VERSION "HNNBNNNYNNNNNNNNNNNNNNNNNNNNNNNNNNNNNNNNNN/4/%%%/4/'%**4NNN///"

NS_ :

BS_:

BU_: AAG BCM1 BCM2 ELV Gateway HDSG IEZS MFG MSBBR SAD SAD2 Schwerpanzer_Zusatz SitzMem_BFS SitzMem_FS SitzMem_HBFS SitzMem_HFS SitzMem_SR3 SpoilerSG TSG_BFS TSG_FS VSG VTS DK_Dummy

BO_ 1639 Mem_BFS_01: 8 SitzMem_BFS
 SG_ BFS_Fond_Bed_Ack : 12|1@1+ (1,0) [0|1] ""  Gateway
 SG_ BFS_Lehne_nicht_verriegelt : 13|1@1+ (1,0) [0|1] ""  Gateway
 SG_ BFS_Klapptisch_offen : 14|1@1+ (1,0) [0|1] ""  Gateway,SitzMem_FS
 SG_ BFS_Sitzsym_Fahrt_aktiv : 16|1@1+ (1,0) [0|1] ""  Gateway,SitzMem_FS
 SG_ BFS_Sitzfahrt_aktiv : 17|1@1+ (1,0) [0|1] ""  Gateway,SitzMem_FS,SitzMem_HBFS
 SG_ BFS_SLV_aktiv : 18|1@1+ (1,0) [0|1] ""  Gateway
 SG_ BFS_SHV_aktiv : 19|1@1+ (1,0) [0|1] ""  Gateway
 SG_ BFS_LNV_aktiv : 20|1@1+ (1,0) [0|1] ""  Gateway
 SG_ BFS_SNV_aktiv : 21|1@1+ (1,0) [0|1] ""  Gateway
 SG_ BFS_KSV_aktiv : 22|1@1+ (1,0) [0|1] ""  Gateway
 SG_ BFS_LKV_aktiv : 23|1@1+ (1,0) [0|1] ""  Gateway
 SG_ BFS_STV_aktiv : 24|1@1+ (1,0) [0|1] ""  Gateway
 SG_ BFS_LHV_aktiv : 25|1@1+ (1,0) [0|1] ""  Gateway
 SG_ BFS_LWV_aktiv : 26|1@1+ (1,0) [0|1] ""  Gateway
 SG_ BFS_GHV_aktiv : 27|1@1+ (1,0) [0|1] ""  Gateway
 SG_ BFS_KSS_Fahrt_aktiv : 28|1@1+ (1,0) [0|1] ""  Gateway,SitzMem_FS
 SG_ BFS_MMB_lokal_Stop : 29|1@1+ (1,0) [0|1] ""  Gateway
 SG_ BFS_Ruhestellung_Status : 30|1@1+ (1,0) [0|1] ""  Gateway,SitzMem_FS,SitzMem_HBFS
 SG_ BFS_Seat_Locked : 31|1@1+ (1,0) [0|1] ""  Gateway
 SG_ BFS_MMB_storage : 32|4@1+ (1,0) [0|15] ""  Gateway
 SG_ BFS_MMB_tipp : 36|1@1+ (1,0) [0|1] ""  Gateway
 SG_ BFS_MMB_tast : 37|1@1+ (1,0) [0|1] ""  Gateway
 SG_ BFS_MMB_store_LED_on : 38|1@1+ (1,0) [0|1] ""  Gateway,TSG_BFS
 SG_ BFS_MMB_storage_beep : 39|1@1+ (1,0) [0|1] ""  Gateway
 SG_ BFS_MMB_store : 40|1@1+ (1,0) [0|1] ""  Gateway
 SG_ BFS_MMB_glob_stop : 41|1@1+ (1,0) [0|1] ""  Gateway

BO_ 957 Mem_BFS_Fond_01: 8 SitzMem_HBFS
 SG_ Mem_BFSFo_Lordose_hoch : 12|1@1+ (1,0) [0|1] ""  Gateway
 SG_ Mem_BFSFo_Lordose_runter : 13|1@1+ (1,0) [0|1] ""  Gateway
 SG_ Mem_BFSFo_Lordose_vor : 14|1@1+ (1,0) [0|1] ""  Gateway
 SG_ Mem_BFSFo_Lordose_zurueck : 15|1@1+ (1,0) [0|1] ""  Gateway
 SG_ Mem_BFSFo_Massage_Geschw : 16|3@1+ (1,0) [0|7] ""  Gateway,SitzMem_FS
 SG_ Mem_BFSFo_Massage_Intens : 19|3@1+ (1,0) [0|7] ""  Gateway,SitzMem_FS
 SG_ Mem_BFSFo_MMB_storage : 22|2@1+ (1,0) [0|3] ""  Gateway
 SG_ Mem_BFSFo_Massage_Prg : 24|3@1+ (1,0) [0|7] ""  Gateway,SitzMem_FS
 SG_ Mem_BFSFo_MMB_tast : 27|1@1+ (1,0) [0|1] ""  Gateway
 SG_ Mem_BFSFo_MMB_tipp : 28|1@1+ (1,0) [0|1] ""  Gateway
 SG_ Mem_BFSFo_MMB_glob_Stop : 29|1@1+ (1,0) [0|1] ""  Gateway
 SG_ Mem_BFSFo_Sitztiefe_vor : 30|1@1+ (1,0) [0|1] ""  Gateway
 SG_ Mem_BFSFo_Sitztiefe_zur : 31|1@1+ (1,0) [0|1] ""  Gateway
 SG_ Mem_BFSFo_MMB_store : 32|1@1+ (1,0) [0|1] ""  Gateway
 SG_ Mem_BFSFo_MMB_storage_beep : 33|1@1+ (1,0) [0|1] ""  Gateway
 SG_ Mem_BFSFo_MMB_store_LED_on : 34|1@1+ (1,0) [0|1] ""  Gateway,TSG_BFS,TSG_FS
 SG_ Mem_BFSFo_BeifaSitzverstellung : 35|1@1+ (1,0) [0|1] ""  Gateway
 SG_ Mem_BFSFo_MMB_lokal_Stop : 36|1@1+ (1,0) [0|1] ""  Gateway
 SG_ Mem_BFSFo_Sitzfahrt_aktiv : 37|1@1+ (1,0) [0|1] ""  Gateway,SitzMem_BFS,SitzMem_FS
 SG_ Mem_BFSFo_BFS_Freigabe : 38|1@1+ (1,0) [0|1] ""  Gateway,SitzMem_BFS
 SG_ Mem_BFSFo_RSE_zurueck : 40|1@1+ (1,0) [0|1] ""  Gateway,SitzMem_BFS
 SG_ Mem_BFSFo_RSE_vor : 41|1@1+ (1,0) [0|1] ""  Gateway,SitzMem_BFS
 SG_ Mem_BFSFo_Business_anfahren : 42|1@1+ (1,0) [0|1] ""  Gateway,SitzMem_BFS
 SG_ Mem_BFSFo_Relax_anfahren : 43|1@1+ (1,0) [0|1] ""  Gateway,SitzMem_BFS
 SG_ BFS_Kopfstuetze_vor : 44|1@1+ (1,0) [0|1] ""  Gateway,SitzMem_BFS
 SG_ BFS_Kopfstuetze_zurueck : 45|1@1+ (1,0) [0|1] ""  Gateway,SitzMem_BFS
 SG_ Mem_BFSFo_BFS_RSE_Freigabe : 48|1@1+ (1,0) [0|1] ""  Gateway,SitzMem_BFS
 SG_ Mem_BFSFo_Fusstuetze_runter : 49|1@1+ (1,0) [0|1] ""  Gateway,SitzMem_BFS
 SG_ Mem_BFSFo_Fusstuetze_hoch : 50|1@1+ (1,0) [0|1] ""  Gateway,SitzMem_BFS

BO_ 1178 Mem_FS_01: 8 SitzMem_FS
 SG_ FS_Fond_Bed_enable : 12|1@1+ (1,0) [0|1] ""  Gateway,SitzMem_BFS,SitzMem_HBFS
 SG_ FS_Lehne_nicht_verriegelt : 13|1@1+ (1,0) [0|1] ""  Gateway
 SG_ FS_Spezialposition_anfahren : 14|1@1+ (1,0) [0|1] ""  Gateway,SitzMem_BFS,SitzMem_HBFS,SitzMem_HFS
 SG_ FS_BFS_Sitzsym_Anfahrt : 16|1@1+ (1,0) [0|1] ""  Gateway,SitzMem_BFS
 SG_ FS_Sitzfahrt_aktiv : 17|1@1+ (1,0) [0|1] ""  BCM1,Gateway,TSG_BFS,TSG_FS
 SG_ FS_SLV_aktiv : 18|1@1+ (1,0) [0|1] ""  Gateway
 SG_ FS_SHV_aktiv : 19|1@1+ (1,0) [0|1] ""  Gateway
 SG_ FS_LNV_aktiv : 20|1@1+ (1,0) [0|1] ""  Gateway
 SG_ FS_SNV_aktiv : 21|1@1+ (1,0) [0|1] ""  Gateway
 SG_ FS_KSV_aktiv : 22|1@1+ (1,0) [0|1] ""  Gateway
 SG_ FS_LKV_aktiv : 23|1@1+ (1,0) [0|1] ""  Gateway
 SG_ FS_STV_aktiv : 24|1@1+ (1,0) [0|1] ""  Gateway
 SG_ FS_LHV_aktiv : 25|1@1+ (1,0) [0|1] ""  Gateway
 SG_ FS_LWV_aktiv : 26|1@1+ (1,0) [0|1] ""  Gateway
 SG_ FS_GHV_aktiv : 27|1@1+ (1,0) [0|1] ""  Gateway
 SG_ FS_BFS_KSS_Anfahrt : 28|1@1+ (1,0) [0|1] ""  Gateway,SitzMem_BFS
 SG_ FS_MMB_lokal_Stop : 29|1@1+ (1,0) [0|1] ""  Gateway
 SG_ FS_MMB_storage : 32|4@1+ (1,0) [0|15] ""  BCM1,Gateway,TSG_BFS,TSG_FS
 SG_ FS_MMB_tipp : 36|1@1+ (1,0) [0|1] ""  BCM1,Gateway,TSG_BFS,TSG_FS
 SG_ FS_MMB_tast : 37|1@1+ (1,0) [0|1] ""  BCM1,Gateway,TSG_BFS,TSG_FS
 SG_ FS_MMB_store_LED_on : 38|1@1+ (1,0) [0|1] ""  Gateway,TSG_FS
 SG_ FS_MMB_storage_beep : 39|1@1+ (1,0) [0|1] ""  Gateway
 SG_ FS_MMB_store : 40|1@1+ (1,0) [0|1] ""  BCM1,Gateway,TSG_BFS,TSG_FS
 SG_ FS_MMB_glob_stop : 41|1@1+ (1,0) [0|1] ""  BCM1,Gateway,SitzMem_BFS,SitzMem_HBFS,SitzMem_HFS,TSG_BFS,TSG_FS
 SG_ FS_EE_Fond_FS_enable : 42|1@1+ (1,0) [0|1] ""  Gateway,SitzMem_HBFS,SitzMem_HFS
 SG_ FS_EE_Fond_BFS_enable : 43|1@1+ (1,0) [0|1] ""  Gateway,SitzMem_HBFS,SitzMem_HFS
 SG_ FS_BFS_Fond_Verst_enable : 44|1@1+ (1,0) [0|1] ""  Gateway,SitzMem_BFS,SitzMem_HBFS
 SG_ FS_EE_BFS_enable : 45|1@1+ (1,0) [0|1] ""  Gateway

BO_ 954 Mem_FS_02: 8 SitzMem_FS
 SG_ Mem_FS_Lordose_hoch : 12|1@1+ (1,0) [0|1] "" Vector__XXX
 SG_ Mem_FS_Lordose_runter : 13|1@1+ (1,0) [0|1] "" Vector__XXX
 SG_ Mem_FS_Lordose_vor : 14|1@1+ (1,0) [0|1] "" Vector__XXX
 SG_ Mem_FS_Lordose_zurueck : 15|1@1+ (1,0) [0|1] "" Vector__XXX
 SG_ Mem_FS_Massage_Geschw : 16|3@1+ (1,0) [0|7] "" Vector__XXX
 SG_ Mem_FS_Massage_Intensitaet : 19|3@1+ (1,0) [0|7] "" Vector__XXX
 SG_ Mem_FS_SWangenLehne_beluef : 22|1@1+ (1,0) [0|1] "" Vector__XXX
 SG_ Mem_FS_SWangenLehne_entlue : 23|1@1+ (1,0) [0|1] "" Vector__XXX
 SG_ Mem_FS_Massage_Programm : 24|3@1+ (1,0) [0|7] "" Vector__XXX
 SG_ Mem_FS_SWangenSitz_beluef : 27|1@1+ (1,0) [0|1] "" Vector__XXX
 SG_ Mem_FS_SWangenSitz_entlue : 28|1@1+ (1,0) [0|1] "" Vector__XXX
 SG_ FS_BFS_aufraeumen : 29|1@1+ (1,0) [0|1] ""  SitzMem_BFS
 SG_ FS_BFSFo_aufraeumen : 30|1@1+ (1,0) [0|1] ""  SitzMem_HBFS
 SG_ FS_FSFo_aufraeumen : 31|1@1+ (1,0) [0|1] ""  SitzMem_HFS
 SG_ FS_BFS_Multifunktionstaster_hoch : 32|1@1+ (1,0) [0|1] ""  SitzMem_BFS
 SG_ FS_BFS_Multifunktionstaster_tief : 33|1@1+ (1,0) [0|1] ""  SitzMem_BFS
 SG_ FS_BFS_Multifunktionstaster_vor : 34|1@1+ (1,0) [0|1] ""  SitzMem_BFS
 SG_ FS_BFS_Multifunktionstaster_zur : 35|1@1+ (1,0) [0|1] ""  SitzMem_BFS
 SG_ FS_BFS_Programmwippe_hoch : 36|1@1+ (1,0) [0|1] ""  SitzMem_BFS
 SG_ FS_BFS_Programmwippe_tief : 37|1@1+ (1,0) [0|1] ""  SitzMem_BFS
 SG_ FS_BFS_SHV_Taste_hoch : 38|1@1+ (1,0) [0|1] ""  SitzMem_BFS
 SG_ FS_BFS_SHV_Taste_tief : 39|1@1+ (1,0) [0|1] ""  SitzMem_BFS
 SG_ FS_BFS_SLV_Taste_vor : 40|1@1+ (1,0) [0|1] ""  SitzMem_BFS
 SG_ FS_BFS_SLV_Taste_zurueck : 41|1@1+ (1,0) [0|1] ""  SitzMem_BFS
 SG_ FS_BFS_SNV_Taste_hoch : 42|1@1+ (1,0) [0|1] ""  SitzMem_BFS
 SG_ FS_BFS_SNV_Taste_tief : 43|1@1+ (1,0) [0|1] ""  SitzMem_BFS
 SG_ FS_BFS_KSV_Taste_hoch : 44|1@1+ (1,0) [0|1] ""  SitzMem_BFS
 SG_ FS_BFS_KSV_Taste_tief : 45|1@1+ (1,0) [0|1] ""  SitzMem_BFS
 SG_ FS_BFS_LNV_Taste_vor : 46|1@1+ (1,0) [0|1] ""  SitzMem_BFS
 SG_ FS_BFS_LNV_Taste_zurueck : 47|1@1+ (1,0) [0|1] ""  SitzMem_BFS
 SG_ FS_BFS_Massage_Taste : 48|1@1+ (1,0) [0|1] ""  SitzMem_BFS

BO_ 956 Mem_FS_Fond_01: 8 SitzMem_HFS
 SG_ Mem_FSFo_Lordose_hoch : 12|1@1+ (1,0) [0|1] ""  Gateway
 SG_ Mem_FSFo_Lordose_runter : 13|1@1+ (1,0) [0|1] ""  Gateway
 SG_ Mem_FSFo_Lordose_vor : 14|1@1+ (1,0) [0|1] ""  Gateway
 SG_ Mem_FSFo_Lordose_zurueck : 15|1@1+ (1,0) [0|1] ""  Gateway
 SG_ Mem_FSFo_Massage_Geschw : 16|3@1+ (1,0) [0|7] ""  Gateway,SitzMem_FS
 SG_ Mem_FSFo_Massage_Intens : 19|3@1+ (1,0) [0|7] ""  Gateway,SitzMem_FS
 SG_ Mem_FSFo_MMB_storage : 22|2@1+ (1,0) [0|3] ""  Gateway
 SG_ Mem_FSFo_Massage_Prg : 24|3@1+ (1,0) [0|7] ""  Gateway,SitzMem_FS
 SG_ Mem_FSFo_MMB_tast : 27|1@1+ (1,0) [0|1] ""  Gateway
 SG_ Mem_FSFo_MMB_tipp : 28|1@1+ (1,0) [0|1] ""  Gateway
 SG_ Mem_FSFo_MMB_glob_Stop : 29|1@1+ (1,0) [0|1] ""  Gateway
 SG_ Mem_FSFo_Sitztiefe_vor : 30|1@1+ (1,0) [0|1] ""  Gateway
 SG_ Mem_FSFo_Sitztiefe_zur : 31|1@1+ (1,0) [0|1] ""  Gateway
 SG_ Mem_FSFo_MMB_store : 32|1@1+ (1,0) [0|1] ""  Gateway
 SG_ Mem_FSFo_MMB_storage_beep : 33|1@1+ (1,0) [0|1] ""  Gateway
 SG_ Mem_FSFo_MMB_store_LED_on : 34|1@1+ (1,0) [0|1] ""  Gateway,TSG_BFS,TSG_FS
 SG_ Mem_FSFo_MMB_lokal_Stop : 36|1@1+ (1,0) [0|1] ""  Gateway
 SG_ Mem_FSFo_Sitzfahrt_aktiv : 37|1@1+ (1,0) [0|1] ""  Gateway,SitzMem_FS
 SG_ Mem_FSFo_Business_anfahren : 42|1@1+ (1,0) [0|1] ""  Gateway
 SG_ Mem_FSFo_Relax_anfahren : 43|1@1+ (1,0) [0|1] ""  Gateway

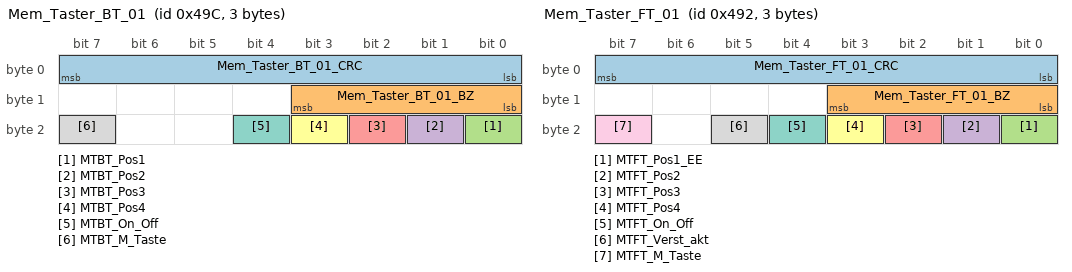
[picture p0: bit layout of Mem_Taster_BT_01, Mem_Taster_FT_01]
BO_ 1180 Mem_Taster_BT_01: 3 TSG_BFS
 SG_ Mem_Taster_BT_01_CRC : 0|8@1+ (1,0) [0|255] ""  SitzMem_BFS,SitzMem_FS
 SG_ Mem_Taster_BT_01_BZ : 8|4@1+ (1,0) [0|15] ""  SitzMem_BFS,SitzMem_FS
 SG_ MTBT_Pos1 : 16|1@1+ (1,0) [0|1] ""  SitzMem_BFS,SitzMem_FS,SitzMem_HBFS
 SG_ MTBT_Pos2 : 17|1@1+ (1,0) [0|1] ""  SitzMem_BFS,SitzMem_FS,SitzMem_HBFS
 SG_ MTBT_Pos3 : 18|1@1+ (1,0) [0|1] ""  SitzMem_BFS,SitzMem_FS,SitzMem_HBFS
 SG_ MTBT_Pos4 : 19|1@1+ (1,0) [0|1] ""  SitzMem_BFS,SitzMem_FS
 SG_ MTBT_On_Off : 20|1@1+ (1,0) [0|1] ""  SitzMem_BFS,SitzMem_FS
 SG_ MTBT_M_Taste : 23|1@1+ (1,0) [0|1] ""  SitzMem_BFS,SitzMem_FS,SitzMem_HBFS

BO_ 1170 Mem_Taster_FT_01: 3 TSG_FS
 SG_ Mem_Taster_FT_01_CRC : 0|8@1+ (1,0) [0|255] ""  SitzMem_FS
 SG_ Mem_Taster_FT_01_BZ : 8|4@1+ (1,0) [0|15] ""  SitzMem_FS
 SG_ MTFT_Pos1_EE : 16|1@1+ (1,0) [0|1] ""  SitzMem_FS
 SG_ MTFT_Pos2 : 17|1@1+ (1,0) [0|1] ""  SitzMem_FS
 SG_ MTFT_Pos3 : 18|1@1+ (1,0) [0|1] ""  SitzMem_FS
 SG_ MTFT_Pos4 : 19|1@1+ (1,0) [0|1] ""  SitzMem_FS
 SG_ MTFT_On_Off : 20|1@1+ (1,0) [0|1] ""  SitzMem_FS
 SG_ MTFT_Verst_akt : 21|1@1+ (1,0) [0|1] ""  SitzMem_FS
 SG_ MTFT_M_Taste : 23|1@1+ (1,0) [0|1] ""  SitzMem_FS

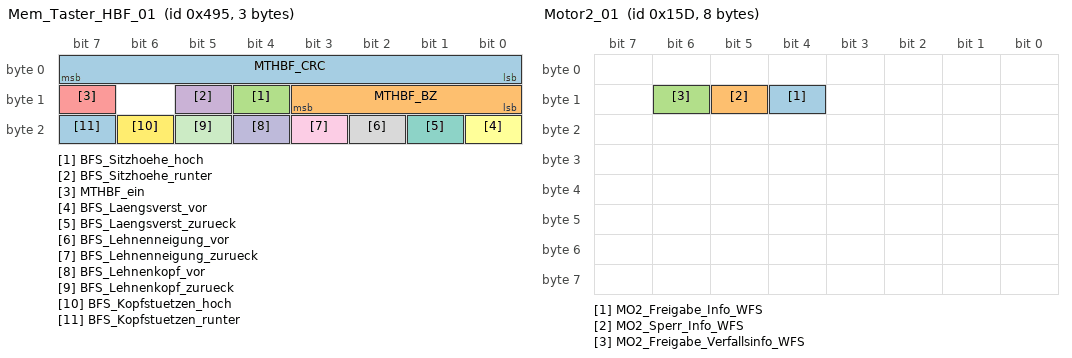
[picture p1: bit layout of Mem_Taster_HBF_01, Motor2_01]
BO_ 1173 Mem_Taster_HBF_01: 3 SitzMem_HBFS
 SG_ MTHBF_CRC : 0|8@1+ (1,0) [0|255] ""  SitzMem_BFS
 SG_ MTHBF_BZ : 8|4@1+ (1,0) [0|15] ""  SitzMem_BFS
 SG_ BFS_Sitzhoehe_hoch : 12|1@1+ (1,0) [0|1] ""  SitzMem_BFS
 SG_ BFS_Sitzhoehe_runter : 13|1@1+ (1,0) [0|1] ""  SitzMem_BFS
 SG_ MTHBF_ein : 15|1@1+ (1,0) [0|1] ""  SitzMem_BFS
 SG_ BFS_Laengsverst_vor : 16|1@1+ (1,0) [0|1] ""  SitzMem_BFS
 SG_ BFS_Laengsverst_zurueck : 17|1@1+ (1,0) [0|1] ""  SitzMem_BFS
 SG_ BFS_Lehnenneigung_vor : 18|1@1+ (1,0) [0|1] ""  SitzMem_BFS
 SG_ BFS_Lehnenneigung_zurueck : 19|1@1+ (1,0) [0|1] ""  SitzMem_BFS
 SG_ BFS_Lehnenkopf_vor : 20|1@1+ (1,0) [0|1] ""  SitzMem_BFS
 SG_ BFS_Lehnenkopf_zurueck : 21|1@1+ (1,0) [0|1] ""  SitzMem_BFS
 SG_ BFS_Kopfstuetzen_hoch : 22|1@1+ (1,0) [0|1] ""  SitzMem_BFS
 SG_ BFS_Kopfstuetzen_runter : 23|1@1+ (1,0) [0|1] ""  SitzMem_BFS

BO_ 1171 MFG_01: 8 MFG
 SG_ MFG_01_CRC : 0|8@1+ (1,0) [0|255] ""  BCM1,BCM2,Gateway,TSG_FS
 SG_ MFG_01_BZ : 8|4@1+ (1,0) [0|15] ""  BCM1,BCM2,Gateway,TSG_FS
 SG_ MF_ZV_Lock : 12|1@1+ (1,0) [0|1] ""  BCM2,Gateway
 SG_ MF_Motorweiterlauf : 13|1@1+ (1,0) [0|1] ""  BCM2,Gateway
 SG_ MF_Abzugssperre : 14|1@1+ (1,0) [0|1] ""  BCM2,Gateway
 SG_ MF_Anlassersperre : 15|1@1+ (1,0) [0|1] ""  BCM2,Gateway
 SG_ MF_Variante : 16|3@1+ (1,0) [0|7] ""  BCM1,BCM2,Gateway,TSG_BFS,TSG_FS
 SG_ MF_Schluessel_scan : 19|1@1+ (1,0) [0|1] ""  Gateway
 SG_ MF_Laderelais : 20|1@1+ (1,0) [0|1] ""  Gateway
 SG_ MF_StartStopp_Info : 21|2@1+ (1,0) [0|3] ""  Gateway
 SG_ MF_Fernbed_ein : 23|1@1+ (1,0) [0|1] ""  BCM1,BCM2,Gateway,TSG_BFS,TSG_FS
 SG_ MF_Standlicht : 24|1@1+ (1,0) [0|1] ""  BCM1,Gateway
 SG_ MF_Fahrlicht : 25|1@1+ (1,0) [0|1] ""  BCM1,Gateway
 SG_ MF_interm_Fernlicht : 26|1@1+ (1,0) [0|1] ""  BCM1,Gateway
 SG_ MF_Warnblinker : 27|1@1+ (1,0) [0|1] ""  BCM1,BCM2,Gateway
 SG_ MF_Fussraumbel : 28|1@1+ (1,0) [0|1] ""  BCM1,Gateway,TSG_FS
 SG_ MF_Innenraumbel : 29|1@1+ (1,0) [0|1] ""  BCM1,Gateway,TSG_BFS,TSG_FS
 SG_ MF_Innenraumbel_Unterdrueck : 30|1@1+ (1,0) [0|1] ""  BCM1,Gateway,TSG_BFS,TSG_FS
 SG_ MF_Notstart : 31|1@1+ (1,0) [0|1] ""  Gateway
 SG_ MF_Blk_li : 32|1@1+ (1,0) [0|1] ""  BCM2,Gateway
 SG_ MF_Blk_re : 33|1@1+ (1,0) [0|1] ""  BCM2,Gateway
 SG_ MF_Lichthupe : 34|1@1+ (1,0) [0|1] ""  BCM1,Gateway
 SG_ MF_Fernlicht : 35|1@1+ (1,0) [0|1] ""  BCM1,Gateway
 SG_ MF_HFS_verriegeln : 36|1@1+ (1,0) [0|1] ""  Gateway,TSG_FS
 SG_ MF_HFS_entriegeln : 37|1@1+ (1,0) [0|1] ""  Gateway,TSG_FS
 SG_ MF_HBFS_verriegeln : 38|1@1+ (1,0) [0|1] ""  Gateway,TSG_BFS
 SG_ MF_HBFS_entriegeln : 39|1@1+ (1,0) [0|1] ""  Gateway,TSG_BFS
 SG_ MF_Tippwischen : 40|1@1+ (1,0) [0|1] ""  BCM1,Gateway
 SG_ MF_Frontintervall : 41|1@1+ (1,0) [0|1] ""  BCM1,Gateway
 SG_ MF_Wischerstufe_1 : 42|1@1+ (1,0) [0|1] ""  BCM1,Gateway
 SG_ MF_Wischerstufe_2 : 43|1@1+ (1,0) [0|1] ""  BCM1,Gateway
 SG_ MF_Frontwaschen : 44|1@1+ (1,0) [0|1] ""  BCM1,Gateway
 SG_ MF_Heckintervall : 46|1@1+ (1,0) [0|1] ""  BCM1,Gateway
 SG_ MF_Heckwaschen : 47|1@1+ (1,0) [0|1] ""  BCM1,Gateway
 SG_ MF_Summer : 48|1@1+ (1,0) [0|1] ""  Gateway
 SG_ MF_Alarm_Blinkertakt : 49|1@1+ (1,0) [0|1] ""  Gateway
 SG_ MF_Alarm_Blinker : 50|1@1+ (1,0) [0|1] ""  BCM2,Gateway,VTS
 SG_ MF_TFL_Abschaltung : 51|1@1+ (1,0) [0|1] ""  BCM1,Gateway
 SG_ MF_interm_Takt : 52|1@1+ (1,0) [0|1] ""  Gateway
 SG_ MF_Tuerentriegelung_hinten : 53|1@1+ (1,0) [0|1] ""  Gateway
 SG_ MF_interm_Fahrlicht : 54|1@1+ (1,0) [0|1] ""  Gateway
 SG_ MF_Signalhorn : 55|1@1+ (1,0) [0|1] ""  BCM1,Gateway
 SG_ MF_FH_FT_hoch : 56|1@1+ (1,0) [0|1] ""  Gateway,TSG_FS
 SG_ MF_FH_FT_tief : 57|1@1+ (1,0) [0|1] ""  Gateway,TSG_FS
 SG_ MF_FH_BT_hoch : 58|1@1+ (1,0) [0|1] ""  Gateway,TSG_BFS
 SG_ MF_FH_BT_tief : 59|1@1+ (1,0) [0|1] ""  Gateway,TSG_BFS
 SG_ MF_FT_verriegeln : 60|1@1+ (1,0) [0|1] ""  Gateway,TSG_FS
 SG_ MF_FT_entriegeln : 61|1@1+ (1,0) [0|1] ""  Gateway,TSG_FS
 SG_ MF_BT_verriegeln : 62|1@1+ (1,0) [0|1] ""  Gateway,TSG_BFS
 SG_ MF_BT_entriegeln : 63|1@1+ (1,0) [0|1] ""  Gateway,TSG_BFS

BO_ 817 MFL_01: 8 Gateway
 SG_ MFL_Zaehler : 0|4@1+ (1,0) [0|15] "" Vector__XXX
 SG_ MFL_Toggle : 4|1@1+ (1,0) [0|1] "" Vector__XXX
 SG_ MFL_Lokalaktiv : 5|1@1+ (1,0) [0|1] "" Vector__XXX
 SG_ MFL_M_Taste : 6|1@1+ (1,0) [0|1] "" Vector__XXX
 SG_ MFL_Tastencode_1 : 8|8@1+ (1,0) [0|255] "" Vector__XXX
 SG_ MFL_Tastencode_2 : 16|8@1+ (1,0) [0|255] "" Vector__XXX
 SG_ MFL_Eventcode_1 : 24|4@1+ (1,0) [0|15] "" Vector__XXX
 SG_ MFL_Eventcode_2 : 28|4@1+ (1,0) [0|15] "" Vector__XXX
 SG_ MFL_Marke : 32|4@1+ (1,0) [0|15] "" Vector__XXX
 SG_ MFL_Variante : 36|4@1+ (1,0) [0|15] "" Vector__XXX
 SG_ MFL_Dummy_0_Signal_1 : 40|8@1+ (1,0) [0|255] "" Vector__XXX
 SG_ MFL_Tip_Down : 48|1@1+ (1,0) [0|1] "" Vector__XXX
 SG_ MFL_Tip_Up : 49|1@1+ (1,0) [0|1] "" Vector__XXX
 SG_ MFL_SatModul_links_Err : 50|1@1+ (1,0) [0|1] "" Vector__XXX
 SG_ MFL_SatModul_rechts_Err : 51|1@1+ (1,0) [0|1] "" Vector__XXX
 SG_ MFL_Dummy_0_Signal_2 : 52|1@1+ (1,0) [0|1] "" Vector__XXX
 SG_ MFL_Dummy_0_Signal_3 : 53|1@1+ (1,0) [0|1] "" Vector__XXX
 SG_ MFL_LR_HZG_Status : 54|1@1+ (1,0) [0|1] "" Vector__XXX
 SG_ MFL_LR_HZG_Err : 55|1@1+ (1,0) [0|1] "" Vector__XXX
 SG_ MFL_Signalhorn : 56|1@1+ (1,0) [0|1] ""  BCM1,MFG
 SG_ MFL_Signalhorn_Err : 57|1@1+ (1,0) [0|1] "" Vector__XXX
 SG_ MFL_Tip_links_Err : 58|1@1+ (1,0) [0|1] "" Vector__XXX
 SG_ MFL_Tip_rechts_Err : 59|1@1+ (1,0) [0|1] "" Vector__XXX
 SG_ MFL_Taste_links_Err : 60|1@1+ (1,0) [0|1] "" Vector__XXX
 SG_ MFL_Taste_rechts_Err : 61|1@1+ (1,0) [0|1] "" Vector__XXX
 SG_ MFL_ECU_Err : 62|1@1+ (1,0) [0|1] "" Vector__XXX
 SG_ MFL_Response_Err : 63|1@1+ (1,0) [0|1] "" Vector__XXX

BO_ 349 Motor2_01: 8 Gateway
 SG_ MO2_Freigabe_Info_WFS : 12|1@1+ (1,0) [0|1] ""  BCM2
 SG_ MO2_Sperr_Info_WFS : 13|1@1+ (1,0) [0|1] ""  BCM2
 SG_ MO2_Freigabe_Verfallsinfo_WFS : 14|1@1+ (1,0) [0|1] ""  BCM2

BO_ 1600 Motor_07: 8 Gateway
 SG_ MO_QBit_Ansaugluft_Temp : 0|1@1+ (1,0) [0|1] "" Vector__XXX
 SG_ MO_QBit_Oel_Temp : 1|1@1+ (1,0) [0|1] "" Vector__XXX
 SG_ MO_QBit_Kuehlmittel_Temp : 2|1@1+ (1,0) [0|1] "" Vector__XXX
 SG_ MO_KL15_Abschaltempfehlung : 3|1@1+ (1,0) [0|1] ""  BCM2
 SG_ MO_HYB_Fehler_HV_Netz : 4|1@1+ (1,0) [0|1] "" Vector__XXX
 SG_ MO_aktives_Getriebeheizen : 5|1@1+ (1,0) [0|1] "" Vector__XXX
 SG_ MO_Absperrventil_oeffnen : 6|2@1+ (1,0) [0|3] ""  BCM1
 SG_ MO_Ansaugluft_Temp : 8|8@1+ (0.75,-48) [-48|141.75] "Unit_DegreCelsi" Vector__XXX
 SG_ MO_Oel_Temp : 16|8@1+ (1,-60) [-60|192] "Unit_DegreCelsi"  VTS
 SG_ MO_Kuehlmittel_Temp : 24|8@1+ (0.75,-48) [-48|141.75] "Unit_DegreCelsi"  BCM2,VTS
 SG_ MO_Hoeheninfo : 32|8@1+ (0.00781,0) [0|1.98374] "" Vector__XXX
 SG_ MO_Kennfeldk : 40|1@1+ (1,0) [0|1] "" Vector__XXX
 SG_ MO_Versionsinfo_02 : 41|5@1+ (1,0) [0|31] "" Vector__XXX
 SG_ MO_QBit_Hoeheninfo : 46|1@1+ (1,0) [0|1] "" Vector__XXX
 SG_ MO_Getriebe_kuehlen : 47|1@1+ (1,0) [0|1] "" Vector__XXX
 SG_ MO_Mom_Traegheit_02 : 48|5@1+ (0.01,0) [0|0.31] "Unit_KiloGramMeterSquar" Vector__XXX
 SG_ MO_Heizungspumpenansteuerung : 53|4@1+ (10,0) [0|100] "Unit_PerCent"  BCM1
 SG_ MO_SpannungsAnf : 57|1@1+ (1,0) [0|1] "" Vector__XXX
 SG_ MO_Nachlaufzeit_Heizungspumpe : 58|6@1+ (15,0) [0|945] "Unit_Secon"  BCM1

BO_ 1607 Motor_09: 8 Gateway
 SG_ MO_ITM_Kuehlmittel_Temp : 0|8@1+ (0.75,-48) [-45.75|143.25] "Unit_DegreCelsi" Vector__XXX
 SG_ MO_E85_Sensor : 8|4@1+ (10,0) [0|100] "Unit_PerCent" Vector__XXX
 SG_ SCR_Anz_Motorstarts : 12|4@1+ (1,0) [0|15] ""  BCM2
 SG_ SCR_Reichweite : 16|15@1+ (1,0) [0|32766] "Unit_KiloMeter" Vector__XXX
 SG_ MO_Ethanol_Spuelhinweis : 31|1@1+ (1,0) [0|1] "" Vector__XXX
 SG_ SCR_Warnstufe_1 : 32|1@1+ (1,0) [0|1] "" Vector__XXX
 SG_ SCR_Warnstufe_2 : 33|1@1+ (1,0) [0|1] "" Vector__XXX
 SG_ SCR_Text : 34|3@1+ (1,0) [0|7] "" Vector__XXX
 SG_ SCR_Akustik : 37|2@1+ (1,0) [0|3] "" Vector__XXX
 SG_ SCR_verbaut : 39|1@1+ (1,0) [0|1] ""  BCM2
 SG_ MO_Kraftstofffilter_Wasser : 40|1@1+ (1,0) [0|1] "" Vector__XXX
 SG_ SCR_Systemfehler : 41|1@1+ (1,0) [0|1] "" Vector__XXX
 SG_ SCR_Inducement_Strategie : 42|2@1+ (1,0) [0|3] "" Vector__XXX
 SG_ MO_CO2_Faktor : 44|12@1+ (1,0) [1|4094] "Unit_GramPerLiter" Vector__XXX
 SG_ MO_MKB_MUX M : 56|2@1+ (1,0) [0|3] "" Vector__XXX
 SG_ MO_MKB_01 m0 : 59|5@1+ (1,0) [0|31] "" Vector__XXX
 SG_ MO_MKB_02 m1 : 59|5@1+ (1,0) [0|31] "" Vector__XXX
 SG_ MO_MKB_03 m2 : 59|5@1+ (1,0) [0|31] "" Vector__XXX
 SG_ MO_MKB_04 m3 : 59|5@1+ (1,0) [0|31] "" Vector__XXX

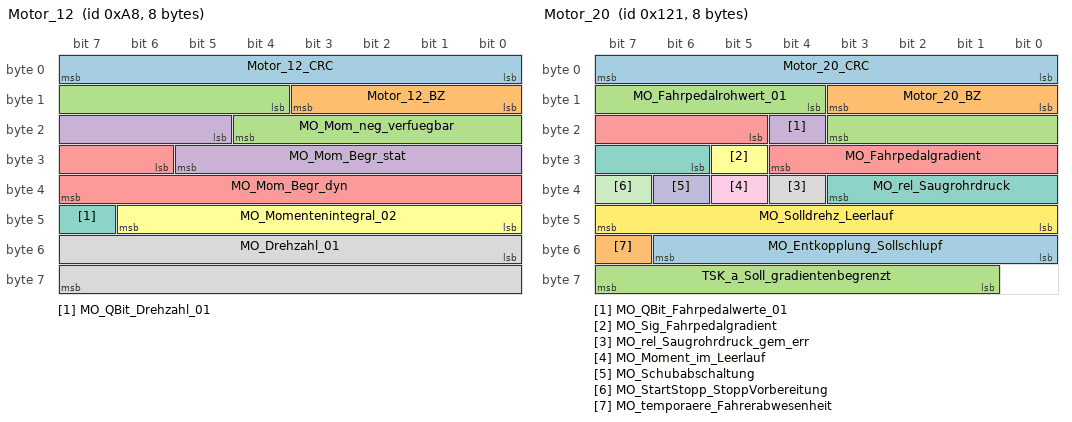
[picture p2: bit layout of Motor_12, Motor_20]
BO_ 168 Motor_12: 8 Gateway
 SG_ Motor_12_CRC : 0|8@1+ (1,0) [0|255] "" Vector__XXX
 SG_ Motor_12_BZ : 8|4@1+ (1,0) [0|15] "" Vector__XXX
 SG_ MO_Mom_neg_verfuegbar : 12|9@1+ (1,-509) [-509|0] "" Vector__XXX
 SG_ MO_Mom_Begr_stat : 21|9@1+ (1,0) [0|509] "" Vector__XXX
 SG_ MO_Mom_Begr_dyn : 30|10@1+ (1,-509) [-509|509] "" Vector__XXX
 SG_ MO_Momentenintegral_02 : 40|7@1+ (1,0) [0|100] "Unit_PerCent" Vector__XXX
 SG_ MO_QBit_Drehzahl_01 : 47|1@1+ (1,0) [0|1] ""  BCM1,BCM2,ELV
 SG_ MO_Drehzahl_01 : 48|16@1+ (0.25,0) [0|16383] "Unit_MinutInver"  BCM1,BCM2,ELV,TSG_BFS,TSG_FS,VSG,VTS

BO_ 958 Motor_14: 8 Gateway
 SG_ Motor_14_CRC : 0|8@1+ (1,0) [0|255] ""  BCM2
 SG_ Motor_14_BZ : 8|4@1+ (1,0) [0|15] ""  BCM2
 SG_ MO_StartStopp_Status : 12|2@1+ (1,0) [0|3] ""  BCM1,BCM2
 SG_ MO_StartStopp_Wiederstart : 14|1@1+ (1,0) [0|1] ""  BCM1,BCM2,HDSG,MFG,SAD,SAD2,SitzMem_BFS,SitzMem_FS,SitzMem_HBFS,SitzMem_HFS,SitzMem_SR3,SpoilerSG,TSG_BFS,TSG_FS,VSG,VTS
 SG_ MO_StartStopp_Motorstopp : 15|1@1+ (1,0) [0|1] ""  BCM1,BCM2,HDSG,MFG,SAD,SAD2,SitzMem_BFS,SitzMem_FS,SitzMem_HBFS,SitzMem_HFS,SitzMem_SR3,TSG_BFS,TSG_FS,VSG,VTS
 SG_ MO_Freig_Reku : 16|2@1+ (1,0) [0|3] "" Vector__XXX
 SG_ MO_Kl_75 : 18|1@1+ (1,0) [0|1] ""  SAD2,AAG,BCM1,BCM2,HDSG,IEZS,MSBBR,SAD,SitzMem_BFS,SitzMem_FS,SitzMem_HBFS,SitzMem_HFS,SitzMem_SR3,TSG_BFS,TSG_FS,VTS
 SG_ MO_Kl_50 : 19|1@1+ (1,0) [0|1] ""  BCM2,TSG_BFS,TSG_FS
 SG_ MO_Gangposition : 20|4@1+ (1,0) [0|15] ""  BCM1,BCM2,ELV,MFG,TSG_BFS,TSG_FS
 SG_ MO_StartStopp_Fahrerwunsch : 24|2@1+ (1,0) [0|3] ""  BCM1,BCM2
 SG_ MO_HYB_Fahrbereitschaft : 26|1@1+ (1,0) [0|1] ""  BCM1,BCM2,ELV,IEZS
 SG_ MO_Ext_E_Fahrt_aktiv : 27|1@1+ (1,0) [0|1] ""  BCM1
 SG_ MO_Fahrer_bremst : 28|1@1+ (1,0) [0|1] ""  AAG,BCM1,BCM2,MSBBR,SAD,SAD2
 SG_ MO_QBit_Fahrer_bremst : 29|1@1+ (1,0) [0|1] ""  BCM1,BCM2
 SG_ MO_BLS : 30|1@1+ (1,0) [0|1] ""  AAG,BCM1,BCM2,MSBBR
 SG_ MO_Konsistenz_Bremsped : 31|1@1+ (1,0) [0|1] "" Vector__XXX
 SG_ MO_KomFehler_ESP : 32|1@1+ (1,0) [0|1] "" Vector__XXX
 SG_ MO_Klima_Eingr : 33|2@1+ (1,0) [0|3] "" Vector__XXX
 SG_ MO_Aussp_Anlass : 35|1@1+ (1,0) [0|1] ""  BCM2
 SG_ MO_Freig_Anlass : 36|1@1+ (1,0) [0|1] "" Vector__XXX
 SG_ MO_Kuppl_schalter : 37|1@1+ (1,0) [0|1] ""  BCM1,BCM2
 SG_ MO_Interlock : 38|1@1+ (1,0) [0|1] ""  BCM1,BCM2
 SG_ MO_Motor_laeuft : 39|1@1+ (1,0) [0|1] ""  BCM1,BCM2,IEZS,SAD,SAD2,TSG_BFS,TSG_FS
 SG_ MO_Kickdown : 40|1@1+ (1,0) [0|1] "" Vector__XXX
 SG_ MO_QBit_KL_75 : 41|1@1+ (1,0) [0|1] ""  AAG,BCM1,BCM2,HDSG,MSBBR,SAD,SAD2,SitzMem_BFS,SitzMem_FS,SitzMem_HBFS,SitzMem_HFS,SitzMem_SR3
 SG_ MO_EKlKomLeiRed : 42|2@1+ (1,0) [0|3] "" Vector__XXX
 SG_ MO_Handshake_STH : 44|1@1+ (1,0) [0|1] "" Vector__XXX
 SG_ MO_BKV_Unterdruckwarnung : 45|1@1+ (1,0) [0|1] "" Vector__XXX
 SG_ MO_Freigabe_Segeln : 46|1@1+ (1,0) [0|1] "" Vector__XXX
 SG_ MO_PTC_Status : 47|3@1+ (1,0) [0|7] "" Vector__XXX
 SG_ MO_QBit_Gangposition : 50|1@1+ (1,0) [0|1] "" Vector__XXX
 SG_ MO_Signalquelle_Gangposition : 51|1@1+ (1,0) [0|1] "" Vector__XXX
 SG_ MO_Remotestart_Betrieb : 52|1@1+ (1,0) [0|1] ""  BCM2
 SG_ MO_Zylinderabschaltung : 59|2@1+ (1,0) [0|3] "" Vector__XXX
 SG_ MO_HYB_VM_aktiv : 61|1@1+ (1,0) [0|1] "" Vector__XXX
 SG_ MO_StartVorauss_erfuellt : 62|2@1+ (1,0) [0|3] ""  BCM2

BO_ 1648 Motor_18: 8 Gateway
 SG_ MO_max_Ladedruck : 0|6@1+ (0.1,0) [0|6.3] "Unit_Bar" Vector__XXX
 SG_ MO_ANC_Kennfeld_Anf : 6|2@1+ (1,0) [0|3] "" Vector__XXX
 SG_ MO_Bremslicht_Reku : 8|1@1+ (1,0) [0|1] "" Vector__XXX
 SG_ MO_StartStopp_PopUp : 9|2@1+ (1,0) [0|3] "" Vector__XXX
 SG_ MO1_Sperr_Info_WFS : 11|1@1+ (1,0) [0|1] ""  BCM2
 SG_ MO1_Freigabe_Info_WFS : 12|1@1+ (1,0) [0|1] ""  BCM2
 SG_ MO_EPCL : 13|3@1+ (1,0) [0|7] "" Vector__XXX
 SG_ MO_Zylabsch_Texte_02 : 16|4@1+ (1,0) [0|15] "" Vector__XXX
 SG_ MO_Fahrzeugtyp : 20|3@1+ (1,0) [0|7] "" Vector__XXX
 SG_ MO_NMAX_Schaltanzeige : 23|9@1+ (25,0) [0|12775] "Unit_MinutInver" Vector__XXX
 SG_ MO_Abstellzeit : 32|8@1+ (8,0) [0|2024] "Unit_Minut" Vector__XXX
 SG_ MO_Abstellzeit_Status : 40|2@1+ (1,0) [0|3] "" Vector__XXX
 SG_ MO1_Freigabe_Verfallsinfo_WFS : 42|1@1+ (1,0) [0|1] ""  BCM2
 SG_ MO_Hybrid_StartStopp_LED : 43|2@1+ (1,0) [0|3] ""  BCM1
 SG_ MO_Fehler_Zylabsch : 45|2@1+ (1,0) [0|3] "" Vector__XXX
 SG_ MO_Anzahl_Abgesch_Zyl : 47|3@1+ (1,0) [0|7] "" Vector__XXX
 SG_ MO_Zylabsch_Texte : 50|2@1+ (1,0) [0|3] "" Vector__XXX
 SG_ MO_Ethanol_BS_Texte : 52|3@1+ (1,0) [0|7] "" Vector__XXX
 SG_ MO_Drehzahl_Warnung : 55|1@1+ (1,0) [0|1] "" Vector__XXX
 SG_ MO_obere_Drehzahlgrenze : 56|8@1+ (50,0) [50|12750] "Unit_MinutInver" Vector__XXX

BO_ 289 Motor_20: 8 Gateway
 SG_ Motor_20_CRC : 0|8@1+ (1,0) [0|255] "" Vector__XXX
 SG_ Motor_20_BZ : 8|4@1+ (1,0) [0|15] "" Vector__XXX
 SG_ MO_Fahrpedalrohwert_01 : 12|8@1+ (0.4,0) [0|101.6] "Unit_PerCent"  BCM1
 SG_ MO_QBit_Fahrpedalwerte_01 : 20|1@1+ (1,0) [0|1] "" Vector__XXX
 SG_ MO_Fahrpedalgradient : 21|8@1+ (25,0) [0|6350] "Unit_PerCentPerSecon" Vector__XXX
 SG_ MO_Sig_Fahrpedalgradient : 29|1@1+ (1,0) [0|1] "" Vector__XXX
 SG_ MO_rel_Saugrohrdruck : 30|6@1+ (18,0) [0|1116] "Unit_MilliBar" Vector__XXX
 SG_ MO_rel_Saugrohrdruck_gem_err : 36|1@1+ (1,0) [0|1] "" Vector__XXX
 SG_ MO_Moment_im_Leerlauf : 37|1@1+ (1,0) [0|1] "" Vector__XXX
 SG_ MO_Schubabschaltung : 38|1@1+ (1,0) [0|1] "" Vector__XXX
 SG_ MO_StartStopp_StoppVorbereitung : 39|1@1+ (1,0) [0|1] "" Vector__XXX
 SG_ MO_Solldrehz_Leerlauf : 40|8@1+ (10,0) [0|2540] "Unit_MinutInver" Vector__XXX
 SG_ MO_Entkopplung_Sollschlupf : 48|7@1+ (20,0) [0|2500] "Unit_MinutInver" Vector__XXX
 SG_ MO_temporaere_Fahrerabwesenheit : 55|1@1+ (1,0) [0|1] ""  BCM2
 SG_ TSK_a_Soll_gradientenbegrenzt : 57|7@1+ (0.1,-7.2) [-7.2|5.4] "Unit_MeterPerSeconSquar" Vector__XXX

BO_ 967 Motor_26: 8 Gateway
 SG_ MO_Kuehlerluefter_MUX M : 0|1@1+ (1,0) [0|1] "" Vector__XXX
 SG_ MO_Kuehlerluefter_1 m0 : 1|7@1+ (1,0) [0|100] "Unit_PerCent" Vector__XXX
 SG_ MO_Kuehlerluefter_2 m1 : 1|7@1+ (1,0) [0|100] "Unit_PerCent" Vector__XXX
 SG_ MO_EFLEX_Lampe : 8|2@1+ (1,0) [0|3] "" Vector__XXX
 SG_ MO_KJS_nicht_bereit : 10|1@1+ (1,0) [0|1] "" Vector__XXX
 SG_ MO_ITM_Warnung_Pumpe : 11|1@1+ (1,0) [0|1] "" Vector__XXX
 SG_ WIV_Anzeige_aktiv : 12|1@1+ (1,0) [0|1] "" Vector__XXX
 SG_ WIV_Oelmin_Warn : 13|1@1+ (1,0) [0|1] ""  VTS
 SG_ WIV_Sensorfehler : 14|1@1+ (1,0) [0|1] "" Vector__XXX
 SG_ WIV_Schieflage : 15|1@1+ (1,0) [0|1] "" Vector__XXX
 SG_ WIV_Oelstand : 16|4@1+ (12.5,0) [0|100] "Unit_PerCent"  VTS
 SG_ MO_Zustand_HWP : 20|2@1+ (1,0) [0|3] "" Vector__XXX
 SG_ OLEV_Systemstoerung : 22|1@1+ (1,0) [0|1] "" Vector__XXX
 SG_ MO_Oelwarnung_max : 23|1@1+ (1,0) [0|1] "" Vector__XXX
 SG_ WIV_Oelsystem_aktiv : 24|1@1+ (1,0) [0|1] "" Vector__XXX
 SG_ WIV_nicht_betriebswarm : 25|1@1+ (1,0) [0|1] "" Vector__XXX
 SG_ WIV_Ueberfuell_Warn : 26|1@1+ (1,0) [0|1] ""  VTS
 SG_ WIV_laufender_Motor : 27|1@1+ (1,0) [0|1] "" Vector__XXX
 SG_ MO_E_Warnungen : 28|4@1+ (1,0) [0|15] "" Vector__XXX
 SG_ MO_Text_Motorstart : 32|4@1+ (1,0) [0|15] "" Vector__XXX
 SG_ MO_E_Texte : 36|4@1+ (1,0) [0|15] "" Vector__XXX
 SG_ WIV_Oeldyn_avl : 40|1@1+ (1,0) [0|1] "" Vector__XXX
 SG_ MO_Text_Partikelfil_Reg : 41|1@1+ (1,0) [0|1] "" Vector__XXX
 SG_ OLEV_Oelstand_nicht_vorhanden : 42|1@1+ (1,0) [0|1] "" Vector__XXX
 SG_ WIV_Oelmenge : 43|5@1+ (125,0) [0|3875] "Unit_MilliLiter" Vector__XXX
 SG_ MO_Systemlampe : 48|1@1+ (1,0) [0|1] ""  VTS
 SG_ MO_OBD2_Lampe : 49|1@1+ (1,0) [0|1] "" Vector__XXX
 SG_ MO_Heissleuchte : 50|1@1+ (1,0) [0|1] "" Vector__XXX
 SG_ MO_Partikel_Lampe : 51|1@1+ (1,0) [0|1] "" Vector__XXX
 SG_ MO_RedFahrleistung_Lampe : 52|1@1+ (1,0) [0|1] "" Vector__XXX
 SG_ WIV_Oelstand_nicht_vorhanden : 53|1@1+ (1,0) [0|1] "" Vector__XXX
 SG_ WIV_nachfuellanzeige_ein : 54|1@1+ (1,0) [0|1] "" Vector__XXX
 SG_ WIV_Ueberfuell_deaktiv : 55|1@1+ (1,0) [0|1] "" Vector__XXX
 SG_ WIV_Unterfuell_Warn : 56|1@1+ (1,0) [0|1] ""  VTS
 SG_ MO_Tankdeckel_Lampe : 57|1@1+ (1,0) [0|1] "" Vector__XXX
 SG_ MO_Text_Tankdeckelwarn : 58|1@1+ (1,0) [0|1] "" Vector__XXX
 SG_ MO_Vorglueh_Lampe : 59|1@1+ (1,0) [0|1] "" Vector__XXX
 SG_ WIV_Oeldr_Warn_Motor : 60|1@1+ (1,0) [0|1] "" Vector__XXX
 SG_ MO_E_Mode : 61|3@1+ (1,0) [0|7] "" Vector__XXX

BO_TX_BU_ 1173 : SitzMem_HBFS,TSG_BFS;
CM_ BO_ 1639 "MLBevo";
CM_ SG_ 1639 BFS_Lehne_nicht_verriegelt "Fahrer Sitz Lehne Verstellung Verriegelt Status

Verwendung nur im  Bentley";
CM_ SG_ 1639 BFS_Klapptisch_offen "Signalisiert eine Verstelleinschränkung des Beifahrersitz  (für BAP Visualisierung)";
CM_ SG_ 1639 BFS_Sitzsym_Fahrt_aktiv "Sitzsymetriefahrt
";
CM_ SG_ 1639 BFS_Sitzfahrt_aktiv "Aktive Sitzfahrt
";
CM_ SG_ 1639 BFS_SLV_aktiv "Sitzlängsverstellung
";
CM_ SG_ 1639 BFS_SHV_aktiv "Sitzhöhenverstellung
";
CM_ SG_ 1639 BFS_LNV_aktiv "Verstellung Lehnenneigung
";
CM_ SG_ 1639 BFS_SNV_aktiv "Verstellung Sitzneigung
";
CM_ SG_ 1639 BFS_KSV_aktiv "Kopfstuetzenverstellung BFS
";
CM_ SG_ 1639 BFS_LKV_aktiv "Verstellung Lehnenkopf
";
CM_ SG_ 1639 BFS_STV_aktiv "Sitztiefeverstellung
";
CM_ SG_ 1639 BFS_LHV_aktiv "Verstellung Lordose Höhe
";
CM_ SG_ 1639 BFS_LWV_aktiv "Lordose W Verstellung
";
CM_ SG_ 1639 BFS_GHV_aktiv "Verstellung Gurthoehe
";
CM_ SG_ 1639 BFS_KSS_Fahrt_aktiv "Komfortseitensichtfahrt (BFS)";
CM_ SG_ 1639 BFS_MMB_lokal_Stop "mit dem lokal Stop moechte man, dass ein Sitz mit Pneumatik - Lordose sich im Memoryfall wie ein Sitz mit elektromechanischer Lordose verhaelt. Nur lokler Abbruch im TIP-Betrieb.";
CM_ SG_ 1639 BFS_Ruhestellung_Status "dient der Signalisierung für eine Verstelleinschränkung, da der Sitz sich in Ruhestellung befindet.";
CM_ SG_ 1639 BFS_Seat_Locked "Anzeige des gesperrten Beifahrersitzes aufgrund ungültiger Sitzposition.";
CM_ SG_ 1639 BFS_MMB_tast "
";
CM_ SG_ 1639 BFS_MMB_store_LED_on "LED für Speichern
";
CM_ SG_ 1639 BFS_MMB_storage_beep "Quittierungston Sitzmemory BFS (Anforderung Kombi)

";
CM_ SG_ 1639 BFS_MMB_store "Speichern der Sitzposition
";
CM_ BO_ 957 "MLBevo";
CM_ SG_ 957 Mem_BFSFo_Lordose_hoch "Anforderung Lordosenwölbung nach oben zu verschieben.";
CM_ SG_ 957 Mem_BFSFo_Lordose_runter "Anforderung Lordosenwölbung nach unten zu verschieben.";
CM_ SG_ 957 Mem_BFSFo_Lordose_vor "Anforderung Lordosenwölbung pneumatisch zu vergrößern.";
CM_ SG_ 957 Mem_BFSFo_Lordose_zurueck "Anforderung Lordosenwölbung zu verkleinern.";
CM_ SG_ 957 Mem_BFSFo_Massage_Geschw "Weiterleitung  der gewünschten Massage Geschwindigkeit ans IVB und zugleich Anforderungsbestätigung für LEDs am Klima-SG.";
CM_ SG_ 957 Mem_BFSFo_Massage_Intens "Weiterleitung  der gewünschten Massage Intensität ans IVB und zugleich Anforderungsbestätigung für LEDs am Klima-SG.";
CM_ SG_ 957 Mem_BFSFo_MMB_storage "Angabe der zu speichernden oder einzustellenden Memoryposition";
CM_ SG_ 957 Mem_BFSFo_Massage_Prg "Weiterleitung  des gewünschten Massageprogramms ans IVB und zugleich Anforderungsbestätigung für LEDs am Klima-SG.";
CM_ SG_ 957 Mem_BFSFo_MMB_tast "Einstellung der Memoryposition im  Tastbetrieb";
CM_ SG_ 957 Mem_BFSFo_MMB_tipp "Einstellung der Memoryposition im  Tippbetrieb";
CM_ SG_ 957 Mem_BFSFo_MMB_glob_Stop "Globaler Abbruch für automatische Funktionen";
CM_ SG_ 957 Mem_BFSFo_Sitztiefe_vor "Anforderung Sitztiefe nach vorne zu verlängern.";
CM_ SG_ 957 Mem_BFSFo_Sitztiefe_zur "Anforderung Sitztiefe nach vorne zu verlängern.";
CM_ SG_ 957 Mem_BFSFo_MMB_store "Aufforderung Memory-Position Mem_HL_MMB_store zu speichern";
CM_ SG_ 957 Mem_BFSFo_MMB_storage_beep "Quittierungston Sitzmemory  (Anforderung Kombi)";
CM_ SG_ 957 Mem_BFSFo_MMB_store_LED_on "LED zur Anzeige der Speicherbereitschaft";
CM_ SG_ 957 Mem_BFSFo_BeifaSitzverstellung "Funktionsrückmelde-LED 'Beifahrersitzverstellung aktiv'";
CM_ SG_ 957 Mem_BFSFo_MMB_lokal_Stop "mit dem lokal Stop moechte man, dass ein Sitz mit Pneumatik - Lordose sich im Memoryfall wie ein Sitz mit elektromechanischer Lordose verhaelt. Nur lokler Abbruch im TIP-Betrieb.";
CM_ SG_ 957 Mem_BFSFo_Sitzfahrt_aktiv "Signalisiert eine aktive Sitzfahrt.";
CM_ SG_ 957 Mem_BFSFo_BFS_Freigabe "Freigabe für die Fahrt des Beifahrersitzes aus der  Ruhestellung .";
CM_ SG_ 957 Mem_BFSFo_RSE_zurueck "dient der Monitorsteuerung (RSE) am Beifahrersitz aus dem Fond";
CM_ SG_ 957 Mem_BFSFo_RSE_vor "dient der Monitorsteuerung (RSE) am Beifahrersitz aus dem Fond";
CM_ SG_ 957 Mem_BFSFo_Business_anfahren "Befehl um Business Position an zufahren";
CM_ SG_ 957 Mem_BFSFo_Relax_anfahren "Befehl um Relax Position an zufahren";
CM_ SG_ 957 BFS_Kopfstuetze_vor "Berücksichtigung des Aktors Kopfstützenverstellung in X-Richtung bei der Fernsteuerung des Beifahrsersitzes von Hintersitz aus.";
CM_ SG_ 957 BFS_Kopfstuetze_zurueck "Berücksichtigung des Aktors Kopfstützenverstellung in X-Richtung bei der Fernsteuerung des Beifahrsersitzes von Hintersitz aus.";
CM_ SG_ 957 Mem_BFSFo_BFS_RSE_Freigabe "Freigabe für die RSE-Verstellung am am Ruhestellung.";
CM_ SG_ 957 Mem_BFSFo_Fusstuetze_runter "dient der Fusstuetzen -steuerung am Beifahrersitz aus dem Fond";
CM_ SG_ 957 Mem_BFSFo_Fusstuetze_hoch "dient der Fusstuetzen -steuerung am Beifahrersitz aus dem Fond";
CM_ BO_ 1178 "ab MQB 7.2";
CM_ SG_ 1178 FS_Lehne_nicht_verriegelt "Fahrer Sitz Lehne Verstellung Verriegelt Status

Verwendung nur im Bentley";
CM_ SG_ 1178 FS_Spezialposition_anfahren "paralell zu diesem Signal wird eine Botschaft auf den KCAN gesendet in der spezielle Anforderungen für den Empfänger stehen. 
Dieses Signal dient zusätzlich der Checksummenabsicherung bei einer Remotverstellung ";
CM_ SG_ 1178 FS_BFS_Sitzsym_Anfahrt "Sitzsymetrie Anfahrt BFS";
CM_ SG_ 1178 FS_Sitzfahrt_aktiv "Aktive Sitzfahrt Fahrersitz
";
CM_ SG_ 1178 FS_SLV_aktiv "Sitzlängsverstellung
";
CM_ SG_ 1178 FS_SHV_aktiv "Verstellung Sitzhöhe

";
CM_ SG_ 1178 FS_LNV_aktiv "Verstellung Lehnenneigung
";
CM_ SG_ 1178 FS_SNV_aktiv "Verstellung Sitzneigung
";
CM_ SG_ 1178 FS_KSV_aktiv "Verstellung Kopfstütze
";
CM_ SG_ 1178 FS_LKV_aktiv "Verstellung Lehnenkopf
";
CM_ SG_ 1178 FS_STV_aktiv "Verstellung Sitztiefe
";
CM_ SG_ 1178 FS_LHV_aktiv "Verstellung Lordose Höhe
";
CM_ SG_ 1178 FS_LWV_aktiv "Verstellung Lordose W
";
CM_ SG_ 1178 FS_GHV_aktiv "Verstellung Gurthöhe
";
CM_ SG_ 1178 FS_BFS_KSS_Anfahrt "Komfortseitensicht Anfahrt BFS";
CM_ SG_ 1178 FS_MMB_lokal_Stop "mit dem lokal Stop moechte man, dass ein Sitz mit Pneumatik - Lordose sich im Memoryfall wie ein Sitz mit elektromechanischer Lordose verhaelt. Nur lokler Abbruch im TIP-Betrieb.";
CM_ SG_ 1178 FS_MMB_store_LED_on "LED für Speichern
";
CM_ SG_ 1178 FS_MMB_storage_beep "Quittierungston Sitzmemory FS (Anforderung Kombi)";
CM_ SG_ 1178 FS_EE_Fond_FS_enable "EE Fond links
";
CM_ SG_ 1178 FS_EE_Fond_BFS_enable "EE Fond rechts

";
CM_ SG_ 1178 FS_BFS_Fond_Verst_enable "Verstellung Fond (vom MMI)
";
CM_ SG_ 1178 FS_EE_BFS_enable "EasyEntry Freigabe für Befahrersitz.";
CM_ SG_ 954 Mem_FS_Lordose_hoch "Anforderung Lordosenwölbung nach oben zu verschieben.";
CM_ SG_ 954 Mem_FS_Lordose_runter "Anforderung Lordosenwölbung nach unten zu verschieben.";
CM_ SG_ 954 Mem_FS_Lordose_vor "Anforderung Lordosenwölbung pneumatisch zu vergrößern.";
CM_ SG_ 954 Mem_FS_Lordose_zurueck "Anforderung Lordosenwölbung zu verkleinern.";
CM_ SG_ 954 Mem_FS_Massage_Geschw "Weiterleitung  der gewünschten Massage Geschwindigkeit";
CM_ SG_ 954 Mem_FS_Massage_Intensitaet "Weiterleitung  der gewünschten Massage Intensität";
CM_ SG_ 954 Mem_FS_SWangenLehne_beluef "Anforderung Seitenwangen Lehne zu vergrößern.";
CM_ SG_ 954 Mem_FS_SWangenLehne_entlue "Anforderung Seitenwangen Lehne zu verkleinern.";
CM_ SG_ 954 Mem_FS_Massage_Programm "Weiterleitung  des gewünschten Massageprogramms";
CM_ SG_ 954 Mem_FS_SWangenSitz_beluef "Anforderung Seitenwangen Sitz zu vergrößern.";
CM_ SG_ 954 Mem_FS_SWangenSitz_entlue "Anforderung Seitenwangen Sitz zu verkleinern.";
CM_ SG_ 954 FS_BFS_aufraeumen "Das Signal dient der Fernsteuerung des Beifahrersitz.";
CM_ SG_ 954 FS_BFSFo_aufraeumen "Das Signal dient der Fernsteuerung des Beifahrersitz.";
CM_ SG_ 954 FS_FSFo_aufraeumen "Das Signal dient der Fernsteuerung des Beifahrersitz.";
CM_ SG_ 954 FS_BFS_Multifunktionstaster_hoch "Das Signal dient der Fernsteuerung des Beifahrersitz.";
CM_ SG_ 954 FS_BFS_Multifunktionstaster_tief "Das Signal dient der Fernsteuerung des Beifahrersitz.";
CM_ SG_ 954 FS_BFS_Multifunktionstaster_vor "Das Signal dient der Fernsteuerung des Beifahrersitz.";
CM_ SG_ 954 FS_BFS_Multifunktionstaster_zur "Das Signal dient der Fernsteuerung des Beifahrersitz.";
CM_ SG_ 954 FS_BFS_Programmwippe_hoch "Das Signal dient der Fernsteuerung des Beifahrersitz.";
CM_ SG_ 954 FS_BFS_Programmwippe_tief "Das Signal dient der Fernsteuerung des Beifahrersitz.";
CM_ SG_ 954 FS_BFS_SHV_Taste_hoch "Das Signal dient der Fernsteuerung des Beifahrersitz.";
CM_ SG_ 954 FS_BFS_SHV_Taste_tief "Das Signal dient der Fernsteuerung des Beifahrersitz.";
CM_ SG_ 954 FS_BFS_SLV_Taste_vor "Das Signal dient der Fernsteuerung des Beifahrersitz.";
CM_ SG_ 954 FS_BFS_SLV_Taste_zurueck "Das Signal dient der Fernsteuerung des Beifahrersitz.";
CM_ SG_ 954 FS_BFS_SNV_Taste_hoch "Das Signal dient der Fernsteuerung des Beifahrersitz.";
CM_ SG_ 954 FS_BFS_SNV_Taste_tief "Das Signal dient der Fernsteuerung des Beifahrersitz.";
CM_ SG_ 954 FS_BFS_KSV_Taste_hoch "Das Signal dient der Fernsteuerung des Beifahrersitz.";
CM_ SG_ 954 FS_BFS_KSV_Taste_tief "Das Signal dient der Fernsteuerung des Beifahrersitz.";
CM_ SG_ 954 FS_BFS_LNV_Taste_vor "Das Signal dient der Fernsteuerung des Beifahrersitz.";
CM_ SG_ 954 FS_BFS_LNV_Taste_zurueck "Das Signal dient der Fernsteuerung des Beifahrersitz.";
CM_ SG_ 954 FS_BFS_Massage_Taste "Das Signal dient der Fernsteuerung des Beifahrersitz.";
CM_ BO_ 956 "MLBevo";
CM_ SG_ 956 Mem_FSFo_Lordose_hoch "Anforderung Lordosenwölbung nach oben zu verschieben.";
CM_ SG_ 956 Mem_FSFo_Lordose_runter "Anforderung Lordosenwölbung nach unten zu verschieben.";
CM_ SG_ 956 Mem_FSFo_Lordose_vor "Anforderung Lordosenwölbung pneumatisch zu vergrößern.";
CM_ SG_ 956 Mem_FSFo_Lordose_zurueck "Anforderung Lordosenwölbung zu verkleinern.";
CM_ SG_ 956 Mem_FSFo_Massage_Geschw "Weiterleitung  der gewünschten Massage Geschwindigkeit ans IVB und zugleich Anforderungsbestätigung für LEDs am Klima-SG.";
CM_ SG_ 956 Mem_FSFo_Massage_Intens "Weiterleitung  der gewünschten Massage Intensität ans IVB und zugleich Anforderungsbestätigung für LEDs am Klima-SG.";
CM_ SG_ 956 Mem_FSFo_MMB_storage "Angabe der zu speichernden oder einzustellenden Memoryposition";
CM_ SG_ 956 Mem_FSFo_Massage_Prg "Weiterleitung  des gewünschten Massageprogramms ans IVB und zugleich Anforderungsbestätigung für LEDs am Klima-SG.";
CM_ SG_ 956 Mem_FSFo_MMB_tast "Einstellung der Memoryposition im  Tastbetrieb";
CM_ SG_ 956 Mem_FSFo_MMB_tipp "Einstellung der Memoryposition im  Tippbetrieb";
CM_ SG_ 956 Mem_FSFo_MMB_glob_Stop "Globaler Abbruch für automatische Funktionen";
CM_ SG_ 956 Mem_FSFo_Sitztiefe_vor "Anforderung Sitztiefe nach vorne zu verlängern.";
CM_ SG_ 956 Mem_FSFo_Sitztiefe_zur "Anforderung Sitztiefe nach vorne zu verlängern.";
CM_ SG_ 956 Mem_FSFo_MMB_store "Aufforderung Memory-Position Mem_HL_MMB_store zu speichern";
CM_ SG_ 956 Mem_FSFo_MMB_storage_beep "Quittierungston Sitzmemory  (Anforderung Kombi)";
CM_ SG_ 956 Mem_FSFo_MMB_store_LED_on "LED zur Anzeige der Speicherbereitschaft";
CM_ SG_ 956 Mem_FSFo_MMB_lokal_Stop "mit dem lokal Stop moechte man, dass ein Sitz mit Pneumatik - Lordose sich im Memoryfall wie ein Sitz mit elektromechanischer Lordose verhaelt. Nur lokler Abbruch im TIP-Betrieb.";
CM_ SG_ 956 Mem_FSFo_Sitzfahrt_aktiv "Signalisiert eine aktive Sitzfahrt.";
CM_ SG_ 956 Mem_FSFo_Business_anfahren "Befehl um Business Position an zufahren";
CM_ SG_ 956 Mem_FSFo_Relax_anfahren "Befehl um Relax Position an zufahren";
CM_ BO_ 1180 "Ab MLBevo - CRC
";
CM_ SG_ 1180 Mem_Taster_BT_01_CRC "Für MLB:
'Berechnung siehe Lastenheft 'Kommunikationsabsicherung für FlexRay und CAN''

Ab MQB und MLBevo:
'Berechnung siehe Lastenheft 'End-to-End Kommunikationsabsicherung''

Endwerte siehe Begleitdokument 'S-PDU Kennungsfolgen'";
CM_ SG_ 1180 Mem_Taster_BT_01_BZ "4bit Botschaftszähler, wird in jeder Sendebotschaft inkrementiert";
CM_ SG_ 1180 MTBT_Pos1 "Betätigung Postionstaste 1 BT";
CM_ SG_ 1180 MTBT_Pos2 "Betätigung Postionstaste 2 BT
";
CM_ SG_ 1180 MTBT_Pos3 "Betätigung Postionstaste 3 BT";
CM_ SG_ 1180 MTBT_Pos4 "Betätigung Postionstaste 4 BT";
CM_ SG_ 1180 MTBT_On_Off "Betätigung On-Off Taste BT";
CM_ SG_ 1180 MTBT_M_Taste "Betätigung M-Taste BT";
CM_ BO_ 1170 "Ab MLBevo - CRC
";
CM_ SG_ 1170 Mem_Taster_FT_01_CRC "Für MLB:
'Berechnung siehe Lastenheft 'Kommunikationsabsicherung für FlexRay und CAN''

Ab MQB und MLBevo:
'Berechnung siehe Lastenheft 'End-to-End Kommunikationsabsicherung''

Endwerte siehe Begleitdokument 'S-PDU Kennungsfolgen'";
CM_ SG_ 1170 Mem_Taster_FT_01_BZ "4bit Botschaftszähler, wird in jeder Sendebotschaft inkrementiert";
CM_ SG_ 1170 MTFT_Pos1_EE "Betätigung Postionstaste 1 FT";
CM_ SG_ 1170 MTFT_Pos2 "Betätigung Postionstaste 2 FT";
CM_ SG_ 1170 MTFT_Pos3 "Betätigung Postionstaste 3 FT";
CM_ SG_ 1170 MTFT_Pos4 "Betätigung Postionstaste 4 FT";
CM_ SG_ 1170 MTFT_On_Off "Betätigung On-Off Taste FT";
CM_ SG_ 1170 MTFT_M_Taste "Betätigung M-Taste FT";
CM_ BO_ 1173 "Ab MLBevo - CRC";
CM_ SG_ 1173 MTHBF_CRC "Für MLB:
'Berechnung siehe Lastenheft 'Kommunikationsabsicherung für FlexRay und CAN''

Ab MQB und MLBevo:
'Berechnung siehe Lastenheft 'End-to-End Kommunikationsabsicherung''

Endwerte siehe Begleitdokument 'S-PDU Kennungsfolgen'";
CM_ SG_ 1173 MTHBF_BZ "4bit Botschaftszähler, wird in jeder Sendebotschaft inkrementiert
(Wird bei Rechtslenker vom TSG HL gesendet)
";
CM_ SG_ 1173 BFS_Sitzhoehe_hoch "Dient der Sitzhoehenverstellung des Beifahrersitzes aus dem Fond";
CM_ SG_ 1173 BFS_Sitzhoehe_runter "Dient der Sitzhoehenverstellung des Beifahrersitzes aus dem Fond";
CM_ SG_ 1173 MTHBF_ein "Wird bei Rechtslenker vom TSG HL gesendet";
CM_ SG_ 1173 BFS_Laengsverst_vor "Längsverstellung vor (Wird bei Rechtslenker vom TSG HL gesendet)
";
CM_ SG_ 1173 BFS_Laengsverst_zurueck "Längsverstellung zurück (Wird bei Rechtslenker vom TSG HL gesendet)";
CM_ SG_ 1173 BFS_Lehnenneigung_vor "Lehnenneigung vor (Wird bei Rechtslenker vom TSG HL gesendet)";
CM_ SG_ 1173 BFS_Lehnenneigung_zurueck "Lehnenneigung zurück (Wird bei Rechtslenker vom TSG HL gesendet)
";
CM_ SG_ 1173 BFS_Lehnenkopf_vor "Lehnenkopf vor (Wird bei Rechtslenker vom TSG HL gesendet)";
CM_ SG_ 1173 BFS_Lehnenkopf_zurueck "Lehnenkopf zurück (Wird bei Rechtslenker vom TSG HL gesendet)";
CM_ SG_ 1173 BFS_Kopfstuetzen_hoch "Kopfstützen hoch (Wird bei Rechtslenker vom TSG HL gesendet)";
CM_ SG_ 1173 BFS_Kopfstuetzen_runter "Kopfstützen runter (Wird bei Rechtslenker vom TSG HL gesendet)";
CM_ BO_ 1171 "ab MQB 7.2 gültig";
CM_ SG_ 1171 MFG_01_CRC "Für MLB:
'Berechnung siehe Lastenheft 'Kommunikationsabsicherung für FlexRay und CAN''

Ab MQB und MLBevo:
'Berechnung siehe Lastenheft 'End-to-End Kommunikationsabsicherung''

Endwerte siehe Begleitdokument 'S-PDU Kennungsfolgen'";
CM_ SG_ 1171 MFG_01_BZ "4bit Botschaftszähler, wird in jeder Sendebotschaft inkrementiert
";
CM_ SG_ 1171 MF_ZV_Lock "Verriegelungsanforderung durch MFG analog Meldung einer Locktasterbetätigung durch TSG.";
CM_ SG_ 1171 MF_Motorweiterlauf "Motorstop Behoerdenfahrzeug";
CM_ SG_ 1171 MF_Abzugssperre "Schlüsselabzugssperre";
CM_ SG_ 1171 MF_Anlassersperre "Notarzt 230V-Steckdose";
CM_ SG_ 1171 MF_Variante "Sonderfahrzeugvariante
0 = keine Sonderfunktion 
1 = Sondersignalfahrzeug
2 = Taxi 
3 = Fahrhilfe 
4 = Fahrschule+Extra 
5 = SSF";
CM_ SG_ 1171 MF_Schluessel_scan "Anforderung eines Innenraumscans - Schlüsselsuche";
CM_ SG_ 1171 MF_Laderelais "Signal für die Auswertung zur Anzeige der Batterie-Schwach-Anzeige im Kombi";
CM_ SG_ 1171 MF_StartStopp_Info "Stopp-Freigabe und Start-Anforderung an den Start-Stopp-Koordinator";
CM_ SG_ 1171 MF_Fernbed_ein "Fernbedienung für Petri+Lehr; Versehrte und Fahrschule";
CM_ SG_ 1171 MF_Standlicht "statisch oder auch mit Blink_modi für Taxialarm";
CM_ SG_ 1171 MF_Fahrlicht "statisch oder auch mit Blink_modi für interm.  Fahrlicht";
CM_ SG_ 1171 MF_interm_Fernlicht "mit Blink_modi für SoSi oder Taxialarm";
CM_ SG_ 1171 MF_Warnblinker "Versehrte";
CM_ SG_ 1171 MF_Fussraumbel "Fussraumbeleuchtung, Fahrschule";
CM_ SG_ 1171 MF_Innenraumbel "sämtliche Beleuchtungen akitivieren (Fussraum, Tür u.a.)";
CM_ SG_ 1171 MF_Innenraumbel_Unterdrueck "Unterdrückung des Innenlichts/Fussraumbeleuchtung, sowie Schließblinken";
CM_ SG_ 1171 MF_Notstart "Signal zeigt an, dass ein Notstart über DBMC erfolgte.

Verwendung in Verbindung mit Signal MF_Variante = DBMC.";
CM_ SG_ 1171 MF_Blk_li "Versehrte oder Fahrschule; Prio über Fernbedienung ein";
CM_ SG_ 1171 MF_Blk_re "Versehrte oder Fahrschule; Prio über Fernbedienung ein";
CM_ SG_ 1171 MF_Lichthupe "Versehrte oder Fahrschule; Oder-Verknuepfung
";
CM_ SG_ 1171 MF_Fernlicht "Versehrte oder Fahrschule; Oder-Verknüpfung";
CM_ SG_ 1171 MF_Tippwischen "Versehrte oder Fahrschule; Oder-Verknüpfung";
CM_ SG_ 1171 MF_Frontintervall "Versehrte oder Fahrschule; Oder-Verknüpfung";
CM_ SG_ 1171 MF_Wischerstufe_1 "Versehrte oder Fahrschule; Oder-Verknüpfung";
CM_ SG_ 1171 MF_Wischerstufe_2 "Versehrte oder Fahrschule; Oder-Verknüpfung";
CM_ SG_ 1171 MF_Frontwaschen "Versehrte oder Fahrschule; Oder-Verknüpfung";
CM_ SG_ 1171 MF_Heckintervall "Versehrte oder Fahrschule; Oder-Verknüpfung";
CM_ SG_ 1171 MF_Heckwaschen "Versehrte oder Fahrschule; Oder-Verknüpfung";
CM_ SG_ 1171 MF_Summer "Warnsummer für Funkhauptschalter und Fahrschulpedal";
CM_ SG_ 1171 MF_Alarm_Blinkertakt "Ansteuerung Blinker bei Alarm. Signal wird getaktet.
0 = Blinker für Alarm aus
1 = Blinker für Alarm ein";
CM_ SG_ 1171 MF_Alarm_Blinker "Taxialarmblinken, wie DWA ohne Fanfare";
CM_ SG_ 1171 MF_TFL_Abschaltung "Abschaltung des Tagfahrlicht
0 = keine Auswirkung
1 = Tagfahrlicht deaktiviert";
CM_ SG_ 1171 MF_interm_Takt "Taktung von intermittierenden Fernlicht/Fahrlicht bei einer Einsatzfahrt
0 = Licht aus
1 = Licht ein";
CM_ SG_ 1171 MF_Tuerentriegelung_hinten "Bei von innen verriegelten Fahrzeug Türen hinten entriegeln
0 = keine Auswirkung
1 = Türen hinten entriegeln
";
CM_ SG_ 1171 MF_interm_Fahrlicht "Ansteuerung intermittierendes Abblendlicht";
CM_ SG_ 1171 MF_Signalhorn "Versehrte, Fahrschule oder Taxi (bei Alarm)";
CM_ SG_ 1171 MF_FH_FT_hoch "Versehrte";
CM_ SG_ 1171 MF_FH_FT_tief "Versehrte";
CM_ SG_ 1171 MF_FH_BT_hoch "Versehrte";
CM_ SG_ 1171 MF_FH_BT_tief "Versehrte";
CM_ SG_ 817 MFL_Toggle "Watchdog Toggle-Bit";
CM_ SG_ 817 MFL_Lokalaktiv "Zeigt an ob das SG nach Klemme15 AUS und nach entsprechender MAX Aktivzeit noch aktiv war";
CM_ SG_ 817 MFL_M_Taste "Taster für Umschaltung Automatik/manuelles Schalten (Tiptronic)";
CM_ SG_ 817 MFL_Tastencode_1 "Beschreibt die Funktion einer fest zugeordneten Taste/Walze auf dem MFL. Bei Betätigung ändert sich der Wert von 0x0 auf den jeweiligen Tastencode.";
CM_ SG_ 817 MFL_Tastencode_2 "Beschreibt die Funktion einer fest zugeordneten Taste/Walze auf dem MFL. Ist MFL_Tastencode_1 wegen Betätigung einer Taste/Walze bereits mit einem Wert ungleich 0x0 belegt, so ändert sich bei Betätigung einer weiteren Taste/Walze der Wert dieses Signals v";
CM_ SG_ 817 MFL_Variante "Markenspezifische Variantennummer des MFL";
CM_ SG_ 817 MFL_Tip_Down "MFL-Tiptronic Tasten vom MFL für Getriebe
    0x0 = kein Tip_Down
    0x1 = Tip_Down";
CM_ SG_ 817 MFL_Tip_Up "MFL-Tiptronic Tasten vom MFL für Getriebe
    0x0 = kein Tip_Up
    0x1 = Tip_Up";
CM_ SG_ 817 MFL_SatModul_links_Err "Schalter Tastermodul links Fehler";
CM_ SG_ 817 MFL_SatModul_rechts_Err "Schalter Tastermodul rechts Fehler";
CM_ SG_ 817 MFL_LR_HZG_Status "Status Lenkradheizung";
CM_ SG_ 817 MFL_LR_HZG_Err "Lenkradheizung Fehler";
CM_ SG_ 817 MFL_Signalhorn "Signalhorn nicht betaetigt/betaetigt";
CM_ SG_ 817 MFL_Signalhorn_Err "Signalhorn Fehler";
CM_ SG_ 817 MFL_Tip_links_Err "Tiptronic links Fehler";
CM_ SG_ 817 MFL_Tip_rechts_Err "Tiptronic rechts Fehler";
CM_ SG_ 817 MFL_Taste_links_Err "MFL_Tastenblock links Fehler";
CM_ SG_ 817 MFL_Taste_rechts_Err "MFL_Tastenblock rechts Fehler";
CM_ SG_ 817 MFL_ECU_Err "MFL-µC Fehler";
CM_ SG_ 817 MFL_Response_Err "siehe LIN2.0-Specification
(Darf nicht über ein Fehlergueltigkeitsbit abgesichtert werden!)";
CM_ SG_ 349 MO2_Freigabe_Info_WFS "WFS-Freigabeinformation";
CM_ SG_ 349 MO2_Sperr_Info_WFS "WFS-Sperrinformation";
CM_ SG_ 349 MO2_Freigabe_Verfallsinfo_WFS "WFS-Freigabeverfallsinformation";
CM_ BO_ 1600 "ab MQB mit QBit Höheneinfo und MO_Versionsinfo_02";
CM_ SG_ 1600 MO_QBit_Ansaugluft_Temp "
";
CM_ SG_ 1600 MO_QBit_Kuehlmittel_Temp "
";
CM_ SG_ 1600 MO_KL15_Abschaltempfehlung "Kessy Abschaltempfehlung nach Verlassen des Fahrzeugs";
CM_ SG_ 1600 MO_HYB_Fehler_HV_Netz "Im HV-Bordnetz ist fehlerbedingt kein generatorischer Betrieb möglich. Das 12V-Bordnetz wird über den DC/DC-Wandler allein aus der Traktionsbatterie gespeist. Um diesen Zustand möglichst lange aufrechterhalten zu können, sollten Komfort-Verbraucher abgesc";
CM_ SG_ 1600 MO_aktives_Getriebeheizen "Information für Getriebe, ob ein Ventil für Getriebheizen angesteuert werden muss";
CM_ SG_ 1600 MO_Absperrventil_oeffnen "Signal an Klima-SG das Absperrrventil anzusteuern. Ab D4 auch 0x3 Ventil_schließen.

Im MQB wird hier der Soll-Status des Absperrventils ausgegeben.
Achtung: bei z. B. klemmendem Ventil entspricht das Signal nicht dem tatsächlichen Status!";
CM_ SG_ 1600 MO_Ansaugluft_Temp "In Fahrzeugen ohne Außentemperatur vom Kombi kann aus der Ansauglufttemperatur auf die Außentemperatur geschlossen werden. Beim SDI ist das mit einer gewissen Genauigkeit gegeben. Genutzt wird es vom ASG.";
CM_ SG_ 1600 MO_Oel_Temp "Realer Meßbereich ca. -40..150 Grad";
CM_ SG_ 1600 MO_Kuehlmittel_Temp "Kuehlmitteltemperatur";
CM_ SG_ 1600 MO_Hoeheninfo "Korrekturfaktor Höhe (1 entspricht 1013 mbar)";
CM_ SG_ 1600 MO_Kennfeldk "Die Kennfeldkühlung ist in diesem Fahrzeug verbaut und hat keinen Systemfehler";
CM_ SG_ 1600 MO_Versionsinfo_02 "Versioninformation vom Motor zur Steuerung bei inkompatiblen KMatrix-Änderung bzw. Einführung von neuen Funktionen, die in den Empfängern verriegelt werden müssen. Zu jedem Ereignis wird ein fixer Zählerstand zugeordnet, um dem Empfänger die funktionale Ä";
CM_ SG_ 1600 MO_QBit_Hoeheninfo "Qualifizierungsbit der Höheninfo. Gesetzt bei Ersatzwert, Init oder Fehler.";
CM_ SG_ 1600 MO_Getriebe_kuehlen "Anforderung Getriebekühlventilansteuerung";
CM_ SG_ 1600 MO_Mom_Traegheit_02 "Massenträgheit des Motors (J) in kgm²
Bei Handschaltern wird das Zweimassenschwungrad mit berücksichtigt.
Bei eingebautem Getriebesteuergerät wird nur das Motorträgheitsmoment angegeben (Ohne Anteile des Massenschwungrades).";
CM_ SG_ 1600 MO_Heizungspumpenansteuerung "Anforderung Heizungspumpenansteuerung
MQB und Hybrid: Status der Heizungsunterstützungspumpe am MSG
";
CM_ SG_ 1600 MO_SpannungsAnf "Forderung des Motor-SGs zur Spannungsanhebung";
CM_ SG_ 1600 MO_Nachlaufzeit_Heizungspumpe "Nachlaufzeit für Heizungspumpe für Turboladerschutz";
CM_ SG_ 1607 MO_ITM_Kuehlmittel_Temp "Kuehlmitteltemperatur: Ersatzkühlmitteltemperatur für Motoren mit ITM (Thermomanagement)

ACHTUNG: Ab MQB wird in diesem Signal das Anzeigeplateau durch das MSG dargestellt!";
CM_ SG_ 1607 MO_E85_Sensor "Information über den E85 Gehalt (%-mass.) im Ottokraftstoff";
CM_ SG_ 1607 SCR_Anz_Motorstarts "Anzahl noch möglicher Motorstarts, wenn Reichweite = 0 ist
0..13 = Anzeige 'x mögliche Restarts'
14 = Eingeschränkte Fahrfunktion (z. Zt. Audi)
15 = keine Einschränkung (Anzeige Reichweite)
Bedienung des Signals nur bei Dieseln mit SCR-System.";
CM_ SG_ 1607 SCR_Reichweite "Gesamtreichweite in km der aktuellen SCR-Tankfüllung.
Bedienung des Signals nur bei Dieseln mit SCR-System.";
CM_ SG_ 1607 MO_Ethanol_Spuelhinweis "Hinweis das der Fahrer beim nächsten Tanken Ethanol armen Sprit tanken soll.";
CM_ SG_ 1607 SCR_Warnstufe_1 "Ansteuerung der SCR Füllstandswarnlampe (Stufe 1) (gelbe Lampe) SCR_Warnstufe_1 (Prio 2).
Bedienung des Signals nur bei Dieseln mit SCR-System. Andere senden Initwert.";
CM_ SG_ 1607 SCR_Warnstufe_2 "Ansteuerung der SCR Füllstandswarnlampe (Stufe 2) (Blinkbit für gelbe Lampe oder rote Lampe) SCR_Warnstufe_2 (Prio 1).
Bedienung des Signals nur bei Dieseln mit SCR-System. Andere senden Initwert.";
CM_ SG_ 1607 SCR_Text "Warntext (z. B. in Kombination mit SCR Warnstufe und SCR-Systemfehler).
Bedienung des Signals nur bei Dieseln mit SCR-System. Andere senden Initwert.";
CM_ SG_ 1607 SCR_Akustik "Ansteuerung von Summer/Gong bei Aktivieren der SCR-Warnungen.
Bedienung des Signals nur bei Dieseln mit SCR-System. Andere senden Initwert.";
CM_ SG_ 1607 SCR_verbaut "Die SCR-Signale deren Initwert ungleich 0 sind, werden nur dann ausgewertet, wenn SCR_verbaut == 1 den Verbau des SCR Systems zeigt.";
CM_ SG_ 1607 MO_Kraftstofffilter_Wasser "Für Schlechtkraftstoffländer wird das Wasserabscheidevolumen im Dieselkraftstofffilter mit einem  Wassersensor überwacht. Ist das Volumen erschöpft, erfolgt im Kombi eine entsprechende Anzeige.";
CM_ SG_ 1607 SCR_Systemfehler "Ansteuerung Anzeige für SCR-Systemfehler";
CM_ SG_ 1607 SCR_Inducement_Strategie "Art des Motor-Inducement-Konzepts. Abhängig von diesem Signal sind die Warntexte zwischen 'Kein Motorstart (in...km)' und 'eingeschränkte Fahrbarkeit (in ...km)' auszuwählen.";
CM_ SG_ 1607 MO_CO2_Faktor "dynamischer Umrechnungsfaktor von l in CO2";
CM_ SG_ 1607 MO_MKB_MUX "Die vier Motorkennbuchstaben werden gemultiplext in MO_MKB übertragen. Das Signal MO_MKB_MUX stellt das Steuersignal für diesen Multiplexer dar.";
CM_ SG_ 1607 MO_MKB_01 "Motorkennbuchstabe 1";
CM_ SG_ 1607 MO_MKB_02 "Motorkennbuchstabe 2";
CM_ SG_ 1607 MO_MKB_03 "Motorkennbuchstabe 3";
CM_ SG_ 1607 MO_MKB_04 "Motorkennbuchstabe 4";
CM_ BO_ 168 "Teil 2 neue Momentenschnittstelle MLB";
CM_ SG_ 168 Motor_12_CRC "Für MLB:
'Berechnung siehe Lastenheft 'Kommunikationsabsicherung für FlexRay und CAN''

Ab MQB und MLBevo:
'Berechnung siehe Lastenheft 'End-to-End Kommunikationsabsicherung'

Endwerte siehe Begleitdokument 'S-PDU Kennungsfolgen'";
CM_ SG_ 168 MO_Mom_neg_verfuegbar "Einheitenloser Wert! Faktor in MO_Faktor_Momente (CAN V6.x) bzw. MO_Faktor_Momente_02 (CAN V7.x) in Motor_Code_01 beachten!

Bei aktueller Drehzahl im nächsten Task (bei CAN-Übertragung z.B. 10ms) tatsächlich verfügbares negatives Moment (Summe aus Verl";
CM_ SG_ 168 MO_Mom_Begr_stat "Einheitenloser Wert! Faktor in MO_Faktor_Momente (CAN V6.x) bzw. MO_Faktor_Momente_02 (CAN V7.x) in Motor_Code_01 beachten!

Bei aktueller Drehzahl quasistationär (nach ca. 3..5 s) max. mögliches Moment (Summe aus max. Moment des Verbrennungsmotors aus ";
CM_ SG_ 168 MO_Mom_Begr_dyn "Einheitenloser Wert! Faktor in MO_Faktor_Momente (CAN V6.x) bzw. MO_Faktor_Momente_02 (CAN V7.x) in Motor_Code_01 beachten!

Bei aktueller Drehzahl kurzfristig (ca. 100..200 ms) max. mögliches Moment (Summe aus Verbrennungsmotor und E-Motor), zeigt alle";
CM_ SG_ 168 MO_Momentenintegral_02 "100  %  entspricht volle Verfügbarkeit aktuell vorhanden. 0 % entspricht Integral bis Limit gefüllt, erhöhender Eingriff kann aktuell nicht berücksichtigt werden oder aufgrund eines Fehlers nicht verfügbar
";
CM_ SG_ 168 MO_QBit_Drehzahl_01 "AUDI D4: Zykluszeit: 10ms (siehe Zykluszeit schnell/Cycletime Fast)

Achtung:
Reduktion der Zykluszeit Motor_03 auf 10ms geplant.
Projektabhängig soll künftig mit 10ms gesendet werden.
Empfänger die in weiteren Konzern-Projekten eingesetzt werden müs";
CM_ SG_ 168 MO_Drehzahl_01 "Im Fehlerfall wird die Motordrehzahl über die Nockenwellendrehzahl als Ersatzgrösse ausgegeben

Bei Parallelhybrid: Getriebeeingangsdrehzahl (=E-Maschinen Drehzahl)

Hinweis: 
Ehemaliger Fehlerwert 0xFFFF wird senderseitig nicht unterstützt. 
Diesen";
CM_ SG_ 958 Motor_14_CRC "Ab MQB und MLBevo:
'Berechnung siehe Lastenheft 'End-to-End Kommunikationsabsicherung'

Endwerte siehe Begleitdokument 'S-PDU Kennungsfolgen'";
CM_ SG_ 958 MO_StartStopp_Status "Aktivitätsstatus Start/Stopp-Koordinator
HYBRID:
Wenn MO_Hybridfahrzeug = 1 gilt:
Signal bezieht sich nur auf den Verbrennungsmotor, nicht auf den Hybridantrieb
";
CM_ SG_ 958 MO_StartStopp_Wiederstart "Motorwiederstart durch Start/Stopp-Koordinator
HYBRID:
Wenn MO_Hybridfahrzeug =1 gilt:
Warnung vor Spannungseinbruch beim Zustart des Verbrennungsmotors. 
-nicht relevant, da derzeit kein Start über 12V-Starter geplant-
Dieses Signal wird nur vom Hyb";
CM_ SG_ 958 MO_StartStopp_Motorstopp "Motor-Stopp durch Start/Stopp-Koordinator
HYBRID:
Wenn MO_Hybridfahrzeug = 1 gilt:
Verbrennungsmotor durch Hybrid-Koordinator im MSG ausgeschaltet. 
Die definierten Start/Stopp-Signale beziehen sich nur auf den Verbrennungsmotor!";
CM_ SG_ 958 MO_Freig_Reku "Empfehlung des Motor-SG's zur Spannungsabsenkung/-anhebung für den Rekuperationsbetrieb";
CM_ SG_ 958 MO_Kl_75 "Klemme X
";
CM_ SG_ 958 MO_Kl_50 "Klemme 50: Startausführung

MLB: nicht von allen Motoren gesendet
MQB/MLBevo: gesendet von allen Motoren ";
CM_ SG_ 958 MO_Gangposition "MLB:
Stellung des Wählhebels in der Schaltgasse des Handschaltgetriebes.
MLBevo: 
Ausweitung der Bedienung auch auf Automatikgetriebe;
Routing des Signals GE_Fahrstufe: 
1. Position_R (dez. 6) auf MO_Gangposition: Gang_R (dez. 13) wegen Entfall Signa";
CM_ SG_ 958 MO_StartStopp_Fahrerwunsch "Fahreraktivität Start/Stop";
CM_ SG_ 958 MO_HYB_Fahrbereitschaft "Signal steuert u.a. in der Lenkhilfe zusammen mit weiteren Informationen den Modewechsel in den 'Drivemode'
Grüne Anzeige im Kombiinstrument zur Signalisierung der Bereitschaft des Hybridsystems.";
CM_ SG_ 958 MO_Ext_E_Fahrt_aktiv "Funktionsrückmeldung zum erw. E-Fahr-Betrieb über Lampe/LED im E-Mode-Taster";
CM_ SG_ 958 MO_Fahrer_bremst "Redundante Bremsinformation vom Motor.

MLB:
AUDI D4: Zykluszeit: 10ms (siehe Zykluszeit schnell/Cycletime Fast)
Im AUDI B8 wird in diesem Bit der Wert der ESP-CAN-Information 'ESP_Fahrer_bremst' ausgegeben.

Achtung:
Reduktion der Zykluszeit Motor";
CM_ SG_ 958 MO_QBit_Fahrer_bremst "MLB:
AUDI D4: Zykluszeit: 10ms (siehe Zykluszeit schnell/Cycletime Fast)

Achtung:
Reduktion der Zykluszeit Motor_03 auf 10ms geplant.
Projektabhängig soll künftig mit 10ms gesendet werden.
Empfänger die in weiteren Konzern-Projekten eingesetzt werd";
CM_ SG_ 958 MO_BLS "Ungefiltertes Rohsignal des Bremslichtschalters, nur wenn HW-Eingang bestückt und ausgewertet wird. Bei Motoren ohne genutzten HW-Eingang wird kein Ersatzwert (bspw. SW-Signal über CAN) ausgegeben!
Bei AUDI muss das Signal wg. Bremslichtfunktion immer be";
CM_ SG_ 958 MO_Konsistenz_Bremsped "MLB:

AUDI D4: Zykluszeit: 10ms (siehe Zykluszeit schnell/Cycletime Fast)
Siehe 'Funktionsspezifikation Bremslichtinfo B8'

Achtung:
Reduktion der Zykluszeit Motor_03 auf 10ms geplant.
Projektabhängig soll künftig mit 10ms gesendet werden.
Empfäng";
CM_ SG_ 958 MO_KomFehler_ESP "Anzeige Kommunikationsfehler bei Empfang vom ESP";
CM_ SG_ 958 MO_Klima_Eingr "Eingriffe des Motor bei der Klima";
CM_ SG_ 958 MO_Aussp_Anlass "Das Signal zeigt an, ob die Wiederholstartsperre aktiv ist. D. h. eine Ansteuerung des Anlassers wird auch bei erfüllten Startvoraussetzungen (HS: Interlock betätigt bzw. AT: P/N eingelegt und Bremse betätigt) nicht erfolgen.";
CM_ SG_ 958 MO_Freig_Anlass "Bit wird gesetzt, wenn der Motor beim Automatikstart gestartet werden darf (Motorstillstand, Emissionsmaßnahmen sind erfüllt).";
CM_ SG_ 958 MO_Kuppl_schalter "MLB:
Das Motorsteuergerät gibt die Information aus, ab wann der Kupplungsschalter durch das Motorsteuergerät als getreten gesehen wird
0x0: Schalter sagt betätigt (Ausgekuppelt)
0x1: Schalter sagt nicht betätigt (Eingekuppelt)

MQB:
Nur Handschalter";
CM_ SG_ 958 MO_Interlock "Das Motorsteuergerät gibt die Information aus, ab wann der Kupplungsschalter durch das Motorsteuergerät als getreten gesehen wird.
Bei Systemen für Start Stopp muss das Interlocksignal für einen Start durch das MSG generiert werden, sobald der Schalthebe";
CM_ SG_ 958 MO_Motor_laeuft "Das Motorsteuergerät gibt die Information aus, ab wann der Motor verbrennungsbedingt autark läuft und durch zuschaltbare Nebenaggregate mechanisch belastbar ist (z.B. durch Generator, Klimakompressor, etc.).

Die 'Motor läuft' Information wird ausgegebe";
CM_ SG_ 958 MO_Kickdown "Es gilt: Signalspec MO_Kickdown v1.0";
CM_ SG_ 958 MO_QBit_KL_75 "Q - Bit für das KL 75 Signal zur Vermeidung der fehlerhaften Erkennung von Motorstarts. 
Wird auf 1 gesetzt, solange das Motorsteuergerät KL15 = AUS erkannt hat.";
CM_ SG_ 958 MO_EKlKomLeiRed "Anforderung an die Klimasteuerung, die Leistungsaufnahme des E-Kompressors bei schlechtem SOC und in bestimmten Fahrsituationen zu begrenzen. (Das bereits bestehende Signal 'Klimakompressor aus' als stets umzusetzende Anforderung bleibt unverändert besteh";
CM_ SG_ 958 MO_Handshake_STH "Es gilt: Signalspec MO_Handshake v1.0

Handshake zwischen MSG und STH. Wenn das MSG die EKP aufgrund einer STH-Anforderung ansteuert und kein Fehlereintrag bzgl. EKP/KPE/NDR vorliegt, wird das Bit gesetzt.";
CM_ SG_ 958 MO_BKV_Unterdruckwarnung "Über die Unterdruckwarnung signalisiert das MSG dem ESP, dass kein ausreichender Unterdruck für den BKV zur Verfügung gestellt werden kann.";
CM_ SG_ 958 MO_Freigabe_Segeln "Freigabebit des Segelbetriebs im Getriebe. Bedingt durch bestimmte Diagnosen und Adaptionen des MSGs, die nur im Schub möglich sind, darf nicht jede Schubphase für einen Segelbetrieb genutzt werden. Eine Freigabe bleibt auch außerhalb einer Schubphase bes";
CM_ SG_ 958 MO_PTC_Status "Status-Rückmeldung vom MSG zum aktuellen PTC-Status (stufiges PTC, Relais am MSG). Bei Ansteuerung eines stufigen PTC durch ein anderes SG beschreibt das Signal die vom MSG freigegebene PTC-Stufe.";
CM_ SG_ 958 MO_QBit_Gangposition "Qualitätsbit zum Signal MO_Gangposition";
CM_ SG_ 958 MO_Signalquelle_Gangposition "Signalquelle des Signals MO_Gangposition
0: Signalquelle Gangpositionssensor
1: Signalquelle Modellwert (v/n)";
CM_ SG_ 958 MO_Remotestart_Betrieb "Das MSG ist für den Remotestart-Betrieb bereit. Nach Empfang der Motorstartanforderung für RSt-Betrieb durch BCM wird der Fahrzeugmotor gestartet und solange der Motor läuft, bleibt dieses Bit aktiv. Dieses Signal ist nur zur Verwendung durch das BCM zur ";
CM_ SG_ 958 MO_Zylinderabschaltung "Status Zylinderabschaltung Motor";
CM_ SG_ 958 MO_HYB_VM_aktiv "0 = VMotor wird nicht aktiv gehalten (nVM < n_min und keine LL-Regelung aktiv)
1 = VMotor aktiv (ab der ersten Einspritzung; gilt auch für Schubbetrieb, wenn VMotor spätestens durch LLRegelung befeuert würde)
Verwendet zur Bestimmung des Ist-Zustandes";
CM_ SG_ 958 MO_StartVorauss_erfuellt "Dient der Fallunterscheidung bei ZAT-Betätigung im Zustand 'KL15 ein' (bei nicht gesetztem Signal folgt KL15 aus, bei gesetztem Signal folgt setzen KL50-Anf.)

0: Signal nicht bedient 
1: Voraussetzungen zur Antriebsstrangaktivierung / Startvoraussetzu";
CM_ BO_ 1648 "Kombischnittstelle";
CM_ SG_ 1648 MO_max_Ladedruck "maximal möglicher Ladedruck (zur Anpassung des Anzeigebereichs bei absoluter Ladedruckanzeige)";
CM_ SG_ 1648 MO_ANC_Kennfeld_Anf "Anforderung ANC Kennfeldumschaltung";
CM_ SG_ 1648 MO_Bremslicht_Reku "Bremslicht (ggf. bei Rekuperation durch E-Motor) wird angesteuert";
CM_ SG_ 1648 MO_StartStopp_PopUp "Das Signal zeigt an, ob der StSt-Status mittels Deaktivierungstaster geändert wurde. Ein Wechsel auf die Werte 01 oder 10 löst im Kombi ein entsprechendes PopUp aus. Bei einem Statuswechsel durch andere Signalquellen (z.B. Charisma, fehlerbedingte Abschal";
CM_ SG_ 1648 MO1_Sperr_Info_WFS "WFS-Sperrinformation";
CM_ SG_ 1648 MO1_Freigabe_Info_WFS "WFS-Freigabeinformation";
CM_ SG_ 1648 MO_EPCL "Die Anforderung der EPC-Symbolik vom MSG ans Kombi soll durch das Bus-Signal MO_EPCL gemäß folgender Logik erfolgen:
MO_EPCL = 0 dez -> EPC Lampe aus, kein Text
MO_EPCL = 1 dez -> gelbe EPC-Symbolik, Text ¿Motorsteuerung: Störung! Bitte Service aufsuche";
CM_ SG_ 1648 MO_Zylabsch_Texte_02 "ZAS-Anzeige für den Fahrer im Kombi
0: kein ZAS (generell keinerlei ZAS-Anzeigen)  (Init für nicht ZAS-Motor)
1: ZAS im Vollmotorbetrieb  (Init für ZAS-Motor)
2: ZAS im Abschaltbetrieb: 1 Zyl aktiv
3: ZAS im Abschaltbetrieb: 2 Zyl aktiv
4: ZAS im Abs";
CM_ SG_ 1648 MO_Fahrzeugtyp "Unterscheidet die Fahrzeugtypen bzgl. der Antriebsart";
CM_ SG_ 1648 MO_NMAX_Schaltanzeige "Maximaldrehzahl für Schaltanzeige";
CM_ SG_ 1648 MO_Abstellzeit "Abstelldauer nach letztem KL15 aus

Hinweis: 
Ehemaliger Fehlerwert 0xFF wird senderseitig nicht unterstützt. 
Diesen Wert aus Kompatibilitätsgründen nicht neu belegen!";
CM_ SG_ 1648 MO_Abstellzeit_Status "Statusinformation zur Abstellzeit
0: Die dem Status zugeordnete Variable konnte noch nicht berechnet werden. 
1: Die dem Status zugehörige Variable wurde korrekt berechnet. 
2: Der Wert der zugehörigen Variablen ist nur ein Minimalwert. 
3: Der Wert d";
CM_ SG_ 1648 MO1_Freigabe_Verfallsinfo_WFS "WFS-Freigabeverfallsinformation";
CM_ SG_ 1648 MO_Hybrid_StartStopp_LED "Ansteuerung der Funktions-LED der Hybrid Taste bzw. Start/Stop Deaktivierungstaste.
Der Start/Stopp-Master (derzeit im MSG) (oder ein künftiger Hybrid-Master) soll die Ansteuerung senden.";
CM_ SG_ 1648 MO_Fehler_Zylabsch "Fehlerstatus der Funktion Zylinderabschaltung ";
CM_ SG_ 1648 MO_Anzahl_Abgesch_Zyl "Gibt die Anzahl der abgeschalteten Zylinder an. In Übergangszuständen wird der Zielbetriebszustand angezeigt.";
CM_ SG_ 1648 MO_Zylabsch_Texte "Zylinderabschaltung mode in Kombi, fuer Zylinderabschaltung";
CM_ SG_ 1648 MO_Ethanol_BS_Texte "Ethanol Brennstoff-Texte im Kombi

0 = kein Text
1 = E85 Warm_Up
2 = FlexFuel Warnung 3.Stufe (Too cold for ethanol)
3 = Warmfahrempfehlung MQB / FlexFuel Warnung 1.Stufe (Refuel with gasoline)
4 = FlexFuel Warnung 2. Stufe (Refuel with gasoline)
5";
CM_ SG_ 1648 MO_Drehzahl_Warnung "Warnhinweis zum Kombi im Fall einer fehlerbehafteten Drehzahlbegrenzung";
CM_ SG_ 1648 MO_obere_Drehzahlgrenze "obere Drehzahlgrenze des Motors";
CM_ SG_ 289 Motor_20_CRC "Für MLB:
'Berechnung siehe Lastenheft 'Kommunikationsabsicherung für FlexRay und CAN''

Ab MQB und MLBevo:
'Berechnung siehe Lastenheft 'End-to-End Kommunikationsabsicherung'

Endwerte siehe Begleitdokument 'S-PDU Kennungsfolgen'";
CM_ SG_ 289 MO_Fahrpedalrohwert_01 "AUDI D4: Zykluszeit: 10ms (siehe Zykluszeit schnell/Cycletime Fast)

Stellung des Fahrpedales (Rohwert, ohne Überlagerung durch GRA-Eingriffe etc.)

Die Funktionen zur Berechung des Fahrpedalrohwerts laufen im 10ms Raster. Der Fahrpedalwert berechnet ";
CM_ SG_ 289 MO_QBit_Fahrpedalwerte_01 "AUDI D4: Zykluszeit: 10ms (siehe Zykluszeit schnell/Cycletime Fast)

QBit für beide Fahrpedalwerte des Motors (Fahrpedalrohsignal für ESP, EPB, ACC; Fahrpedalwert für Getriebe)

Achtung:
Reduktion der Zykluszeit Motor_03 auf 10ms geplant.
Projektabh";
CM_ SG_ 289 MO_Fahrpedalgradient "Das Motorsteuergerät besitzt 2 analoge Fahrpedalsignale. Das Signal des ersten Kanals wird alle 4ms abgetastet. Um Bitschwankungen des A/D-Wandler herauszufiltern wird das Signal entjittert. Anschließend wird der Gradient berechnet. Entsprechend der Zyklu";
CM_ SG_ 289 MO_Sig_Fahrpedalgradient "Kennzeichnet das Vorzeichen des Signal 'Fahrpedalgradient'. Die Ausgabe erfolgt nur parallel statisch mit gesendetem Signal: 'Steuerungsbit Fahrpedalgradient' ";
CM_ SG_ 289 MO_rel_Saugrohrdruck "Der Wert gibt an, um wieviel mbar der Saugrohrdruck unterhalb des Umgebungsdrucks liegt. Überdruck im Saugrohr wird nicht ausgegeben.
0: Saugrohrdruck=Umgebungsdruck";
CM_ SG_ 289 MO_rel_Saugrohrdruck_gem_err "0: mind. eine Modellrechnung wird zur Berechnung des relativen Saugdrucks herangezogen
1: Relativer Saugrohrdruck wird ausschließlich über Messgrößen bestimmt";
CM_ SG_ 289 MO_Moment_im_Leerlauf "Fahrerwunschmoment ist minimal: keine Momentenanforderung durch Fahrpedal, ACC oder GRA+; (Das Signal ist unabhängig von Momentenerhöhungen durch Leerlaufregler oder MSR).

AUDI D4: Zykluszeit: 10ms (siehe Zykluszeit schnell/Cycletime Fast)

Achtung:";
CM_ SG_ 289 MO_Schubabschaltung "ESP plausibilisiert Unterdrucksensor nur bei aktiver Schubabschaltung";
CM_ SG_ 289 MO_StartStopp_StoppVorbereitung "Zeigt allen aktiven Start-/Stoppteilnehmern einen möglichen Motorstopp im Anhaltevorgang an (Empfänger notwendige Vorbereitungen treffen)
Es liegen keine Vetos vor.";
CM_ SG_ 289 MO_Solldrehz_Leerlauf "Leerlaufsolldrehzahl, die im Motor eingestellt ist (Bei Parallelhybrid im E-Fahr-Betrieb Leerlaufsolldrehzahl der E-Maschine). Der Motor paßt aufgrund der Anforderung von anderen Steuergeräten seine Leerlaufsolldrehzahl an, bspw. Kat-Heizen, Anforderung v";
CM_ SG_ 289 MO_Entkopplung_Sollschlupf "MSG fordert von GSG an, das Anfahrelement (Fahr-/Wandlerkupplung) zu entkoppeln; das GSG soll die gesendete Drehzahl als Schlupf einstellen und ggf. die Regler-Parameter umschalten, damit Rucke aus dem Antrieb nicht im Fahrzeug spürbar werden; nutzbar z.B";
CM_ SG_ 289 MO_temporaere_Fahrerabwesenheit "Das Signal dient zur Signalisierung einer temporären Abwesenheit des Fahrers. In dieser Zeit ist es ihm möglich, sich durch gewisse ¿ im Verlassenskonzept definierte ¿ Fahreraktionen im aktuellen Fahrzyklus zurückzumelden.
Das Signal wird gesetzt, sobald";
CM_ SG_ 289 TSK_a_Soll_gradientenbegrenzt "TSK Sollbeschleunigung für Fahrerassistenzsysteme mit aktiver Längsführung (GRA, ACC, IPA...). Der Wert stellt den ruckbegrenzten Sollwert der TSK-Regelung dar und ist Basis der TSK-Antriebs- und Bremsmomentenvorsteuerung.";
CM_ BO_ 967 "MQB - vorher Motor_06 / Umbenennung wg. ID-Wechsel";
CM_ SG_ 967 MO_Kuehlerluefter_MUX "Multiplexer für das Signal 'MO_Kuehlerlüfter'";
CM_ SG_ 967 MO_Kuehlerluefter_1 "Ansteuertastverhaeltnis (PWM) der Kuehlerluefterendstufe 1";
CM_ SG_ 967 MO_Kuehlerluefter_2 "Ansteuertastverhaeltnis (PWM) der Kuehlerluefterendstufe 2";
CM_ SG_ 967 MO_EFLEX_Lampe "Um ein Starten mit E100 zu ermöglichen, wird Kraftstoff ggf. vorgeheizt. Das Signal dient der Anzeige des Heizungsstatus.

Heizung aus -> Lampe aus
Heizung ein -> Lampe ein
Heizung ein und Startversuch -> Lampe blinkend
Heizung nicht möglich -> Lampe";
CM_ SG_ 967 MO_KJS_nicht_bereit "Dieses Signal zeigen einen Fehler der Kühlerjalousie mit unbekannter Stellung der Lamellen. ";
CM_ SG_ 967 MO_ITM_Warnung_Pumpe "Textanzeige: 'Motor sofort abstellen, geschaltete Wasserpumpe defekt / klemmt'";
CM_ SG_ 967 WIV_Anzeige_aktiv "Peilstabsanzeigefunktion aktiv";
CM_ SG_ 967 WIV_Oelmin_Warn "Signal gibt an wenn der Ölstand die Min-Schwelle unterschritten hat";
CM_ SG_ 967 WIV_Sensorfehler "Ölstand/Öltemperatursensor (TOG) defekt";
CM_ SG_ 967 WIV_Schieflage "Fahrzeug steht nicht waagerecht, Messung ungenau";
CM_ SG_ 967 WIV_Oelstand "8 Segmente zur Balkenanzeige des Ölstands";
CM_ SG_ 967 MO_Zustand_HWP "Rückmeldung des  Ansteuerzustand der Hauptwasserpumpe an das Klima-SG .
Der Zustand 'HWP fördert' wird übermittelt, wenn die Schaufeln der Hauptwasserpumpe frei drehen können und die Motordrehzahl und damit die Wasserpumpendrehzahl größer als Null ist. B";
CM_ SG_ 967 OLEV_Systemstoerung "Systemstörung im Ölsystem";
CM_ SG_ 967 MO_Oelwarnung_max "Ölstandswarnung mit der Aufforderung zum Ölwechsel.
Hintergrund: Bei Kraftstoffeintrag (B20) ins Öl verbleibt der RME-Anteil irreversibel im Öl.";
CM_ SG_ 967 WIV_Oelsystem_aktiv "Gesamtölsystem aktiv (entspricht Ölsensor verbaut) und das Ölstand-Untermenu im MMI aktiv";
CM_ SG_ 967 WIV_nicht_betriebswarm "Motor nicht betriebswarm, Messung ungenau";
CM_ SG_ 967 WIV_Ueberfuell_Warn "Ölstand hat die Überfüllschwelle überschritten";
CM_ SG_ 967 WIV_laufender_Motor "Messung bei laufendem Motor nicht möglich";
CM_ SG_ 967 MO_E_Warnungen "Anforderung von Warnanzeigen des E-Systems separat für HEV/BEV bzw. erweiterbar für PHEV";
CM_ SG_ 967 MO_Text_Motorstart "Anzeigetexte für Start/Stopp und Motor-Start";
CM_ SG_ 967 MO_E_Texte "Anforderung von Hinweistexten des E-Systems separat für HEV/BEV bzw. erweiterbar für PHEV";
CM_ SG_ 967 WIV_Oeldyn_avl "Ölstand aus dynamischer Messung vorhanden";
CM_ SG_ 967 MO_Text_Partikelfil_Reg "Über dieses Bit im Kombi wird ein Klartextanzeige erzeugt werden: 'Partikelfilter benötigt Regeneration'.
";
CM_ SG_ 967 OLEV_Oelstand_nicht_vorhanden "Kein aktueller Ölstand vorhanden";
CM_ SG_ 967 WIV_Oelmenge "Ölmenge zwischen Min und Max";
CM_ SG_ 967 MO_Systemlampe "EGas Systemlampe (EPC) oder Vorglühlampe im Kombi, Kombi steuert immer gleiche
LED an, nur über Ziffernblatt wird die EPC von der Vorglühlampe differenziert";
CM_ SG_ 967 MO_OBD2_Lampe "OBD bzw. MIL-Lampe wird vom Motorsteuergerät angesteuert, die Information im Signal GE_OBD_Status wird vom Motorsteuergerät an das Kombi weitergereicht";
CM_ SG_ 967 MO_Heissleuchte "Ansteuerung der Kühlwassertemperatur-Heißleuchte (Sensor nur noch am Motorsteuergerät): Temperaturschaltschwellen mit Hysterese (bei VW D1/Colorado Kombi derzeit noch nicht genutzt).";
CM_ SG_ 967 MO_Partikel_Lampe "Partikelfilter-Lampe wird eingeschaltet";
CM_ SG_ 967 MO_RedFahrleistung_Lampe "Ansteuerung der Turtle-Mode Lampe für E-Traktion Fahrzeuge";
CM_ SG_ 967 WIV_Oelstand_nicht_vorhanden "Kein aktueller Ölstand vorhanden";
CM_ SG_ 967 WIV_nachfuellanzeige_ein "Steuert das Aufblenden der Nachfüllanzeige im Kombi, nach Klemme 15 ein und geöffneter Motorhaube";
CM_ SG_ 967 WIV_Ueberfuell_deaktiv "Unterdrückung der Warnung im Kombi die durch Signal WIV_Ueberfuel_Warn ausgelöst wird";
CM_ SG_ 967 WIV_Unterfuell_Warn "Ölstand hat die Unterfüllschwelle unterschritten";
CM_ SG_ 967 MO_Tankdeckel_Lampe "Ansteuerung Tankdeckel-Warnlampe Kombiinstrument (nur Ottomotoren) z.Zt. Vorhalt VW";
CM_ SG_ 967 MO_Text_Tankdeckelwarn "Textbit der Tankdeckelwarnung, z.Zt. Vorhalt VW";
CM_ SG_ 967 MO_Vorglueh_Lampe "Vorglühlampe im Kombi, Kombi steuert immer gleiche LED an. 
Mit Einführung des Einheits-Kombis sind getrennte Signalwege für Vorglühlampe und EPCL notwendig.";
CM_ SG_ 967 WIV_Oeldr_Warn_Motor "Löst im Kombiinstrument die rote Prio1-Öldruckwarnung (inkl. 3xBeep) aus.
nur MLB: die Warnauslösung erfolgt nur bei gleichzeitig gesetztem 'WIV_Enable_Oeldr_Motor'";
CM_ SG_ 967 MO_E_Mode "Anforderung der E-Mode Statusanzeige";
BA_DEF_ BO_  "DiagRequest" ENUM  "No","Yes";
BA_DEF_ BO_  "DiagResponse" ENUM  "No","Yes";
BA_DEF_ BO_  "DiagState" ENUM  "No","Yes";
BA_DEF_ BO_  "GenMsgChkConstant" HEX 0 4095;
BA_DEF_ BO_  "GenMsgCycleTime" INT 0 65535;
BA_DEF_ BO_  "GenMsgCycleTimeFast" INT 0 65535;
BA_DEF_ BO_  "GenMsgDelayTime" INT 0 100000;
BA_DEF_ BO_  "GenMsgILSupport" ENUM  "No","Yes";
BA_DEF_ BO_  "GenMsgNrOfRepetition" INT 0 100;
BA_DEF_ BO_  "GenMsgPDUConstants" STRING ;
BA_DEF_ BO_  "GenMsgSendType" ENUM  "Cyclic","not_used","not_used","not_used","not_used","not_used","not_used","IfActive","NoMsgSendType";
BA_DEF_ BO_  "GenMsgStartDelayTime" INT 0 100000;
BA_DEF_ BO_  "NmMessage" ENUM  "No","Yes";
BA_DEF_ BO_  "NmhMessage" ENUM  "No","Yes";
BA_DEF_ BO_  "MsgType" ENUM  "Application","NM ","NMH","TP2.0","ISO-TP ","BAP","EID";
BA_DEF_ BO_  "VAGTP20_API" HEX 0 255;
BA_DEF_ BO_  "VAGTP20_DynConnection" ENUM  "No","Yes";
BA_DEF_ BO_  "VAGTP20_DynSetup" ENUM  "No","Yes";
BA_DEF_ BO_  "VAGTP20_StatConnection" ENUM  "No","Yes";
BA_DEF_ SG_  "GenSigActiveRepetitions" INT -2147483648 2147483647;
BA_DEF_ SG_  "GenSigInactiveValue" INT -2147483648 2147483647;
BA_DEF_ SG_  "GenSigSendType" ENUM  "Cyclic","OnWrite","OnWriteWithRepetition","OnChange","OnChangeWithRepetition","IfActive","IfActiveWithRepetition","NoSigSendType","OnChangeAndIfActive","OnChangeAndIfActiveWithRepetition";
BA_DEF_ SG_  "GenSigStartValue" INT -2147483648 2147483647;
BA_DEF_ SG_  "NWM-WakeupAllowed" ENUM  "No","Yes";
BA_DEF_ SG_  "GenSigFuncType" ENUM  "NoFunction","MsgCounter","CRC-8","XOR","XOR-2","DatedBit","SW-Kl15","CHK","Constant","Protocol","CRC-8-SAE_J1850";
BA_DEF_ SG_  "GenSigSwitchedByIgnition" ENUM  "No","Yes";
BA_DEF_ SG_  "Fehlerwert" HEX 0 2147483647;
BA_DEF_ SG_  "GenSigMissingSourceValue" HEX 0 2147483647;
BA_DEF_REL_ BU_SG_REL_  "GenSigTimeoutTime" INT 0 65535;
BA_DEF_DEF_  "DiagRequest" "No";
BA_DEF_DEF_  "DiagResponse" "No";
BA_DEF_DEF_  "DiagState" "No";
BA_DEF_DEF_  "GenMsgChkConstant" 0;
BA_DEF_DEF_  "GenMsgCycleTime" 0;
BA_DEF_DEF_  "GenMsgCycleTimeFast" 0;
BA_DEF_DEF_  "GenMsgDelayTime" 0;
BA_DEF_DEF_  "GenMsgILSupport" "No";
BA_DEF_DEF_  "GenMsgNrOfRepetition" 0;
BA_DEF_DEF_  "GenMsgPDUConstants" "";
BA_DEF_DEF_  "GenMsgSendType" "NoMsgSendType";
BA_DEF_DEF_  "GenMsgStartDelayTime" 0;
BA_DEF_DEF_  "NmMessage" "No";
BA_DEF_DEF_  "NmhMessage" "No";
BA_DEF_DEF_  "MsgType" "Application";
BA_DEF_DEF_  "VAGTP20_API" 0;
BA_DEF_DEF_  "VAGTP20_DynConnection" "No";
BA_DEF_DEF_  "VAGTP20_DynSetup" "No";
BA_DEF_DEF_  "VAGTP20_StatConnection" "No";
BA_DEF_DEF_  "GenSigActiveRepetitions" 0;
BA_DEF_DEF_  "GenSigInactiveValue" 0;
BA_DEF_DEF_  "GenSigSendType" "NoSigSendType";
BA_DEF_DEF_  "GenSigStartValue" 0;
BA_DEF_DEF_  "NWM-WakeupAllowed" "No";
BA_DEF_DEF_  "GenSigFuncType" "NoFunction";
BA_DEF_DEF_  "GenSigSwitchedByIgnition" "Yes";
BA_DEF_DEF_  "Fehlerwert" 0;
BA_DEF_DEF_  "GenSigMissingSourceValue" 0;
BA_DEF_DEF_REL_ "GenSigTimeoutTime" 0;
BA_ "GenMsgSendType" BO_ 1639 0;
BA_ "GenMsgILSupport" BO_ 1639 1;
BA_ "GenMsgDelayTime" BO_ 1639 50;
BA_ "GenMsgCycleTime" BO_ 1639 100;
BA_ "GenMsgSendType" BO_ 957 0;
BA_ "GenMsgILSupport" BO_ 957 1;
BA_ "GenMsgDelayTime" BO_ 957 50;
BA_ "GenMsgCycleTime" BO_ 957 100;
BA_ "GenMsgSendType" BO_ 1178 0;
BA_ "GenMsgPDUConstants" BO_ 1178 "0x9e,0x9e,0x9e,0x9e,0x9e,0x9e,0x9e,0x9e,0x9e,0x9e,0x9e,0x9e,0x9e,0x9e,0x9e,0x9e";
BA_ "GenMsgILSupport" BO_ 1178 1;
BA_ "GenMsgDelayTime" BO_ 1178 50;
BA_ "GenMsgCycleTime" BO_ 1178 100;
BA_ "GenMsgChkConstant" BO_ 1178 158;
BA_ "GenMsgSendType" BO_ 954 0;
BA_ "GenMsgILSupport" BO_ 954 1;
BA_ "GenMsgDelayTime" BO_ 954 50;
BA_ "GenMsgCycleTime" BO_ 954 100;
BA_ "GenMsgSendType" BO_ 956 0;
BA_ "GenMsgILSupport" BO_ 956 1;
BA_ "GenMsgDelayTime" BO_ 956 50;
BA_ "GenMsgCycleTime" BO_ 956 100;
BA_ "GenMsgSendType" BO_ 1180 0;
BA_ "GenMsgPDUConstants" BO_ 1180 "0x98,0x98,0x98,0x98,0x98,0x98,0x98,0x98,0x98,0x98,0x98,0x98,0x98,0x98,0x98,0x98";
BA_ "GenMsgILSupport" BO_ 1180 1;
BA_ "GenMsgDelayTime" BO_ 1180 30;
BA_ "GenMsgCycleTime" BO_ 1180 100;
BA_ "GenMsgChkConstant" BO_ 1180 152;
BA_ "GenMsgSendType" BO_ 1170 0;
BA_ "GenMsgPDUConstants" BO_ 1170 "0x96,0x96,0x96,0x96,0x96,0x96,0x96,0x96,0x96,0x96,0x96,0x96,0x96,0x96,0x96,0x96";
BA_ "GenMsgILSupport" BO_ 1170 1;
BA_ "GenMsgDelayTime" BO_ 1170 30;
BA_ "GenMsgCycleTime" BO_ 1170 100;
BA_ "GenMsgChkConstant" BO_ 1170 150;
BA_ "GenMsgSendType" BO_ 1173 0;
BA_ "GenMsgPDUConstants" BO_ 1173 "0x91,0x91,0x91,0x91,0x91,0x91,0x91,0x91,0x91,0x91,0x91,0x91,0x91,0x91,0x91,0x91";
BA_ "GenMsgILSupport" BO_ 1173 1;
BA_ "GenMsgCycleTime" BO_ 1173 100;
BA_ "GenMsgChkConstant" BO_ 1173 145;
BA_ "GenMsgSendType" BO_ 1171 0;
BA_ "GenMsgPDUConstants" BO_ 1171 "0x97,0x97,0x97,0x97,0x97,0x97,0x97,0x97,0x97,0x97,0x97,0x97,0x97,0x97,0x97,0x97";
BA_ "GenMsgILSupport" BO_ 1171 1;
BA_ "GenMsgDelayTime" BO_ 1171 20;
BA_ "GenMsgCycleTime" BO_ 1171 200;
BA_ "GenMsgChkConstant" BO_ 1171 151;
BA_ "GenMsgSendType" BO_ 817 0;
BA_ "GenMsgILSupport" BO_ 817 1;
BA_ "GenMsgCycleTimeFast" BO_ 817 30;
BA_ "GenMsgCycleTime" BO_ 817 500;
BA_ "GenMsgSendType" BO_ 349 0;
BA_ "GenMsgILSupport" BO_ 349 1;
BA_ "GenMsgDelayTime" BO_ 349 20;
BA_ "GenMsgCycleTime" BO_ 349 500;
BA_ "GenMsgSendType" BO_ 1600 0;
BA_ "GenMsgILSupport" BO_ 1600 1;
BA_ "GenMsgCycleTime" BO_ 1600 320;
BA_ "GenMsgSendType" BO_ 1607 0;
BA_ "GenMsgILSupport" BO_ 1607 1;
BA_ "GenMsgCycleTime" BO_ 1607 320;
BA_ "GenMsgSendType" BO_ 168 0;
BA_ "GenMsgPDUConstants" BO_ 168 "0x52,0x8c,0x50,0xee,0x4f,0xa6,0xcc,0xcf,0x7d,0x2f,0x98,0x6b,0x27,0x41,0x9f,0x93";
BA_ "GenMsgILSupport" BO_ 168 1;
BA_ "GenMsgCycleTime" BO_ 168 100;
BA_ "GenMsgSendType" BO_ 958 0;
BA_ "GenMsgPDUConstants" BO_ 958 "0x1f,0x28,0xc6,0x85,0xe6,0xf8,0xb0,0x19,0x5b,0x64,0x35,0x21,0xe4,0xf7,0x9c,0x24";
BA_ "GenMsgILSupport" BO_ 958 1;
BA_ "GenMsgDelayTime" BO_ 958 10;
BA_ "GenMsgCycleTime" BO_ 958 100;
BA_ "GenMsgSendType" BO_ 1648 0;
BA_ "GenMsgILSupport" BO_ 1648 1;
BA_ "GenMsgDelayTime" BO_ 1648 20;
BA_ "GenMsgCycleTime" BO_ 1648 500;
BA_ "GenMsgSendType" BO_ 289 0;
BA_ "GenMsgPDUConstants" BO_ 289 "0xe9,0x65,0xae,0x6b,0x7b,0x35,0xe5,0x5f,0x4e,0xc7,0x86,0xa2,0xbb,0xdd,0xeb,0xb4";
BA_ "GenMsgILSupport" BO_ 289 1;
BA_ "GenMsgCycleTime" BO_ 289 40;
BA_ "GenMsgSendType" BO_ 967 0;
BA_ "GenMsgILSupport" BO_ 967 1;
BA_ "GenMsgCycleTime" BO_ 967 1000;
BA_ "GenSigSwitchedByIgnition" SG_ 1639 BFS_Fond_Bed_Ack 0;
BA_ "GenSigSendType" SG_ 1639 BFS_Fond_Bed_Ack 3;
BA_ "GenSigSwitchedByIgnition" SG_ 1639 BFS_Lehne_nicht_verriegelt 0;
BA_ "GenSigSendType" SG_ 1639 BFS_Lehne_nicht_verriegelt 3;
BA_ "GenSigSwitchedByIgnition" SG_ 1639 BFS_Klapptisch_offen 0;
BA_ "GenSigSendType" SG_ 1639 BFS_Klapptisch_offen 3;
BA_ "GenSigSwitchedByIgnition" SG_ 1639 BFS_Sitzsym_Fahrt_aktiv 0;
BA_ "GenSigSendType" SG_ 1639 BFS_Sitzsym_Fahrt_aktiv 3;
BA_ "GenSigSwitchedByIgnition" SG_ 1639 BFS_Sitzfahrt_aktiv 0;
BA_ "GenSigSendType" SG_ 1639 BFS_Sitzfahrt_aktiv 3;
BA_ "GenSigSwitchedByIgnition" SG_ 1639 BFS_SLV_aktiv 0;
BA_ "GenSigSendType" SG_ 1639 BFS_SLV_aktiv 3;
BA_ "GenSigSwitchedByIgnition" SG_ 1639 BFS_SHV_aktiv 0;
BA_ "GenSigSendType" SG_ 1639 BFS_SHV_aktiv 3;
BA_ "GenSigSwitchedByIgnition" SG_ 1639 BFS_LNV_aktiv 0;
BA_ "GenSigSendType" SG_ 1639 BFS_LNV_aktiv 3;
BA_ "GenSigSwitchedByIgnition" SG_ 1639 BFS_SNV_aktiv 0;
BA_ "GenSigSendType" SG_ 1639 BFS_SNV_aktiv 3;
BA_ "GenSigSwitchedByIgnition" SG_ 1639 BFS_KSV_aktiv 0;
BA_ "GenSigSendType" SG_ 1639 BFS_KSV_aktiv 3;
BA_ "GenSigSwitchedByIgnition" SG_ 1639 BFS_LKV_aktiv 0;
BA_ "GenSigSendType" SG_ 1639 BFS_LKV_aktiv 3;
BA_ "GenSigSwitchedByIgnition" SG_ 1639 BFS_STV_aktiv 0;
BA_ "GenSigSendType" SG_ 1639 BFS_STV_aktiv 3;
BA_ "GenSigSwitchedByIgnition" SG_ 1639 BFS_LHV_aktiv 0;
BA_ "GenSigSendType" SG_ 1639 BFS_LHV_aktiv 3;
BA_ "GenSigSwitchedByIgnition" SG_ 1639 BFS_LWV_aktiv 0;
BA_ "GenSigSendType" SG_ 1639 BFS_LWV_aktiv 3;
BA_ "GenSigSwitchedByIgnition" SG_ 1639 BFS_GHV_aktiv 0;
BA_ "GenSigSendType" SG_ 1639 BFS_GHV_aktiv 3;
BA_ "GenSigSwitchedByIgnition" SG_ 1639 BFS_KSS_Fahrt_aktiv 0;
BA_ "GenSigSendType" SG_ 1639 BFS_KSS_Fahrt_aktiv 3;
BA_ "GenSigSwitchedByIgnition" SG_ 1639 BFS_MMB_lokal_Stop 0;
BA_ "GenSigSendType" SG_ 1639 BFS_MMB_lokal_Stop 3;
BA_ "GenSigSwitchedByIgnition" SG_ 1639 BFS_Ruhestellung_Status 0;
BA_ "GenSigSendType" SG_ 1639 BFS_Ruhestellung_Status 3;
BA_ "GenSigSwitchedByIgnition" SG_ 1639 BFS_Seat_Locked 0;
BA_ "GenSigSendType" SG_ 1639 BFS_Seat_Locked 0;
BA_ "GenSigSwitchedByIgnition" SG_ 1639 BFS_MMB_storage 0;
BA_ "GenSigSendType" SG_ 1639 BFS_MMB_storage 3;
BA_ "GenSigSwitchedByIgnition" SG_ 1639 BFS_MMB_tipp 0;
BA_ "GenSigSendType" SG_ 1639 BFS_MMB_tipp 3;
BA_ "GenSigSwitchedByIgnition" SG_ 1639 BFS_MMB_tast 0;
BA_ "GenSigSendType" SG_ 1639 BFS_MMB_tast 3;
BA_ "GenSigSwitchedByIgnition" SG_ 1639 BFS_MMB_store_LED_on 0;
BA_ "GenSigSendType" SG_ 1639 BFS_MMB_store_LED_on 3;
BA_ "GenSigSwitchedByIgnition" SG_ 1639 BFS_MMB_storage_beep 0;
BA_ "GenSigSendType" SG_ 1639 BFS_MMB_storage_beep 3;
BA_ "GenSigSwitchedByIgnition" SG_ 1639 BFS_MMB_store 0;
BA_ "GenSigSendType" SG_ 1639 BFS_MMB_store 3;
BA_ "GenSigSwitchedByIgnition" SG_ 1639 BFS_MMB_glob_stop 0;
BA_ "GenSigSendType" SG_ 1639 BFS_MMB_glob_stop 3;
BA_ "GenSigSwitchedByIgnition" SG_ 957 Mem_BFSFo_Lordose_hoch 0;
BA_ "GenSigSendType" SG_ 957 Mem_BFSFo_Lordose_hoch 3;
BA_ "GenSigSwitchedByIgnition" SG_ 957 Mem_BFSFo_Lordose_runter 0;
BA_ "GenSigSendType" SG_ 957 Mem_BFSFo_Lordose_runter 3;
BA_ "GenSigSwitchedByIgnition" SG_ 957 Mem_BFSFo_Lordose_vor 0;
BA_ "GenSigSendType" SG_ 957 Mem_BFSFo_Lordose_vor 3;
BA_ "GenSigSwitchedByIgnition" SG_ 957 Mem_BFSFo_Lordose_zurueck 0;
BA_ "GenSigSendType" SG_ 957 Mem_BFSFo_Lordose_zurueck 3;
BA_ "GenSigSwitchedByIgnition" SG_ 957 Mem_BFSFo_Massage_Geschw 0;
BA_ "GenSigSendType" SG_ 957 Mem_BFSFo_Massage_Geschw 3;
BA_ "GenSigSwitchedByIgnition" SG_ 957 Mem_BFSFo_Massage_Intens 0;
BA_ "GenSigSendType" SG_ 957 Mem_BFSFo_Massage_Intens 3;
BA_ "GenSigSwitchedByIgnition" SG_ 957 Mem_BFSFo_MMB_storage 0;
BA_ "GenSigSendType" SG_ 957 Mem_BFSFo_MMB_storage 3;
BA_ "GenSigSwitchedByIgnition" SG_ 957 Mem_BFSFo_Massage_Prg 0;
BA_ "GenSigSendType" SG_ 957 Mem_BFSFo_Massage_Prg 3;
BA_ "GenSigSwitchedByIgnition" SG_ 957 Mem_BFSFo_MMB_tast 0;
BA_ "GenSigSendType" SG_ 957 Mem_BFSFo_MMB_tast 3;
BA_ "GenSigSwitchedByIgnition" SG_ 957 Mem_BFSFo_MMB_tipp 0;
BA_ "GenSigSendType" SG_ 957 Mem_BFSFo_MMB_tipp 3;
BA_ "GenSigSwitchedByIgnition" SG_ 957 Mem_BFSFo_MMB_glob_Stop 0;
BA_ "GenSigSendType" SG_ 957 Mem_BFSFo_MMB_glob_Stop 3;
BA_ "GenSigSwitchedByIgnition" SG_ 957 Mem_BFSFo_Sitztiefe_vor 0;
BA_ "GenSigSendType" SG_ 957 Mem_BFSFo_Sitztiefe_vor 3;
BA_ "GenSigSwitchedByIgnition" SG_ 957 Mem_BFSFo_Sitztiefe_zur 0;
BA_ "GenSigSendType" SG_ 957 Mem_BFSFo_Sitztiefe_zur 3;
BA_ "GenSigSwitchedByIgnition" SG_ 957 Mem_BFSFo_MMB_store 0;
BA_ "GenSigSendType" SG_ 957 Mem_BFSFo_MMB_store 3;
BA_ "GenSigSwitchedByIgnition" SG_ 957 Mem_BFSFo_MMB_storage_beep 0;
BA_ "GenSigSendType" SG_ 957 Mem_BFSFo_MMB_storage_beep 3;
BA_ "GenSigSwitchedByIgnition" SG_ 957 Mem_BFSFo_MMB_store_LED_on 0;
BA_ "GenSigSendType" SG_ 957 Mem_BFSFo_MMB_store_LED_on 3;
BA_ "GenSigSwitchedByIgnition" SG_ 957 Mem_BFSFo_BeifaSitzverstellung 0;
BA_ "GenSigSendType" SG_ 957 Mem_BFSFo_BeifaSitzverstellung 3;
BA_ "GenSigSwitchedByIgnition" SG_ 957 Mem_BFSFo_MMB_lokal_Stop 0;
BA_ "GenSigSendType" SG_ 957 Mem_BFSFo_MMB_lokal_Stop 3;
BA_ "GenSigSwitchedByIgnition" SG_ 957 Mem_BFSFo_Sitzfahrt_aktiv 0;
BA_ "GenSigSendType" SG_ 957 Mem_BFSFo_Sitzfahrt_aktiv 3;
BA_ "GenSigSwitchedByIgnition" SG_ 957 Mem_BFSFo_BFS_Freigabe 0;
BA_ "GenSigSendType" SG_ 957 Mem_BFSFo_BFS_Freigabe 3;
BA_ "GenSigSwitchedByIgnition" SG_ 957 Mem_BFSFo_RSE_zurueck 0;
BA_ "GenSigSendType" SG_ 957 Mem_BFSFo_RSE_zurueck 3;
BA_ "GenSigSwitchedByIgnition" SG_ 957 Mem_BFSFo_RSE_vor 0;
BA_ "GenSigSendType" SG_ 957 Mem_BFSFo_RSE_vor 3;
BA_ "GenSigSwitchedByIgnition" SG_ 957 Mem_BFSFo_Business_anfahren 0;
BA_ "GenSigSendType" SG_ 957 Mem_BFSFo_Business_anfahren 3;
BA_ "GenSigSwitchedByIgnition" SG_ 957 Mem_BFSFo_Relax_anfahren 0;
BA_ "GenSigSendType" SG_ 957 Mem_BFSFo_Relax_anfahren 3;
BA_ "GenSigSwitchedByIgnition" SG_ 957 BFS_Kopfstuetze_vor 0;
BA_ "GenSigSendType" SG_ 957 BFS_Kopfstuetze_vor 0;
BA_ "GenSigSwitchedByIgnition" SG_ 957 BFS_Kopfstuetze_zurueck 0;
BA_ "GenSigSendType" SG_ 957 BFS_Kopfstuetze_zurueck 0;
BA_ "GenSigSwitchedByIgnition" SG_ 957 Mem_BFSFo_BFS_RSE_Freigabe 0;
BA_ "GenSigSendType" SG_ 957 Mem_BFSFo_BFS_RSE_Freigabe 3;
BA_ "GenSigSwitchedByIgnition" SG_ 957 Mem_BFSFo_Fusstuetze_runter 0;
BA_ "GenSigSendType" SG_ 957 Mem_BFSFo_Fusstuetze_runter 3;
BA_ "GenSigSwitchedByIgnition" SG_ 957 Mem_BFSFo_Fusstuetze_hoch 0;
BA_ "GenSigSendType" SG_ 957 Mem_BFSFo_Fusstuetze_hoch 3;
BA_ "GenSigSwitchedByIgnition" SG_ 1178 FS_Fond_Bed_enable 0;
BA_ "GenSigSendType" SG_ 1178 FS_Fond_Bed_enable 3;
BA_ "GenSigSwitchedByIgnition" SG_ 1178 FS_Lehne_nicht_verriegelt 0;
BA_ "GenSigSendType" SG_ 1178 FS_Lehne_nicht_verriegelt 3;
BA_ "GenSigSwitchedByIgnition" SG_ 1178 FS_Spezialposition_anfahren 0;
BA_ "GenSigSendType" SG_ 1178 FS_Spezialposition_anfahren 3;
BA_ "GenSigSwitchedByIgnition" SG_ 1178 FS_BFS_Sitzsym_Anfahrt 0;
BA_ "GenSigSendType" SG_ 1178 FS_BFS_Sitzsym_Anfahrt 3;
BA_ "GenSigSwitchedByIgnition" SG_ 1178 FS_Sitzfahrt_aktiv 0;
BA_ "GenSigSendType" SG_ 1178 FS_Sitzfahrt_aktiv 3;
BA_ "GenSigSwitchedByIgnition" SG_ 1178 FS_SLV_aktiv 0;
BA_ "GenSigSendType" SG_ 1178 FS_SLV_aktiv 3;
BA_ "GenSigSwitchedByIgnition" SG_ 1178 FS_SHV_aktiv 0;
BA_ "GenSigSendType" SG_ 1178 FS_SHV_aktiv 3;
BA_ "GenSigSwitchedByIgnition" SG_ 1178 FS_LNV_aktiv 0;
BA_ "GenSigSendType" SG_ 1178 FS_LNV_aktiv 3;
BA_ "GenSigSwitchedByIgnition" SG_ 1178 FS_SNV_aktiv 0;
BA_ "GenSigSendType" SG_ 1178 FS_SNV_aktiv 3;
BA_ "GenSigSwitchedByIgnition" SG_ 1178 FS_KSV_aktiv 0;
BA_ "GenSigSendType" SG_ 1178 FS_KSV_aktiv 3;
BA_ "GenSigSwitchedByIgnition" SG_ 1178 FS_LKV_aktiv 0;
BA_ "GenSigSendType" SG_ 1178 FS_LKV_aktiv 3;
BA_ "GenSigSwitchedByIgnition" SG_ 1178 FS_STV_aktiv 0;
BA_ "GenSigSendType" SG_ 1178 FS_STV_aktiv 3;
BA_ "GenSigSwitchedByIgnition" SG_ 1178 FS_LHV_aktiv 0;
BA_ "GenSigSendType" SG_ 1178 FS_LHV_aktiv 3;
BA_ "GenSigSwitchedByIgnition" SG_ 1178 FS_LWV_aktiv 0;
BA_ "GenSigSendType" SG_ 1178 FS_LWV_aktiv 3;
BA_ "GenSigSwitchedByIgnition" SG_ 1178 FS_GHV_aktiv 0;
BA_ "GenSigSendType" SG_ 1178 FS_GHV_aktiv 3;
BA_ "GenSigSwitchedByIgnition" SG_ 1178 FS_BFS_KSS_Anfahrt 0;
BA_ "GenSigSendType" SG_ 1178 FS_BFS_KSS_Anfahrt 3;
BA_ "GenSigSwitchedByIgnition" SG_ 1178 FS_MMB_lokal_Stop 0;
BA_ "GenSigSendType" SG_ 1178 FS_MMB_lokal_Stop 3;
BA_ "GenSigSwitchedByIgnition" SG_ 1178 FS_MMB_storage 0;
BA_ "GenSigSendType" SG_ 1178 FS_MMB_storage 3;
BA_ "GenSigSwitchedByIgnition" SG_ 1178 FS_MMB_tipp 0;
BA_ "GenSigSendType" SG_ 1178 FS_MMB_tipp 3;
BA_ "GenSigSwitchedByIgnition" SG_ 1178 FS_MMB_tast 0;
BA_ "GenSigSendType" SG_ 1178 FS_MMB_tast 3;
BA_ "GenSigSwitchedByIgnition" SG_ 1178 FS_MMB_store_LED_on 0;
BA_ "GenSigSendType" SG_ 1178 FS_MMB_store_LED_on 3;
BA_ "GenSigSwitchedByIgnition" SG_ 1178 FS_MMB_storage_beep 0;
BA_ "GenSigSendType" SG_ 1178 FS_MMB_storage_beep 3;
BA_ "GenSigSwitchedByIgnition" SG_ 1178 FS_MMB_store 0;
BA_ "GenSigSendType" SG_ 1178 FS_MMB_store 3;
BA_ "GenSigSwitchedByIgnition" SG_ 1178 FS_MMB_glob_stop 0;
BA_ "GenSigSendType" SG_ 1178 FS_MMB_glob_stop 3;
BA_ "GenSigSwitchedByIgnition" SG_ 1178 FS_EE_Fond_FS_enable 0;
BA_ "GenSigSendType" SG_ 1178 FS_EE_Fond_FS_enable 3;
BA_ "GenSigSwitchedByIgnition" SG_ 1178 FS_EE_Fond_BFS_enable 0;
BA_ "GenSigSendType" SG_ 1178 FS_EE_Fond_BFS_enable 3;
BA_ "GenSigSwitchedByIgnition" SG_ 1178 FS_BFS_Fond_Verst_enable 0;
BA_ "GenSigSendType" SG_ 1178 FS_BFS_Fond_Verst_enable 3;
BA_ "GenSigSwitchedByIgnition" SG_ 1178 FS_EE_BFS_enable 0;
BA_ "GenSigSendType" SG_ 1178 FS_EE_BFS_enable 3;
BA_ "GenSigSwitchedByIgnition" SG_ 954 Mem_FS_Lordose_hoch 0;
BA_ "GenSigSendType" SG_ 954 Mem_FS_Lordose_hoch 3;
BA_ "GenSigSwitchedByIgnition" SG_ 954 Mem_FS_Lordose_runter 0;
BA_ "GenSigSendType" SG_ 954 Mem_FS_Lordose_runter 3;
BA_ "GenSigSwitchedByIgnition" SG_ 954 Mem_FS_Lordose_vor 0;
BA_ "GenSigSendType" SG_ 954 Mem_FS_Lordose_vor 3;
BA_ "GenSigSwitchedByIgnition" SG_ 954 Mem_FS_Lordose_zurueck 0;
BA_ "GenSigSendType" SG_ 954 Mem_FS_Lordose_zurueck 3;
BA_ "GenSigSwitchedByIgnition" SG_ 954 Mem_FS_Massage_Geschw 0;
BA_ "GenSigSendType" SG_ 954 Mem_FS_Massage_Geschw 3;
BA_ "GenSigSwitchedByIgnition" SG_ 954 Mem_FS_Massage_Intensitaet 0;
BA_ "GenSigSendType" SG_ 954 Mem_FS_Massage_Intensitaet 3;
BA_ "GenSigSwitchedByIgnition" SG_ 954 Mem_FS_SWangenLehne_beluef 0;
BA_ "GenSigSendType" SG_ 954 Mem_FS_SWangenLehne_beluef 3;
BA_ "GenSigSwitchedByIgnition" SG_ 954 Mem_FS_SWangenLehne_entlue 0;
BA_ "GenSigSendType" SG_ 954 Mem_FS_SWangenLehne_entlue 3;
BA_ "GenSigSwitchedByIgnition" SG_ 954 Mem_FS_Massage_Programm 0;
BA_ "GenSigSendType" SG_ 954 Mem_FS_Massage_Programm 3;
BA_ "GenSigSwitchedByIgnition" SG_ 954 Mem_FS_SWangenSitz_beluef 0;
BA_ "GenSigSendType" SG_ 954 Mem_FS_SWangenSitz_beluef 3;
BA_ "GenSigSwitchedByIgnition" SG_ 954 Mem_FS_SWangenSitz_entlue 0;
BA_ "GenSigSendType" SG_ 954 Mem_FS_SWangenSitz_entlue 3;
BA_ "GenSigSwitchedByIgnition" SG_ 954 FS_BFS_aufraeumen 0;
BA_ "GenSigSendType" SG_ 954 FS_BFS_aufraeumen 3;
BA_ "GenSigSwitchedByIgnition" SG_ 954 FS_BFSFo_aufraeumen 0;
BA_ "GenSigSendType" SG_ 954 FS_BFSFo_aufraeumen 3;
BA_ "GenSigSwitchedByIgnition" SG_ 954 FS_FSFo_aufraeumen 0;
BA_ "GenSigSendType" SG_ 954 FS_FSFo_aufraeumen 3;
BA_ "GenSigSwitchedByIgnition" SG_ 954 FS_BFS_Multifunktionstaster_hoch 0;
BA_ "GenSigSendType" SG_ 954 FS_BFS_Multifunktionstaster_hoch 3;
BA_ "GenSigSwitchedByIgnition" SG_ 954 FS_BFS_Multifunktionstaster_tief 0;
BA_ "GenSigSendType" SG_ 954 FS_BFS_Multifunktionstaster_tief 3;
BA_ "GenSigSwitchedByIgnition" SG_ 954 FS_BFS_Multifunktionstaster_vor 0;
BA_ "GenSigSendType" SG_ 954 FS_BFS_Multifunktionstaster_vor 3;
BA_ "GenSigSwitchedByIgnition" SG_ 954 FS_BFS_Multifunktionstaster_zur 0;
BA_ "GenSigSendType" SG_ 954 FS_BFS_Multifunktionstaster_zur 3;
BA_ "GenSigSwitchedByIgnition" SG_ 954 FS_BFS_Programmwippe_hoch 0;
BA_ "GenSigSendType" SG_ 954 FS_BFS_Programmwippe_hoch 3;
BA_ "GenSigSwitchedByIgnition" SG_ 954 FS_BFS_Programmwippe_tief 0;
BA_ "GenSigSendType" SG_ 954 FS_BFS_Programmwippe_tief 3;
BA_ "GenSigSwitchedByIgnition" SG_ 954 FS_BFS_SHV_Taste_hoch 0;
BA_ "GenSigSendType" SG_ 954 FS_BFS_SHV_Taste_hoch 3;
BA_ "GenSigSwitchedByIgnition" SG_ 954 FS_BFS_SHV_Taste_tief 0;
BA_ "GenSigSendType" SG_ 954 FS_BFS_SHV_Taste_tief 3;
BA_ "GenSigSwitchedByIgnition" SG_ 954 FS_BFS_SLV_Taste_vor 0;
BA_ "GenSigSendType" SG_ 954 FS_BFS_SLV_Taste_vor 3;
BA_ "GenSigSwitchedByIgnition" SG_ 954 FS_BFS_SLV_Taste_zurueck 0;
BA_ "GenSigSendType" SG_ 954 FS_BFS_SLV_Taste_zurueck 3;
BA_ "GenSigSwitchedByIgnition" SG_ 954 FS_BFS_SNV_Taste_hoch 0;
BA_ "GenSigSendType" SG_ 954 FS_BFS_SNV_Taste_hoch 3;
BA_ "GenSigSwitchedByIgnition" SG_ 954 FS_BFS_SNV_Taste_tief 0;
BA_ "GenSigSendType" SG_ 954 FS_BFS_SNV_Taste_tief 3;
BA_ "GenSigSwitchedByIgnition" SG_ 954 FS_BFS_KSV_Taste_hoch 0;
BA_ "GenSigSendType" SG_ 954 FS_BFS_KSV_Taste_hoch 3;
BA_ "GenSigSwitchedByIgnition" SG_ 954 FS_BFS_KSV_Taste_tief 0;
BA_ "GenSigSendType" SG_ 954 FS_BFS_KSV_Taste_tief 3;
BA_ "GenSigSwitchedByIgnition" SG_ 954 FS_BFS_LNV_Taste_vor 0;
BA_ "GenSigSendType" SG_ 954 FS_BFS_LNV_Taste_vor 3;
BA_ "GenSigSwitchedByIgnition" SG_ 954 FS_BFS_LNV_Taste_zurueck 0;
BA_ "GenSigSendType" SG_ 954 FS_BFS_LNV_Taste_zurueck 3;
BA_ "GenSigSwitchedByIgnition" SG_ 954 FS_BFS_Massage_Taste 0;
BA_ "GenSigSendType" SG_ 954 FS_BFS_Massage_Taste 3;
BA_ "GenSigSwitchedByIgnition" SG_ 956 Mem_FSFo_Lordose_hoch 0;
BA_ "GenSigSendType" SG_ 956 Mem_FSFo_Lordose_hoch 3;
BA_ "GenSigSwitchedByIgnition" SG_ 956 Mem_FSFo_Lordose_runter 0;
BA_ "GenSigSendType" SG_ 956 Mem_FSFo_Lordose_runter 3;
BA_ "GenSigSwitchedByIgnition" SG_ 956 Mem_FSFo_Lordose_vor 0;
BA_ "GenSigSendType" SG_ 956 Mem_FSFo_Lordose_vor 3;
BA_ "GenSigSwitchedByIgnition" SG_ 956 Mem_FSFo_Lordose_zurueck 0;
BA_ "GenSigSendType" SG_ 956 Mem_FSFo_Lordose_zurueck 3;
BA_ "GenSigSwitchedByIgnition" SG_ 956 Mem_FSFo_Massage_Geschw 0;
BA_ "GenSigSendType" SG_ 956 Mem_FSFo_Massage_Geschw 3;
BA_ "GenSigSwitchedByIgnition" SG_ 956 Mem_FSFo_Massage_Intens 0;
BA_ "GenSigSendType" SG_ 956 Mem_FSFo_Massage_Intens 3;
BA_ "GenSigSwitchedByIgnition" SG_ 956 Mem_FSFo_MMB_storage 0;
BA_ "GenSigSendType" SG_ 956 Mem_FSFo_MMB_storage 3;
BA_ "GenSigSwitchedByIgnition" SG_ 956 Mem_FSFo_Massage_Prg 0;
BA_ "GenSigSendType" SG_ 956 Mem_FSFo_Massage_Prg 3;
BA_ "GenSigSwitchedByIgnition" SG_ 956 Mem_FSFo_MMB_tast 0;
BA_ "GenSigSendType" SG_ 956 Mem_FSFo_MMB_tast 3;
BA_ "GenSigSwitchedByIgnition" SG_ 956 Mem_FSFo_MMB_tipp 0;
BA_ "GenSigSendType" SG_ 956 Mem_FSFo_MMB_tipp 3;
BA_ "GenSigSwitchedByIgnition" SG_ 956 Mem_FSFo_MMB_glob_Stop 0;
BA_ "GenSigSendType" SG_ 956 Mem_FSFo_MMB_glob_Stop 3;
BA_ "GenSigSwitchedByIgnition" SG_ 956 Mem_FSFo_Sitztiefe_vor 0;
BA_ "GenSigSendType" SG_ 956 Mem_FSFo_Sitztiefe_vor 3;
BA_ "GenSigSwitchedByIgnition" SG_ 956 Mem_FSFo_Sitztiefe_zur 0;
BA_ "GenSigSendType" SG_ 956 Mem_FSFo_Sitztiefe_zur 3;
BA_ "GenSigSwitchedByIgnition" SG_ 956 Mem_FSFo_MMB_store 0;
BA_ "GenSigSendType" SG_ 956 Mem_FSFo_MMB_store 3;
BA_ "GenSigSwitchedByIgnition" SG_ 956 Mem_FSFo_MMB_storage_beep 0;
BA_ "GenSigSendType" SG_ 956 Mem_FSFo_MMB_storage_beep 3;
BA_ "GenSigSwitchedByIgnition" SG_ 956 Mem_FSFo_MMB_store_LED_on 0;
BA_ "GenSigSendType" SG_ 956 Mem_FSFo_MMB_store_LED_on 3;
BA_ "GenSigSwitchedByIgnition" SG_ 956 Mem_FSFo_MMB_lokal_Stop 0;
BA_ "GenSigSendType" SG_ 956 Mem_FSFo_MMB_lokal_Stop 3;
BA_ "GenSigSwitchedByIgnition" SG_ 956 Mem_FSFo_Sitzfahrt_aktiv 0;
BA_ "GenSigSendType" SG_ 956 Mem_FSFo_Sitzfahrt_aktiv 3;
BA_ "GenSigSwitchedByIgnition" SG_ 956 Mem_FSFo_Business_anfahren 0;
BA_ "GenSigSendType" SG_ 956 Mem_FSFo_Business_anfahren 3;
BA_ "GenSigSwitchedByIgnition" SG_ 956 Mem_FSFo_Relax_anfahren 0;
BA_ "GenSigSendType" SG_ 956 Mem_FSFo_Relax_anfahren 3;
BA_ "GenSigFuncType" SG_ 1180 Mem_Taster_BT_01_CRC 2;
BA_ "GenSigSendType" SG_ 1180 Mem_Taster_BT_01_CRC 0;
BA_ "GenSigSwitchedByIgnition" SG_ 1180 Mem_Taster_BT_01_BZ 0;
BA_ "GenSigFuncType" SG_ 1180 Mem_Taster_BT_01_BZ 1;
BA_ "GenSigSendType" SG_ 1180 Mem_Taster_BT_01_BZ 0;
BA_ "GenSigSwitchedByIgnition" SG_ 1180 MTBT_Pos1 0;
BA_ "GenSigSendType" SG_ 1180 MTBT_Pos1 3;
BA_ "GenSigSwitchedByIgnition" SG_ 1180 MTBT_Pos2 0;
BA_ "GenSigSendType" SG_ 1180 MTBT_Pos2 3;
BA_ "GenSigSwitchedByIgnition" SG_ 1180 MTBT_Pos3 0;
BA_ "GenSigSendType" SG_ 1180 MTBT_Pos3 3;
BA_ "GenSigSwitchedByIgnition" SG_ 1180 MTBT_Pos4 0;
BA_ "GenSigSendType" SG_ 1180 MTBT_Pos4 3;
BA_ "GenSigSwitchedByIgnition" SG_ 1180 MTBT_On_Off 0;
BA_ "GenSigSendType" SG_ 1180 MTBT_On_Off 3;
BA_ "GenSigSwitchedByIgnition" SG_ 1180 MTBT_M_Taste 0;
BA_ "GenSigSendType" SG_ 1180 MTBT_M_Taste 3;
BA_ "GenSigFuncType" SG_ 1170 Mem_Taster_FT_01_CRC 2;
BA_ "GenSigSendType" SG_ 1170 Mem_Taster_FT_01_CRC 0;
BA_ "GenSigSwitchedByIgnition" SG_ 1170 Mem_Taster_FT_01_BZ 0;
BA_ "GenSigFuncType" SG_ 1170 Mem_Taster_FT_01_BZ 1;
BA_ "GenSigSendType" SG_ 1170 Mem_Taster_FT_01_BZ 0;
BA_ "GenSigSwitchedByIgnition" SG_ 1170 MTFT_Pos1_EE 0;
BA_ "GenSigSendType" SG_ 1170 MTFT_Pos1_EE 3;
BA_ "GenSigSwitchedByIgnition" SG_ 1170 MTFT_Pos2 0;
BA_ "GenSigSendType" SG_ 1170 MTFT_Pos2 3;
BA_ "GenSigSwitchedByIgnition" SG_ 1170 MTFT_Pos3 0;
BA_ "GenSigSendType" SG_ 1170 MTFT_Pos3 3;
BA_ "GenSigSwitchedByIgnition" SG_ 1170 MTFT_Pos4 0;
BA_ "GenSigSendType" SG_ 1170 MTFT_Pos4 3;
BA_ "GenSigSwitchedByIgnition" SG_ 1170 MTFT_On_Off 0;
BA_ "GenSigSendType" SG_ 1170 MTFT_On_Off 3;
BA_ "GenSigSwitchedByIgnition" SG_ 1170 MTFT_Verst_akt 0;
BA_ "GenSigSendType" SG_ 1170 MTFT_Verst_akt 3;
BA_ "GenSigSwitchedByIgnition" SG_ 1170 MTFT_M_Taste 0;
BA_ "GenSigSendType" SG_ 1170 MTFT_M_Taste 3;
BA_ "GenSigFuncType" SG_ 1173 MTHBF_CRC 2;
BA_ "GenSigSendType" SG_ 1173 MTHBF_CRC 0;
BA_ "GenSigSwitchedByIgnition" SG_ 1173 MTHBF_BZ 0;
BA_ "GenSigFuncType" SG_ 1173 MTHBF_BZ 1;
BA_ "GenSigSendType" SG_ 1173 MTHBF_BZ 0;
BA_ "GenSigSwitchedByIgnition" SG_ 1173 BFS_Sitzhoehe_hoch 0;
BA_ "GenSigSendType" SG_ 1173 BFS_Sitzhoehe_hoch 0;
BA_ "GenSigSwitchedByIgnition" SG_ 1173 BFS_Sitzhoehe_runter 0;
BA_ "GenSigSendType" SG_ 1173 BFS_Sitzhoehe_runter 0;
BA_ "GenSigSwitchedByIgnition" SG_ 1173 MTHBF_ein 0;
BA_ "GenSigSendType" SG_ 1173 MTHBF_ein 0;
BA_ "GenSigSwitchedByIgnition" SG_ 1173 BFS_Laengsverst_vor 0;
BA_ "GenSigSendType" SG_ 1173 BFS_Laengsverst_vor 0;
BA_ "GenSigSwitchedByIgnition" SG_ 1173 BFS_Laengsverst_zurueck 0;
BA_ "GenSigSendType" SG_ 1173 BFS_Laengsverst_zurueck 0;
BA_ "GenSigSwitchedByIgnition" SG_ 1173 BFS_Lehnenneigung_vor 0;
BA_ "GenSigSendType" SG_ 1173 BFS_Lehnenneigung_vor 0;
BA_ "GenSigSwitchedByIgnition" SG_ 1173 BFS_Lehnenneigung_zurueck 0;
BA_ "GenSigSendType" SG_ 1173 BFS_Lehnenneigung_zurueck 0;
BA_ "GenSigSwitchedByIgnition" SG_ 1173 BFS_Lehnenkopf_vor 0;
BA_ "GenSigSendType" SG_ 1173 BFS_Lehnenkopf_vor 0;
BA_ "GenSigSwitchedByIgnition" SG_ 1173 BFS_Lehnenkopf_zurueck 0;
BA_ "GenSigSendType" SG_ 1173 BFS_Lehnenkopf_zurueck 0;
BA_ "GenSigSwitchedByIgnition" SG_ 1173 BFS_Kopfstuetzen_hoch 0;
BA_ "GenSigSendType" SG_ 1173 BFS_Kopfstuetzen_hoch 0;
BA_ "GenSigSwitchedByIgnition" SG_ 1173 BFS_Kopfstuetzen_runter 0;
BA_ "GenSigSendType" SG_ 1173 BFS_Kopfstuetzen_runter 0;
BA_ "GenSigSwitchedByIgnition" SG_ 1171 MFG_01_CRC 0;
BA_ "GenSigFuncType" SG_ 1171 MFG_01_CRC 2;
BA_ "GenSigSendType" SG_ 1171 MFG_01_CRC 0;
BA_ "GenSigSwitchedByIgnition" SG_ 1171 MFG_01_BZ 0;
BA_ "GenSigFuncType" SG_ 1171 MFG_01_BZ 1;
BA_ "GenSigSendType" SG_ 1171 MFG_01_BZ 0;
BA_ "GenSigSwitchedByIgnition" SG_ 1171 MF_ZV_Lock 0;
BA_ "GenSigSendType" SG_ 1171 MF_ZV_Lock 3;
BA_ "GenSigSwitchedByIgnition" SG_ 1171 MF_Motorweiterlauf 0;
BA_ "GenSigSendType" SG_ 1171 MF_Motorweiterlauf 3;
BA_ "GenSigSwitchedByIgnition" SG_ 1171 MF_Abzugssperre 0;
BA_ "GenSigSendType" SG_ 1171 MF_Abzugssperre 3;
BA_ "GenSigSwitchedByIgnition" SG_ 1171 MF_Anlassersperre 0;
BA_ "GenSigSendType" SG_ 1171 MF_Anlassersperre 3;
BA_ "GenSigSwitchedByIgnition" SG_ 1171 MF_Variante 0;
BA_ "GenSigSendType" SG_ 1171 MF_Variante 3;
BA_ "GenSigSwitchedByIgnition" SG_ 1171 MF_Schluessel_scan 0;
BA_ "GenSigSendType" SG_ 1171 MF_Schluessel_scan 3;
BA_ "GenSigSwitchedByIgnition" SG_ 1171 MF_Laderelais 0;
BA_ "GenSigSendType" SG_ 1171 MF_Laderelais 3;
BA_ "GenSigSwitchedByIgnition" SG_ 1171 MF_StartStopp_Info 0;
BA_ "GenSigSendType" SG_ 1171 MF_StartStopp_Info 0;
BA_ "GenSigSwitchedByIgnition" SG_ 1171 MF_Fernbed_ein 0;
BA_ "GenSigSendType" SG_ 1171 MF_Fernbed_ein 3;
BA_ "GenSigSwitchedByIgnition" SG_ 1171 MF_Standlicht 0;
BA_ "GenSigSendType" SG_ 1171 MF_Standlicht 3;
BA_ "GenSigSwitchedByIgnition" SG_ 1171 MF_Fahrlicht 0;
BA_ "GenSigSendType" SG_ 1171 MF_Fahrlicht 3;
BA_ "GenSigSwitchedByIgnition" SG_ 1171 MF_interm_Fernlicht 0;
BA_ "GenSigSendType" SG_ 1171 MF_interm_Fernlicht 3;
BA_ "GenSigSwitchedByIgnition" SG_ 1171 MF_Warnblinker 0;
BA_ "GenSigSendType" SG_ 1171 MF_Warnblinker 3;
BA_ "GenSigSwitchedByIgnition" SG_ 1171 MF_Fussraumbel 0;
BA_ "GenSigSendType" SG_ 1171 MF_Fussraumbel 3;
BA_ "GenSigSwitchedByIgnition" SG_ 1171 MF_Innenraumbel 0;
BA_ "GenSigSendType" SG_ 1171 MF_Innenraumbel 3;
BA_ "GenSigSwitchedByIgnition" SG_ 1171 MF_Innenraumbel_Unterdrueck 0;
BA_ "GenSigSendType" SG_ 1171 MF_Innenraumbel_Unterdrueck 3;
BA_ "GenSigSwitchedByIgnition" SG_ 1171 MF_Notstart 0;
BA_ "GenSigSendType" SG_ 1171 MF_Notstart 3;
BA_ "GenSigSwitchedByIgnition" SG_ 1171 MF_Blk_li 0;
BA_ "GenSigSendType" SG_ 1171 MF_Blk_li 3;
BA_ "GenSigSwitchedByIgnition" SG_ 1171 MF_Blk_re 0;
BA_ "GenSigSendType" SG_ 1171 MF_Blk_re 3;
BA_ "GenSigSwitchedByIgnition" SG_ 1171 MF_Lichthupe 0;
BA_ "GenSigSendType" SG_ 1171 MF_Lichthupe 3;
BA_ "GenSigSwitchedByIgnition" SG_ 1171 MF_Fernlicht 0;
BA_ "GenSigSendType" SG_ 1171 MF_Fernlicht 3;
BA_ "GenSigSwitchedByIgnition" SG_ 1171 MF_HFS_verriegeln 0;
BA_ "GenSigSendType" SG_ 1171 MF_HFS_verriegeln 3;
BA_ "GenSigSwitchedByIgnition" SG_ 1171 MF_HFS_entriegeln 0;
BA_ "GenSigSendType" SG_ 1171 MF_HFS_entriegeln 3;
BA_ "GenSigSwitchedByIgnition" SG_ 1171 MF_HBFS_verriegeln 0;
BA_ "GenSigSendType" SG_ 1171 MF_HBFS_verriegeln 3;
BA_ "GenSigSwitchedByIgnition" SG_ 1171 MF_HBFS_entriegeln 0;
BA_ "GenSigSendType" SG_ 1171 MF_HBFS_entriegeln 3;
BA_ "GenSigSwitchedByIgnition" SG_ 1171 MF_Tippwischen 0;
BA_ "GenSigSendType" SG_ 1171 MF_Tippwischen 3;
BA_ "GenSigSwitchedByIgnition" SG_ 1171 MF_Frontintervall 0;
BA_ "GenSigSendType" SG_ 1171 MF_Frontintervall 3;
BA_ "GenSigSwitchedByIgnition" SG_ 1171 MF_Wischerstufe_1 0;
BA_ "GenSigSendType" SG_ 1171 MF_Wischerstufe_1 3;
BA_ "GenSigSwitchedByIgnition" SG_ 1171 MF_Wischerstufe_2 0;
BA_ "GenSigSendType" SG_ 1171 MF_Wischerstufe_2 3;
BA_ "GenSigSwitchedByIgnition" SG_ 1171 MF_Frontwaschen 0;
BA_ "GenSigSendType" SG_ 1171 MF_Frontwaschen 3;
BA_ "GenSigSwitchedByIgnition" SG_ 1171 MF_Heckintervall 0;
BA_ "GenSigSendType" SG_ 1171 MF_Heckintervall 3;
BA_ "GenSigSwitchedByIgnition" SG_ 1171 MF_Heckwaschen 0;
BA_ "GenSigSendType" SG_ 1171 MF_Heckwaschen 3;
BA_ "GenSigSwitchedByIgnition" SG_ 1171 MF_Summer 0;
BA_ "GenSigSendType" SG_ 1171 MF_Summer 3;
BA_ "GenSigSwitchedByIgnition" SG_ 1171 MF_Alarm_Blinkertakt 0;
BA_ "GenSigSendType" SG_ 1171 MF_Alarm_Blinkertakt 3;
BA_ "GenSigSwitchedByIgnition" SG_ 1171 MF_Alarm_Blinker 0;
BA_ "GenSigSendType" SG_ 1171 MF_Alarm_Blinker 3;
BA_ "GenSigSwitchedByIgnition" SG_ 1171 MF_TFL_Abschaltung 0;
BA_ "GenSigSendType" SG_ 1171 MF_TFL_Abschaltung 3;
BA_ "GenSigSwitchedByIgnition" SG_ 1171 MF_interm_Takt 0;
BA_ "GenSigSendType" SG_ 1171 MF_interm_Takt 3;
BA_ "GenSigSwitchedByIgnition" SG_ 1171 MF_Tuerentriegelung_hinten 0;
BA_ "GenSigSendType" SG_ 1171 MF_Tuerentriegelung_hinten 3;
BA_ "GenSigSwitchedByIgnition" SG_ 1171 MF_interm_Fahrlicht 0;
BA_ "GenSigSendType" SG_ 1171 MF_interm_Fahrlicht 3;
BA_ "GenSigSwitchedByIgnition" SG_ 1171 MF_Signalhorn 0;
BA_ "GenSigSendType" SG_ 1171 MF_Signalhorn 3;
BA_ "GenSigSwitchedByIgnition" SG_ 1171 MF_FH_FT_hoch 0;
BA_ "GenSigSendType" SG_ 1171 MF_FH_FT_hoch 3;
BA_ "GenSigSwitchedByIgnition" SG_ 1171 MF_FH_FT_tief 0;
BA_ "GenSigSendType" SG_ 1171 MF_FH_FT_tief 3;
BA_ "GenSigSwitchedByIgnition" SG_ 1171 MF_FH_BT_hoch 0;
BA_ "GenSigSendType" SG_ 1171 MF_FH_BT_hoch 3;
BA_ "GenSigSwitchedByIgnition" SG_ 1171 MF_FH_BT_tief 0;
BA_ "GenSigSendType" SG_ 1171 MF_FH_BT_tief 3;
BA_ "GenSigSwitchedByIgnition" SG_ 1171 MF_FT_verriegeln 0;
BA_ "GenSigSendType" SG_ 1171 MF_FT_verriegeln 3;
BA_ "GenSigSwitchedByIgnition" SG_ 1171 MF_FT_entriegeln 0;
BA_ "GenSigSendType" SG_ 1171 MF_FT_entriegeln 3;
BA_ "GenSigSwitchedByIgnition" SG_ 1171 MF_BT_verriegeln 0;
BA_ "GenSigSendType" SG_ 1171 MF_BT_verriegeln 3;
BA_ "GenSigSwitchedByIgnition" SG_ 1171 MF_BT_entriegeln 0;
BA_ "GenSigSendType" SG_ 1171 MF_BT_entriegeln 3;
BA_ "GenSigSwitchedByIgnition" SG_ 817 MFL_Zaehler 0;
BA_ "GenSigSendType" SG_ 817 MFL_Zaehler 0;
BA_ "GenSigSwitchedByIgnition" SG_ 817 MFL_Toggle 0;
BA_ "GenSigSendType" SG_ 817 MFL_Toggle 0;
BA_ "GenSigSwitchedByIgnition" SG_ 817 MFL_Lokalaktiv 0;
BA_ "GenSigSendType" SG_ 817 MFL_Lokalaktiv 0;
BA_ "GenSigSendType" SG_ 817 MFL_M_Taste 0;
BA_ "GenSigSwitchedByIgnition" SG_ 817 MFL_Tastencode_1 0;
BA_ "GenSigSendType" SG_ 817 MFL_Tastencode_1 0;
BA_ "GenSigSwitchedByIgnition" SG_ 817 MFL_Tastencode_2 0;
BA_ "GenSigSendType" SG_ 817 MFL_Tastencode_2 0;
BA_ "GenSigSwitchedByIgnition" SG_ 817 MFL_Eventcode_1 0;
BA_ "GenSigSendType" SG_ 817 MFL_Eventcode_1 0;
BA_ "GenSigSwitchedByIgnition" SG_ 817 MFL_Eventcode_2 0;
BA_ "GenSigSendType" SG_ 817 MFL_Eventcode_2 0;
BA_ "GenSigSwitchedByIgnition" SG_ 817 MFL_Marke 0;
BA_ "GenSigFuncType" SG_ 817 MFL_Marke 8;
BA_ "GenSigSendType" SG_ 817 MFL_Marke 0;
BA_ "GenSigSwitchedByIgnition" SG_ 817 MFL_Variante 0;
BA_ "GenSigFuncType" SG_ 817 MFL_Variante 8;
BA_ "GenSigSendType" SG_ 817 MFL_Variante 0;
BA_ "GenSigSwitchedByIgnition" SG_ 817 MFL_Dummy_0_Signal_1 0;
BA_ "GenSigSendType" SG_ 817 MFL_Dummy_0_Signal_1 0;
BA_ "GenSigSendType" SG_ 817 MFL_Tip_Down 0;
BA_ "GenSigSendType" SG_ 817 MFL_Tip_Up 0;
BA_ "Fehlerwert" SG_ 817 MFL_SatModul_links_Err 1;
BA_ "GenSigSwitchedByIgnition" SG_ 817 MFL_SatModul_links_Err 0;
BA_ "GenSigFuncType" SG_ 817 MFL_SatModul_links_Err 5;
BA_ "GenSigSendType" SG_ 817 MFL_SatModul_links_Err 0;
BA_ "Fehlerwert" SG_ 817 MFL_SatModul_rechts_Err 1;
BA_ "GenSigSwitchedByIgnition" SG_ 817 MFL_SatModul_rechts_Err 0;
BA_ "GenSigFuncType" SG_ 817 MFL_SatModul_rechts_Err 5;
BA_ "GenSigSendType" SG_ 817 MFL_SatModul_rechts_Err 0;
BA_ "GenSigSwitchedByIgnition" SG_ 817 MFL_Dummy_0_Signal_2 0;
BA_ "GenSigSendType" SG_ 817 MFL_Dummy_0_Signal_2 0;
BA_ "GenSigSwitchedByIgnition" SG_ 817 MFL_Dummy_0_Signal_3 0;
BA_ "GenSigSendType" SG_ 817 MFL_Dummy_0_Signal_3 0;
BA_ "GenSigSwitchedByIgnition" SG_ 817 MFL_LR_HZG_Status 0;
BA_ "GenSigSendType" SG_ 817 MFL_LR_HZG_Status 0;
BA_ "Fehlerwert" SG_ 817 MFL_LR_HZG_Err 1;
BA_ "GenSigSwitchedByIgnition" SG_ 817 MFL_LR_HZG_Err 0;
BA_ "GenSigSendType" SG_ 817 MFL_LR_HZG_Err 0;
BA_ "GenSigSwitchedByIgnition" SG_ 817 MFL_Signalhorn 0;
BA_ "GenSigSendType" SG_ 817 MFL_Signalhorn 5;
BA_ "Fehlerwert" SG_ 817 MFL_Signalhorn_Err 1;
BA_ "GenSigSwitchedByIgnition" SG_ 817 MFL_Signalhorn_Err 0;
BA_ "GenSigSendType" SG_ 817 MFL_Signalhorn_Err 0;
BA_ "Fehlerwert" SG_ 817 MFL_Tip_links_Err 1;
BA_ "GenSigSwitchedByIgnition" SG_ 817 MFL_Tip_links_Err 0;
BA_ "GenSigSendType" SG_ 817 MFL_Tip_links_Err 0;
BA_ "Fehlerwert" SG_ 817 MFL_Tip_rechts_Err 1;
BA_ "GenSigSwitchedByIgnition" SG_ 817 MFL_Tip_rechts_Err 0;
BA_ "GenSigSendType" SG_ 817 MFL_Tip_rechts_Err 0;
BA_ "Fehlerwert" SG_ 817 MFL_Taste_links_Err 1;
BA_ "GenSigSwitchedByIgnition" SG_ 817 MFL_Taste_links_Err 0;
BA_ "GenSigSendType" SG_ 817 MFL_Taste_links_Err 0;
BA_ "Fehlerwert" SG_ 817 MFL_Taste_rechts_Err 1;
BA_ "GenSigSwitchedByIgnition" SG_ 817 MFL_Taste_rechts_Err 0;
BA_ "GenSigSendType" SG_ 817 MFL_Taste_rechts_Err 0;
BA_ "Fehlerwert" SG_ 817 MFL_ECU_Err 1;
BA_ "GenSigSwitchedByIgnition" SG_ 817 MFL_ECU_Err 0;
BA_ "GenSigSendType" SG_ 817 MFL_ECU_Err 0;
BA_ "Fehlerwert" SG_ 817 MFL_Response_Err 1;
BA_ "GenSigSwitchedByIgnition" SG_ 817 MFL_Response_Err 0;
BA_ "GenSigSendType" SG_ 817 MFL_Response_Err 0;
BA_ "GenSigSwitchedByIgnition" SG_ 349 MO2_Freigabe_Info_WFS 0;
BA_ "GenSigSendType" SG_ 349 MO2_Freigabe_Info_WFS 3;
BA_ "GenSigSwitchedByIgnition" SG_ 349 MO2_Sperr_Info_WFS 0;
BA_ "GenSigSendType" SG_ 349 MO2_Sperr_Info_WFS 3;
BA_ "GenSigSwitchedByIgnition" SG_ 349 MO2_Freigabe_Verfallsinfo_WFS 0;
BA_ "GenSigSendType" SG_ 349 MO2_Freigabe_Verfallsinfo_WFS 3;
BA_ "GenSigSwitchedByIgnition" SG_ 1600 MO_QBit_Ansaugluft_Temp 0;
BA_ "GenSigStartValue" SG_ 1600 MO_QBit_Ansaugluft_Temp 1;
BA_ "GenSigSendType" SG_ 1600 MO_QBit_Ansaugluft_Temp 0;
BA_ "GenSigSwitchedByIgnition" SG_ 1600 MO_QBit_Oel_Temp 0;
BA_ "GenSigStartValue" SG_ 1600 MO_QBit_Oel_Temp 1;
BA_ "GenSigSendType" SG_ 1600 MO_QBit_Oel_Temp 0;
BA_ "GenSigSwitchedByIgnition" SG_ 1600 MO_QBit_Kuehlmittel_Temp 0;
BA_ "GenSigStartValue" SG_ 1600 MO_QBit_Kuehlmittel_Temp 1;
BA_ "GenSigSendType" SG_ 1600 MO_QBit_Kuehlmittel_Temp 0;
BA_ "GenSigSwitchedByIgnition" SG_ 1600 MO_KL15_Abschaltempfehlung 0;
BA_ "GenSigSendType" SG_ 1600 MO_KL15_Abschaltempfehlung 0;
BA_ "GenSigSwitchedByIgnition" SG_ 1600 MO_HYB_Fehler_HV_Netz 0;
BA_ "GenSigSendType" SG_ 1600 MO_HYB_Fehler_HV_Netz 0;
BA_ "GenSigSwitchedByIgnition" SG_ 1600 MO_aktives_Getriebeheizen 0;
BA_ "GenSigSendType" SG_ 1600 MO_aktives_Getriebeheizen 0;
BA_ "GenSigSwitchedByIgnition" SG_ 1600 MO_Absperrventil_oeffnen 0;
BA_ "GenSigSendType" SG_ 1600 MO_Absperrventil_oeffnen 0;
BA_ "Fehlerwert" SG_ 1600 MO_Ansaugluft_Temp 255;
BA_ "GenSigSwitchedByIgnition" SG_ 1600 MO_Ansaugluft_Temp 0;
BA_ "GenSigStartValue" SG_ 1600 MO_Ansaugluft_Temp 254;
BA_ "GenSigSendType" SG_ 1600 MO_Ansaugluft_Temp 0;
BA_ "Fehlerwert" SG_ 1600 MO_Oel_Temp 255;
BA_ "GenSigSwitchedByIgnition" SG_ 1600 MO_Oel_Temp 0;
BA_ "GenSigStartValue" SG_ 1600 MO_Oel_Temp 254;
BA_ "GenSigSendType" SG_ 1600 MO_Oel_Temp 0;
BA_ "Fehlerwert" SG_ 1600 MO_Kuehlmittel_Temp 255;
BA_ "GenSigSwitchedByIgnition" SG_ 1600 MO_Kuehlmittel_Temp 0;
BA_ "GenSigStartValue" SG_ 1600 MO_Kuehlmittel_Temp 254;
BA_ "GenSigSendType" SG_ 1600 MO_Kuehlmittel_Temp 0;
BA_ "Fehlerwert" SG_ 1600 MO_Hoeheninfo 255;
BA_ "GenSigSwitchedByIgnition" SG_ 1600 MO_Hoeheninfo 0;
BA_ "GenSigSendType" SG_ 1600 MO_Hoeheninfo 0;
BA_ "GenSigSwitchedByIgnition" SG_ 1600 MO_Kennfeldk 0;
BA_ "GenSigSendType" SG_ 1600 MO_Kennfeldk 0;
BA_ "GenSigSwitchedByIgnition" SG_ 1600 MO_Versionsinfo_02 0;
BA_ "GenSigFuncType" SG_ 1600 MO_Versionsinfo_02 8;
BA_ "GenSigSendType" SG_ 1600 MO_Versionsinfo_02 0;
BA_ "GenSigSwitchedByIgnition" SG_ 1600 MO_QBit_Hoeheninfo 0;
BA_ "GenSigStartValue" SG_ 1600 MO_QBit_Hoeheninfo 1;
BA_ "GenSigSendType" SG_ 1600 MO_QBit_Hoeheninfo 0;
BA_ "GenSigSwitchedByIgnition" SG_ 1600 MO_Getriebe_kuehlen 0;
BA_ "GenSigSendType" SG_ 1600 MO_Getriebe_kuehlen 0;
BA_ "GenSigSwitchedByIgnition" SG_ 1600 MO_Mom_Traegheit_02 0;
BA_ "GenSigSendType" SG_ 1600 MO_Mom_Traegheit_02 0;
BA_ "Fehlerwert" SG_ 1600 MO_Heizungspumpenansteuerung 13;
BA_ "GenSigSwitchedByIgnition" SG_ 1600 MO_Heizungspumpenansteuerung 0;
BA_ "GenSigStartValue" SG_ 1600 MO_Heizungspumpenansteuerung 14;
BA_ "GenSigSendType" SG_ 1600 MO_Heizungspumpenansteuerung 0;
BA_ "GenSigSwitchedByIgnition" SG_ 1600 MO_SpannungsAnf 0;
BA_ "GenSigSendType" SG_ 1600 MO_SpannungsAnf 0;
BA_ "GenSigSwitchedByIgnition" SG_ 1600 MO_Nachlaufzeit_Heizungspumpe 0;
BA_ "GenSigSendType" SG_ 1600 MO_Nachlaufzeit_Heizungspumpe 0;
BA_ "Fehlerwert" SG_ 1607 MO_ITM_Kuehlmittel_Temp 2;
BA_ "GenSigSwitchedByIgnition" SG_ 1607 MO_ITM_Kuehlmittel_Temp 0;
BA_ "GenSigStartValue" SG_ 1607 MO_ITM_Kuehlmittel_Temp 1;
BA_ "GenSigSendType" SG_ 1607 MO_ITM_Kuehlmittel_Temp 0;
BA_ "Fehlerwert" SG_ 1607 MO_E85_Sensor 15;
BA_ "GenSigSwitchedByIgnition" SG_ 1607 MO_E85_Sensor 0;
BA_ "GenSigStartValue" SG_ 1607 MO_E85_Sensor 14;
BA_ "GenSigSendType" SG_ 1607 MO_E85_Sensor 0;
BA_ "GenSigSwitchedByIgnition" SG_ 1607 SCR_Anz_Motorstarts 0;
BA_ "GenSigStartValue" SG_ 1607 SCR_Anz_Motorstarts 15;
BA_ "GenSigSendType" SG_ 1607 SCR_Anz_Motorstarts 0;
BA_ "GenSigSwitchedByIgnition" SG_ 1607 SCR_Reichweite 0;
BA_ "GenSigStartValue" SG_ 1607 SCR_Reichweite 32767;
BA_ "GenSigSendType" SG_ 1607 SCR_Reichweite 0;
BA_ "GenSigSwitchedByIgnition" SG_ 1607 MO_Ethanol_Spuelhinweis 0;
BA_ "GenSigSendType" SG_ 1607 MO_Ethanol_Spuelhinweis 0;
BA_ "GenSigSwitchedByIgnition" SG_ 1607 SCR_Warnstufe_1 0;
BA_ "GenSigSendType" SG_ 1607 SCR_Warnstufe_1 0;
BA_ "GenSigSwitchedByIgnition" SG_ 1607 SCR_Warnstufe_2 0;
BA_ "GenSigSendType" SG_ 1607 SCR_Warnstufe_2 0;
BA_ "GenSigSwitchedByIgnition" SG_ 1607 SCR_Text 0;
BA_ "GenSigSendType" SG_ 1607 SCR_Text 0;
BA_ "GenSigSwitchedByIgnition" SG_ 1607 SCR_Akustik 0;
BA_ "GenSigSendType" SG_ 1607 SCR_Akustik 0;
BA_ "GenSigSwitchedByIgnition" SG_ 1607 SCR_verbaut 0;
BA_ "GenSigFuncType" SG_ 1607 SCR_verbaut 8;
BA_ "GenSigSendType" SG_ 1607 SCR_verbaut 0;
BA_ "GenSigSwitchedByIgnition" SG_ 1607 MO_Kraftstofffilter_Wasser 0;
BA_ "GenSigSendType" SG_ 1607 MO_Kraftstofffilter_Wasser 0;
BA_ "GenSigSwitchedByIgnition" SG_ 1607 SCR_Systemfehler 0;
BA_ "GenSigSendType" SG_ 1607 SCR_Systemfehler 0;
BA_ "GenSigSwitchedByIgnition" SG_ 1607 SCR_Inducement_Strategie 0;
BA_ "GenSigSendType" SG_ 1607 SCR_Inducement_Strategie 0;
BA_ "Fehlerwert" SG_ 1607 MO_CO2_Faktor 4095;
BA_ "GenSigSwitchedByIgnition" SG_ 1607 MO_CO2_Faktor 0;
BA_ "GenSigSendType" SG_ 1607 MO_CO2_Faktor 0;
BA_ "GenSigSwitchedByIgnition" SG_ 1607 MO_MKB_MUX 0;
BA_ "GenSigSendType" SG_ 1607 MO_MKB_MUX 0;
BA_ "GenSigSwitchedByIgnition" SG_ 1607 MO_MKB_01 0;
BA_ "GenSigFuncType" SG_ 1607 MO_MKB_01 8;
BA_ "GenSigSwitchedByIgnition" SG_ 1607 MO_MKB_02 0;
BA_ "GenSigFuncType" SG_ 1607 MO_MKB_02 8;
BA_ "GenSigSwitchedByIgnition" SG_ 1607 MO_MKB_03 0;
BA_ "GenSigFuncType" SG_ 1607 MO_MKB_03 8;
BA_ "GenSigSwitchedByIgnition" SG_ 1607 MO_MKB_04 0;
BA_ "GenSigFuncType" SG_ 1607 MO_MKB_04 8;
BA_ "GenSigSwitchedByIgnition" SG_ 168 Motor_12_CRC 0;
BA_ "GenSigFuncType" SG_ 168 Motor_12_CRC 2;
BA_ "GenSigSendType" SG_ 168 Motor_12_CRC 0;
BA_ "GenSigSwitchedByIgnition" SG_ 168 Motor_12_BZ 0;
BA_ "GenSigFuncType" SG_ 168 Motor_12_BZ 1;
BA_ "GenSigSendType" SG_ 168 Motor_12_BZ 0;
BA_ "Fehlerwert" SG_ 168 MO_Mom_neg_verfuegbar 511;
BA_ "GenSigSwitchedByIgnition" SG_ 168 MO_Mom_neg_verfuegbar 0;
BA_ "GenSigStartValue" SG_ 168 MO_Mom_neg_verfuegbar 510;
BA_ "GenSigSendType" SG_ 168 MO_Mom_neg_verfuegbar 0;
BA_ "GenSigSwitchedByIgnition" SG_ 168 MO_Mom_Begr_stat 0;
BA_ "GenSigStartValue" SG_ 168 MO_Mom_Begr_stat 510;
BA_ "GenSigSendType" SG_ 168 MO_Mom_Begr_stat 0;
BA_ "GenSigSwitchedByIgnition" SG_ 168 MO_Mom_Begr_dyn 0;
BA_ "GenSigStartValue" SG_ 168 MO_Mom_Begr_dyn 1022;
BA_ "GenSigSendType" SG_ 168 MO_Mom_Begr_dyn 0;
BA_ "GenSigSwitchedByIgnition" SG_ 168 MO_Momentenintegral_02 0;
BA_ "GenSigSendType" SG_ 168 MO_Momentenintegral_02 0;
BA_ "GenSigSwitchedByIgnition" SG_ 168 MO_QBit_Drehzahl_01 0;
BA_ "GenSigStartValue" SG_ 168 MO_QBit_Drehzahl_01 1;
BA_ "GenSigSendType" SG_ 168 MO_QBit_Drehzahl_01 0;
BA_ "GenSigSwitchedByIgnition" SG_ 168 MO_Drehzahl_01 0;
BA_ "GenSigSendType" SG_ 168 MO_Drehzahl_01 0;
BA_ "GenSigSwitchedByIgnition" SG_ 958 Motor_14_CRC 0;
BA_ "GenSigFuncType" SG_ 958 Motor_14_CRC 2;
BA_ "GenSigSendType" SG_ 958 Motor_14_CRC 0;
BA_ "GenSigSwitchedByIgnition" SG_ 958 Motor_14_BZ 0;
BA_ "GenSigFuncType" SG_ 958 Motor_14_BZ 1;
BA_ "GenSigSendType" SG_ 958 Motor_14_BZ 0;
BA_ "GenSigSwitchedByIgnition" SG_ 958 MO_StartStopp_Status 0;
BA_ "GenSigSendType" SG_ 958 MO_StartStopp_Status 3;
BA_ "GenSigSwitchedByIgnition" SG_ 958 MO_StartStopp_Wiederstart 0;
BA_ "GenSigSendType" SG_ 958 MO_StartStopp_Wiederstart 3;
BA_ "GenSigSwitchedByIgnition" SG_ 958 MO_StartStopp_Motorstopp 0;
BA_ "GenSigSendType" SG_ 958 MO_StartStopp_Motorstopp 3;
BA_ "GenSigSwitchedByIgnition" SG_ 958 MO_Freig_Reku 0;
BA_ "GenSigSendType" SG_ 958 MO_Freig_Reku 0;
BA_ "GenSigSwitchedByIgnition" SG_ 958 MO_Kl_75 0;
BA_ "GenSigSendType" SG_ 958 MO_Kl_75 3;
BA_ "GenSigSwitchedByIgnition" SG_ 958 MO_Kl_50 0;
BA_ "GenSigSendType" SG_ 958 MO_Kl_50 3;
BA_ "Fehlerwert" SG_ 958 MO_Gangposition 15;
BA_ "GenSigSwitchedByIgnition" SG_ 958 MO_Gangposition 0;
BA_ "GenSigStartValue" SG_ 958 MO_Gangposition 14;
BA_ "GenSigSendType" SG_ 958 MO_Gangposition 3;
BA_ "GenSigSwitchedByIgnition" SG_ 958 MO_StartStopp_Fahrerwunsch 0;
BA_ "GenSigSendType" SG_ 958 MO_StartStopp_Fahrerwunsch 0;
BA_ "GenSigSwitchedByIgnition" SG_ 958 MO_HYB_Fahrbereitschaft 0;
BA_ "GenSigSendType" SG_ 958 MO_HYB_Fahrbereitschaft 0;
BA_ "GenSigSwitchedByIgnition" SG_ 958 MO_Ext_E_Fahrt_aktiv 0;
BA_ "NWM-WakeupAllowed" SG_ 958 MO_Ext_E_Fahrt_aktiv 1;
BA_ "GenSigSendType" SG_ 958 MO_Ext_E_Fahrt_aktiv 3;
BA_ "GenSigSwitchedByIgnition" SG_ 958 MO_Fahrer_bremst 0;
BA_ "GenSigSendType" SG_ 958 MO_Fahrer_bremst 3;
BA_ "GenSigSwitchedByIgnition" SG_ 958 MO_QBit_Fahrer_bremst 0;
BA_ "GenSigStartValue" SG_ 958 MO_QBit_Fahrer_bremst 1;
BA_ "GenSigSendType" SG_ 958 MO_QBit_Fahrer_bremst 3;
BA_ "GenSigSwitchedByIgnition" SG_ 958 MO_BLS 0;
BA_ "GenSigSendType" SG_ 958 MO_BLS 3;
BA_ "GenSigSwitchedByIgnition" SG_ 958 MO_Konsistenz_Bremsped 0;
BA_ "GenSigSendType" SG_ 958 MO_Konsistenz_Bremsped 3;
BA_ "Fehlerwert" SG_ 958 MO_KomFehler_ESP 1;
BA_ "GenSigSwitchedByIgnition" SG_ 958 MO_KomFehler_ESP 0;
BA_ "GenSigSendType" SG_ 958 MO_KomFehler_ESP 3;
BA_ "GenSigSwitchedByIgnition" SG_ 958 MO_Klima_Eingr 0;
BA_ "GenSigSendType" SG_ 958 MO_Klima_Eingr 0;
BA_ "GenSigSwitchedByIgnition" SG_ 958 MO_Aussp_Anlass 0;
BA_ "GenSigSendType" SG_ 958 MO_Aussp_Anlass 3;
BA_ "GenSigSwitchedByIgnition" SG_ 958 MO_Freig_Anlass 0;
BA_ "GenSigSendType" SG_ 958 MO_Freig_Anlass 3;
BA_ "GenSigSwitchedByIgnition" SG_ 958 MO_Kuppl_schalter 0;
BA_ "GenSigSendType" SG_ 958 MO_Kuppl_schalter 3;
BA_ "GenSigSwitchedByIgnition" SG_ 958 MO_Interlock 0;
BA_ "GenSigSendType" SG_ 958 MO_Interlock 3;
BA_ "GenSigSwitchedByIgnition" SG_ 958 MO_Motor_laeuft 0;
BA_ "GenSigSendType" SG_ 958 MO_Motor_laeuft 3;
BA_ "GenSigSwitchedByIgnition" SG_ 958 MO_Kickdown 0;
BA_ "GenSigSendType" SG_ 958 MO_Kickdown 3;
BA_ "GenSigSwitchedByIgnition" SG_ 958 MO_QBit_KL_75 0;
BA_ "GenSigStartValue" SG_ 958 MO_QBit_KL_75 1;
BA_ "GenSigSendType" SG_ 958 MO_QBit_KL_75 3;
BA_ "GenSigSwitchedByIgnition" SG_ 958 MO_EKlKomLeiRed 0;
BA_ "GenSigSendType" SG_ 958 MO_EKlKomLeiRed 0;
BA_ "GenSigSwitchedByIgnition" SG_ 958 MO_Handshake_STH 0;
BA_ "GenSigSendType" SG_ 958 MO_Handshake_STH 0;
BA_ "GenSigSwitchedByIgnition" SG_ 958 MO_BKV_Unterdruckwarnung 0;
BA_ "GenSigSendType" SG_ 958 MO_BKV_Unterdruckwarnung 0;
BA_ "GenSigSwitchedByIgnition" SG_ 958 MO_Freigabe_Segeln 0;
BA_ "GenSigSendType" SG_ 958 MO_Freigabe_Segeln 0;
BA_ "GenSigSwitchedByIgnition" SG_ 958 MO_PTC_Status 0;
BA_ "GenSigSendType" SG_ 958 MO_PTC_Status 0;
BA_ "GenSigSwitchedByIgnition" SG_ 958 MO_QBit_Gangposition 0;
BA_ "GenSigStartValue" SG_ 958 MO_QBit_Gangposition 1;
BA_ "GenSigSendType" SG_ 958 MO_QBit_Gangposition 3;
BA_ "GenSigSwitchedByIgnition" SG_ 958 MO_Signalquelle_Gangposition 0;
BA_ "GenSigSendType" SG_ 958 MO_Signalquelle_Gangposition 0;
BA_ "GenSigSwitchedByIgnition" SG_ 958 MO_Remotestart_Betrieb 0;
BA_ "GenSigSendType" SG_ 958 MO_Remotestart_Betrieb 3;
BA_ "GenSigSwitchedByIgnition" SG_ 958 MO_Zylinderabschaltung 0;
BA_ "GenSigSendType" SG_ 958 MO_Zylinderabschaltung 3;
BA_ "GenSigSwitchedByIgnition" SG_ 958 MO_HYB_VM_aktiv 0;
BA_ "GenSigSendType" SG_ 958 MO_HYB_VM_aktiv 3;
BA_ "GenSigSwitchedByIgnition" SG_ 958 MO_StartVorauss_erfuellt 0;
BA_ "GenSigStartValue" SG_ 958 MO_StartVorauss_erfuellt 1;
BA_ "GenSigSendType" SG_ 958 MO_StartVorauss_erfuellt 3;
BA_ "GenSigSwitchedByIgnition" SG_ 1648 MO_max_Ladedruck 0;
BA_ "GenSigFuncType" SG_ 1648 MO_max_Ladedruck 8;
BA_ "GenSigSendType" SG_ 1648 MO_max_Ladedruck 0;
BA_ "GenSigSwitchedByIgnition" SG_ 1648 MO_ANC_Kennfeld_Anf 0;
BA_ "GenSigSendType" SG_ 1648 MO_ANC_Kennfeld_Anf 3;
BA_ "GenSigSwitchedByIgnition" SG_ 1648 MO_Bremslicht_Reku 0;
BA_ "GenSigSendType" SG_ 1648 MO_Bremslicht_Reku 3;
BA_ "GenSigSwitchedByIgnition" SG_ 1648 MO_StartStopp_PopUp 0;
BA_ "GenSigSendType" SG_ 1648 MO_StartStopp_PopUp 3;
BA_ "GenSigSwitchedByIgnition" SG_ 1648 MO1_Sperr_Info_WFS 0;
BA_ "GenSigSendType" SG_ 1648 MO1_Sperr_Info_WFS 3;
BA_ "GenSigSwitchedByIgnition" SG_ 1648 MO1_Freigabe_Info_WFS 0;
BA_ "GenSigSendType" SG_ 1648 MO1_Freigabe_Info_WFS 3;
BA_ "GenSigSwitchedByIgnition" SG_ 1648 MO_EPCL 0;
BA_ "GenSigSendType" SG_ 1648 MO_EPCL 0;
BA_ "GenSigSwitchedByIgnition" SG_ 1648 MO_Zylabsch_Texte_02 0;
BA_ "GenSigSendType" SG_ 1648 MO_Zylabsch_Texte_02 3;
BA_ "GenSigSwitchedByIgnition" SG_ 1648 MO_Fahrzeugtyp 0;
BA_ "GenSigFuncType" SG_ 1648 MO_Fahrzeugtyp 8;
BA_ "GenSigSendType" SG_ 1648 MO_Fahrzeugtyp 0;
BA_ "GenSigSwitchedByIgnition" SG_ 1648 MO_NMAX_Schaltanzeige 0;
BA_ "GenSigSendType" SG_ 1648 MO_NMAX_Schaltanzeige 3;
BA_ "GenSigSwitchedByIgnition" SG_ 1648 MO_Abstellzeit 0;
BA_ "GenSigSendType" SG_ 1648 MO_Abstellzeit 0;
BA_ "GenSigSwitchedByIgnition" SG_ 1648 MO_Abstellzeit_Status 0;
BA_ "GenSigSendType" SG_ 1648 MO_Abstellzeit_Status 0;
BA_ "GenSigSwitchedByIgnition" SG_ 1648 MO1_Freigabe_Verfallsinfo_WFS 0;
BA_ "GenSigSendType" SG_ 1648 MO1_Freigabe_Verfallsinfo_WFS 3;
BA_ "GenSigSwitchedByIgnition" SG_ 1648 MO_Hybrid_StartStopp_LED 0;
BA_ "GenSigSendType" SG_ 1648 MO_Hybrid_StartStopp_LED 3;
BA_ "GenSigSwitchedByIgnition" SG_ 1648 MO_Fehler_Zylabsch 0;
BA_ "GenSigSendType" SG_ 1648 MO_Fehler_Zylabsch 0;
BA_ "GenSigSwitchedByIgnition" SG_ 1648 MO_Anzahl_Abgesch_Zyl 0;
BA_ "GenSigSendType" SG_ 1648 MO_Anzahl_Abgesch_Zyl 3;
BA_ "GenSigSwitchedByIgnition" SG_ 1648 MO_Zylabsch_Texte 0;
BA_ "GenSigSendType" SG_ 1648 MO_Zylabsch_Texte 0;
BA_ "GenSigSwitchedByIgnition" SG_ 1648 MO_Ethanol_BS_Texte 0;
BA_ "GenSigSendType" SG_ 1648 MO_Ethanol_BS_Texte 0;
BA_ "GenSigSwitchedByIgnition" SG_ 1648 MO_Drehzahl_Warnung 0;
BA_ "GenSigSendType" SG_ 1648 MO_Drehzahl_Warnung 0;
BA_ "GenSigSwitchedByIgnition" SG_ 1648 MO_obere_Drehzahlgrenze 0;
BA_ "GenSigSendType" SG_ 1648 MO_obere_Drehzahlgrenze 0;
BA_ "GenSigSwitchedByIgnition" SG_ 289 Motor_20_CRC 0;
BA_ "GenSigFuncType" SG_ 289 Motor_20_CRC 2;
BA_ "GenSigSendType" SG_ 289 Motor_20_CRC 0;
BA_ "GenSigSwitchedByIgnition" SG_ 289 Motor_20_BZ 0;
BA_ "GenSigFuncType" SG_ 289 Motor_20_BZ 1;
BA_ "GenSigSendType" SG_ 289 Motor_20_BZ 0;
BA_ "Fehlerwert" SG_ 289 MO_Fahrpedalrohwert_01 255;
BA_ "GenSigSwitchedByIgnition" SG_ 289 MO_Fahrpedalrohwert_01 0;
BA_ "GenSigSendType" SG_ 289 MO_Fahrpedalrohwert_01 0;
BA_ "GenSigSwitchedByIgnition" SG_ 289 MO_QBit_Fahrpedalwerte_01 0;
BA_ "GenSigStartValue" SG_ 289 MO_QBit_Fahrpedalwerte_01 1;
BA_ "GenSigSendType" SG_ 289 MO_QBit_Fahrpedalwerte_01 0;
BA_ "Fehlerwert" SG_ 289 MO_Fahrpedalgradient 255;
BA_ "GenSigSwitchedByIgnition" SG_ 289 MO_Fahrpedalgradient 0;
BA_ "GenSigSendType" SG_ 289 MO_Fahrpedalgradient 0;
BA_ "GenSigSwitchedByIgnition" SG_ 289 MO_Sig_Fahrpedalgradient 0;
BA_ "GenSigSendType" SG_ 289 MO_Sig_Fahrpedalgradient 0;
BA_ "Fehlerwert" SG_ 289 MO_rel_Saugrohrdruck 63;
BA_ "GenSigSwitchedByIgnition" SG_ 289 MO_rel_Saugrohrdruck 0;
BA_ "GenSigSendType" SG_ 289 MO_rel_Saugrohrdruck 0;
BA_ "GenSigSwitchedByIgnition" SG_ 289 MO_rel_Saugrohrdruck_gem_err 0;
BA_ "GenSigSendType" SG_ 289 MO_rel_Saugrohrdruck_gem_err 0;
BA_ "GenSigSwitchedByIgnition" SG_ 289 MO_Moment_im_Leerlauf 0;
BA_ "GenSigSendType" SG_ 289 MO_Moment_im_Leerlauf 0;
BA_ "GenSigSwitchedByIgnition" SG_ 289 MO_Schubabschaltung 0;
BA_ "GenSigSendType" SG_ 289 MO_Schubabschaltung 0;
BA_ "GenSigSwitchedByIgnition" SG_ 289 MO_StartStopp_StoppVorbereitung 0;
BA_ "GenSigSendType" SG_ 289 MO_StartStopp_StoppVorbereitung 0;
BA_ "GenSigSwitchedByIgnition" SG_ 289 MO_Solldrehz_Leerlauf 0;
BA_ "GenSigSendType" SG_ 289 MO_Solldrehz_Leerlauf 0;
BA_ "GenSigSwitchedByIgnition" SG_ 289 MO_Entkopplung_Sollschlupf 0;
BA_ "GenSigStartValue" SG_ 289 MO_Entkopplung_Sollschlupf 126;
BA_ "GenSigSendType" SG_ 289 MO_Entkopplung_Sollschlupf 0;
BA_ "GenSigSwitchedByIgnition" SG_ 289 MO_temporaere_Fahrerabwesenheit 0;
BA_ "GenSigSendType" SG_ 289 MO_temporaere_Fahrerabwesenheit 0;
BA_ "GenSigSwitchedByIgnition" SG_ 289 TSK_a_Soll_gradientenbegrenzt 0;
BA_ "GenSigStartValue" SG_ 289 TSK_a_Soll_gradientenbegrenzt 127;
BA_ "GenSigSendType" SG_ 289 TSK_a_Soll_gradientenbegrenzt 0;
BA_ "GenSigSwitchedByIgnition" SG_ 967 MO_Kuehlerluefter_MUX 0;
BA_ "GenSigSendType" SG_ 967 MO_Kuehlerluefter_MUX 0;
BA_ "Fehlerwert" SG_ 967 MO_Kuehlerluefter_1 127;
BA_ "GenSigSwitchedByIgnition" SG_ 967 MO_Kuehlerluefter_1 0;
BA_ "GenSigStartValue" SG_ 967 MO_Kuehlerluefter_1 126;
BA_ "Fehlerwert" SG_ 967 MO_Kuehlerluefter_2 127;
BA_ "GenSigSwitchedByIgnition" SG_ 967 MO_Kuehlerluefter_2 0;
BA_ "GenSigStartValue" SG_ 967 MO_Kuehlerluefter_2 126;
BA_ "GenSigSwitchedByIgnition" SG_ 967 MO_EFLEX_Lampe 0;
BA_ "GenSigSendType" SG_ 967 MO_EFLEX_Lampe 0;
BA_ "Fehlerwert" SG_ 967 MO_KJS_nicht_bereit 1;
BA_ "GenSigSwitchedByIgnition" SG_ 967 MO_KJS_nicht_bereit 0;
BA_ "GenSigSendType" SG_ 967 MO_KJS_nicht_bereit 0;
BA_ "GenSigSwitchedByIgnition" SG_ 967 MO_ITM_Warnung_Pumpe 0;
BA_ "GenSigSendType" SG_ 967 MO_ITM_Warnung_Pumpe 0;
BA_ "GenSigSwitchedByIgnition" SG_ 967 WIV_Anzeige_aktiv 0;
BA_ "GenSigSendType" SG_ 967 WIV_Anzeige_aktiv 0;
BA_ "GenSigSwitchedByIgnition" SG_ 967 WIV_Oelmin_Warn 0;
BA_ "GenSigSendType" SG_ 967 WIV_Oelmin_Warn 0;
BA_ "GenSigSwitchedByIgnition" SG_ 967 WIV_Sensorfehler 0;
BA_ "GenSigSendType" SG_ 967 WIV_Sensorfehler 0;
BA_ "GenSigSwitchedByIgnition" SG_ 967 WIV_Schieflage 0;
BA_ "GenSigSendType" SG_ 967 WIV_Schieflage 0;
BA_ "GenSigSwitchedByIgnition" SG_ 967 WIV_Oelstand 0;
BA_ "GenSigSendType" SG_ 967 WIV_Oelstand 0;
BA_ "GenSigSwitchedByIgnition" SG_ 967 MO_Zustand_HWP 0;
BA_ "GenSigStartValue" SG_ 967 MO_Zustand_HWP 1;
BA_ "GenSigSendType" SG_ 967 MO_Zustand_HWP 0;
BA_ "GenSigSwitchedByIgnition" SG_ 967 OLEV_Systemstoerung 0;
BA_ "GenSigSendType" SG_ 967 OLEV_Systemstoerung 0;
BA_ "GenSigSwitchedByIgnition" SG_ 967 MO_Oelwarnung_max 0;
BA_ "GenSigSendType" SG_ 967 MO_Oelwarnung_max 0;
BA_ "GenSigSwitchedByIgnition" SG_ 967 WIV_Oelsystem_aktiv 0;
BA_ "GenSigSendType" SG_ 967 WIV_Oelsystem_aktiv 0;
BA_ "GenSigSwitchedByIgnition" SG_ 967 WIV_nicht_betriebswarm 0;
BA_ "GenSigSendType" SG_ 967 WIV_nicht_betriebswarm 0;
BA_ "GenSigSwitchedByIgnition" SG_ 967 WIV_Ueberfuell_Warn 0;
BA_ "GenSigSendType" SG_ 967 WIV_Ueberfuell_Warn 0;
BA_ "GenSigSwitchedByIgnition" SG_ 967 WIV_laufender_Motor 0;
BA_ "GenSigSendType" SG_ 967 WIV_laufender_Motor 0;
BA_ "GenSigSwitchedByIgnition" SG_ 967 MO_E_Warnungen 0;
BA_ "GenSigSendType" SG_ 967 MO_E_Warnungen 0;
BA_ "GenSigSwitchedByIgnition" SG_ 967 MO_Text_Motorstart 0;
BA_ "GenSigSendType" SG_ 967 MO_Text_Motorstart 0;
BA_ "GenSigSwitchedByIgnition" SG_ 967 MO_E_Texte 0;
BA_ "GenSigSendType" SG_ 967 MO_E_Texte 0;
BA_ "GenSigSwitchedByIgnition" SG_ 967 WIV_Oeldyn_avl 0;
BA_ "GenSigSendType" SG_ 967 WIV_Oeldyn_avl 0;
BA_ "GenSigSwitchedByIgnition" SG_ 967 MO_Text_Partikelfil_Reg 0;
BA_ "GenSigSendType" SG_ 967 MO_Text_Partikelfil_Reg 0;
BA_ "GenSigSwitchedByIgnition" SG_ 967 OLEV_Oelstand_nicht_vorhanden 0;
BA_ "GenSigSendType" SG_ 967 OLEV_Oelstand_nicht_vorhanden 0;
BA_ "GenSigSwitchedByIgnition" SG_ 967 WIV_Oelmenge 0;
BA_ "GenSigSendType" SG_ 967 WIV_Oelmenge 0;
BA_ "GenSigSwitchedByIgnition" SG_ 967 MO_Systemlampe 0;
BA_ "GenSigSendType" SG_ 967 MO_Systemlampe 0;
BA_ "GenSigSwitchedByIgnition" SG_ 967 MO_OBD2_Lampe 0;
BA_ "GenSigSendType" SG_ 967 MO_OBD2_Lampe 0;
BA_ "GenSigSwitchedByIgnition" SG_ 967 MO_Heissleuchte 0;
BA_ "GenSigSendType" SG_ 967 MO_Heissleuchte 0;
BA_ "GenSigSwitchedByIgnition" SG_ 967 MO_Partikel_Lampe 0;
BA_ "GenSigSendType" SG_ 967 MO_Partikel_Lampe 0;
BA_ "GenSigSwitchedByIgnition" SG_ 967 MO_RedFahrleistung_Lampe 0;
BA_ "GenSigSendType" SG_ 967 MO_RedFahrleistung_Lampe 0;
BA_ "GenSigSwitchedByIgnition" SG_ 967 WIV_Oelstand_nicht_vorhanden 0;
BA_ "GenSigSendType" SG_ 967 WIV_Oelstand_nicht_vorhanden 0;
BA_ "GenSigSwitchedByIgnition" SG_ 967 WIV_nachfuellanzeige_ein 0;
BA_ "GenSigSendType" SG_ 967 WIV_nachfuellanzeige_ein 0;
BA_ "GenSigSwitchedByIgnition" SG_ 967 WIV_Ueberfuell_deaktiv 0;
BA_ "GenSigSendType" SG_ 967 WIV_Ueberfuell_deaktiv 0;
BA_ "GenSigSwitchedByIgnition" SG_ 967 WIV_Unterfuell_Warn 0;
BA_ "GenSigSendType" SG_ 967 WIV_Unterfuell_Warn 0;
BA_ "GenSigSwitchedByIgnition" SG_ 967 MO_Tankdeckel_Lampe 0;
BA_ "GenSigSendType" SG_ 967 MO_Tankdeckel_Lampe 0;
BA_ "GenSigSwitchedByIgnition" SG_ 967 MO_Text_Tankdeckelwarn 0;
BA_ "GenSigSendType" SG_ 967 MO_Text_Tankdeckelwarn 0;
BA_ "GenSigSwitchedByIgnition" SG_ 967 MO_Vorglueh_Lampe 0;
BA_ "GenSigSendType" SG_ 967 MO_Vorglueh_Lampe 0;
BA_ "GenSigSwitchedByIgnition" SG_ 967 WIV_Oeldr_Warn_Motor 0;
BA_ "GenSigSendType" SG_ 967 WIV_Oeldr_Warn_Motor 0;
BA_ "GenSigSwitchedByIgnition" SG_ 967 MO_E_Mode 0;
BA_ "GenSigSendType" SG_ 967 MO_E_Mode 0;
BA_REL_ "GenSigTimeoutTime" BU_SG_REL_ SitzMem_FS SG_ 1639 BFS_Klapptisch_offen 1000;
BA_REL_ "GenSigTimeoutTime" BU_SG_REL_ SitzMem_FS SG_ 1639 BFS_Sitzsym_Fahrt_aktiv 1000;
BA_REL_ "GenSigTimeoutTime" BU_SG_REL_ SitzMem_FS SG_ 1639 BFS_Sitzfahrt_aktiv 1000;
BA_REL_ "GenSigTimeoutTime" BU_SG_REL_ SitzMem_HBFS SG_ 1639 BFS_Sitzfahrt_aktiv 1000;
BA_REL_ "GenSigTimeoutTime" BU_SG_REL_ SitzMem_FS SG_ 1639 BFS_KSS_Fahrt_aktiv 1000;
BA_REL_ "GenSigTimeoutTime" BU_SG_REL_ SitzMem_FS SG_ 1639 BFS_Ruhestellung_Status 1000;
BA_REL_ "GenSigTimeoutTime" BU_SG_REL_ SitzMem_HBFS SG_ 1639 BFS_Ruhestellung_Status 1000;
BA_REL_ "GenSigTimeoutTime" BU_SG_REL_ TSG_BFS SG_ 1639 BFS_MMB_store_LED_on 1000;
BA_REL_ "GenSigTimeoutTime" BU_SG_REL_ SitzMem_FS SG_ 957 Mem_BFSFo_Massage_Geschw 1000;
BA_REL_ "GenSigTimeoutTime" BU_SG_REL_ SitzMem_FS SG_ 957 Mem_BFSFo_Massage_Intens 1000;
BA_REL_ "GenSigTimeoutTime" BU_SG_REL_ SitzMem_FS SG_ 957 Mem_BFSFo_Massage_Prg 1000;
BA_REL_ "GenSigTimeoutTime" BU_SG_REL_ TSG_BFS SG_ 957 Mem_BFSFo_MMB_store_LED_on 1000;
BA_REL_ "GenSigTimeoutTime" BU_SG_REL_ TSG_FS SG_ 957 Mem_BFSFo_MMB_store_LED_on 1000;
BA_REL_ "GenSigTimeoutTime" BU_SG_REL_ SitzMem_BFS SG_ 957 Mem_BFSFo_Sitzfahrt_aktiv 1000;
BA_REL_ "GenSigTimeoutTime" BU_SG_REL_ SitzMem_FS SG_ 957 Mem_BFSFo_Sitzfahrt_aktiv 1000;
BA_REL_ "GenSigTimeoutTime" BU_SG_REL_ SitzMem_BFS SG_ 957 Mem_BFSFo_BFS_Freigabe 1000;
BA_REL_ "GenSigTimeoutTime" BU_SG_REL_ SitzMem_BFS SG_ 957 Mem_BFSFo_RSE_zurueck 1000;
BA_REL_ "GenSigTimeoutTime" BU_SG_REL_ SitzMem_BFS SG_ 957 Mem_BFSFo_RSE_vor 1000;
BA_REL_ "GenSigTimeoutTime" BU_SG_REL_ SitzMem_BFS SG_ 957 Mem_BFSFo_Business_anfahren 1000;
BA_REL_ "GenSigTimeoutTime" BU_SG_REL_ SitzMem_BFS SG_ 957 Mem_BFSFo_Relax_anfahren 1000;
BA_REL_ "GenSigTimeoutTime" BU_SG_REL_ SitzMem_BFS SG_ 957 BFS_Kopfstuetze_vor 1000;
BA_REL_ "GenSigTimeoutTime" BU_SG_REL_ SitzMem_BFS SG_ 957 BFS_Kopfstuetze_zurueck 1000;
BA_REL_ "GenSigTimeoutTime" BU_SG_REL_ SitzMem_BFS SG_ 957 Mem_BFSFo_BFS_RSE_Freigabe 1000;
BA_REL_ "GenSigTimeoutTime" BU_SG_REL_ SitzMem_BFS SG_ 957 Mem_BFSFo_Fusstuetze_runter 1000;
BA_REL_ "GenSigTimeoutTime" BU_SG_REL_ SitzMem_BFS SG_ 957 Mem_BFSFo_Fusstuetze_hoch 1000;
BA_REL_ "GenSigTimeoutTime" BU_SG_REL_ SitzMem_BFS SG_ 1178 FS_Fond_Bed_enable 1000;
BA_REL_ "GenSigTimeoutTime" BU_SG_REL_ SitzMem_HBFS SG_ 1178 FS_Fond_Bed_enable 1000;
BA_REL_ "GenSigTimeoutTime" BU_SG_REL_ SitzMem_BFS SG_ 1178 FS_Spezialposition_anfahren 1000;
BA_REL_ "GenSigTimeoutTime" BU_SG_REL_ SitzMem_HBFS SG_ 1178 FS_Spezialposition_anfahren 1000;
BA_REL_ "GenSigTimeoutTime" BU_SG_REL_ SitzMem_HFS SG_ 1178 FS_Spezialposition_anfahren 1000;
BA_REL_ "GenSigTimeoutTime" BU_SG_REL_ SitzMem_BFS SG_ 1178 FS_BFS_Sitzsym_Anfahrt 1000;
BA_REL_ "GenSigTimeoutTime" BU_SG_REL_ BCM1 SG_ 1178 FS_Sitzfahrt_aktiv 1000;
BA_REL_ "GenSigTimeoutTime" BU_SG_REL_ TSG_BFS SG_ 1178 FS_Sitzfahrt_aktiv 1000;
BA_REL_ "GenSigTimeoutTime" BU_SG_REL_ TSG_FS SG_ 1178 FS_Sitzfahrt_aktiv 1000;
BA_REL_ "GenSigTimeoutTime" BU_SG_REL_ SitzMem_BFS SG_ 1178 FS_BFS_KSS_Anfahrt 1000;
BA_REL_ "GenSigTimeoutTime" BU_SG_REL_ BCM1 SG_ 1178 FS_MMB_storage 1000;
BA_REL_ "GenSigTimeoutTime" BU_SG_REL_ TSG_BFS SG_ 1178 FS_MMB_storage 1000;
BA_REL_ "GenSigTimeoutTime" BU_SG_REL_ TSG_FS SG_ 1178 FS_MMB_storage 1000;
BA_REL_ "GenSigTimeoutTime" BU_SG_REL_ BCM1 SG_ 1178 FS_MMB_tipp 1000;
BA_REL_ "GenSigTimeoutTime" BU_SG_REL_ TSG_BFS SG_ 1178 FS_MMB_tipp 1000;
BA_REL_ "GenSigTimeoutTime" BU_SG_REL_ TSG_FS SG_ 1178 FS_MMB_tipp 1000;
BA_REL_ "GenSigTimeoutTime" BU_SG_REL_ BCM1 SG_ 1178 FS_MMB_tast 1000;
BA_REL_ "GenSigTimeoutTime" BU_SG_REL_ TSG_BFS SG_ 1178 FS_MMB_tast 1000;
BA_REL_ "GenSigTimeoutTime" BU_SG_REL_ TSG_FS SG_ 1178 FS_MMB_tast 1000;
BA_REL_ "GenSigTimeoutTime" BU_SG_REL_ TSG_FS SG_ 1178 FS_MMB_store_LED_on 1000;
BA_REL_ "GenSigTimeoutTime" BU_SG_REL_ BCM1 SG_ 1178 FS_MMB_store 1000;
BA_REL_ "GenSigTimeoutTime" BU_SG_REL_ TSG_BFS SG_ 1178 FS_MMB_store 1000;
BA_REL_ "GenSigTimeoutTime" BU_SG_REL_ TSG_FS SG_ 1178 FS_MMB_store 1000;
BA_REL_ "GenSigTimeoutTime" BU_SG_REL_ BCM1 SG_ 1178 FS_MMB_glob_stop 1000;
BA_REL_ "GenSigTimeoutTime" BU_SG_REL_ SitzMem_BFS SG_ 1178 FS_MMB_glob_stop 1000;
BA_REL_ "GenSigTimeoutTime" BU_SG_REL_ SitzMem_HBFS SG_ 1178 FS_MMB_glob_stop 1000;
BA_REL_ "GenSigTimeoutTime" BU_SG_REL_ SitzMem_HFS SG_ 1178 FS_MMB_glob_stop 1000;
BA_REL_ "GenSigTimeoutTime" BU_SG_REL_ TSG_BFS SG_ 1178 FS_MMB_glob_stop 1000;
BA_REL_ "GenSigTimeoutTime" BU_SG_REL_ TSG_FS SG_ 1178 FS_MMB_glob_stop 1000;
BA_REL_ "GenSigTimeoutTime" BU_SG_REL_ SitzMem_HBFS SG_ 1178 FS_EE_Fond_FS_enable 1000;
BA_REL_ "GenSigTimeoutTime" BU_SG_REL_ SitzMem_HFS SG_ 1178 FS_EE_Fond_FS_enable 1000;
BA_REL_ "GenSigTimeoutTime" BU_SG_REL_ SitzMem_HBFS SG_ 1178 FS_EE_Fond_BFS_enable 1000;
BA_REL_ "GenSigTimeoutTime" BU_SG_REL_ SitzMem_HFS SG_ 1178 FS_EE_Fond_BFS_enable 1000;
BA_REL_ "GenSigTimeoutTime" BU_SG_REL_ SitzMem_BFS SG_ 1178 FS_BFS_Fond_Verst_enable 1000;
BA_REL_ "GenSigTimeoutTime" BU_SG_REL_ SitzMem_HBFS SG_ 1178 FS_BFS_Fond_Verst_enable 1000;
BA_REL_ "GenSigTimeoutTime" BU_SG_REL_ SitzMem_BFS SG_ 954 FS_BFS_aufraeumen 1000;
BA_REL_ "GenSigTimeoutTime" BU_SG_REL_ SitzMem_HBFS SG_ 954 FS_BFSFo_aufraeumen 1000;
BA_REL_ "GenSigTimeoutTime" BU_SG_REL_ SitzMem_HFS SG_ 954 FS_FSFo_aufraeumen 1000;
BA_REL_ "GenSigTimeoutTime" BU_SG_REL_ SitzMem_BFS SG_ 954 FS_BFS_Multifunktionstaster_hoch 1000;
BA_REL_ "GenSigTimeoutTime" BU_SG_REL_ SitzMem_BFS SG_ 954 FS_BFS_Multifunktionstaster_tief 1000;
BA_REL_ "GenSigTimeoutTime" BU_SG_REL_ SitzMem_BFS SG_ 954 FS_BFS_Multifunktionstaster_vor 1000;
BA_REL_ "GenSigTimeoutTime" BU_SG_REL_ SitzMem_BFS SG_ 954 FS_BFS_Multifunktionstaster_zur 1000;
BA_REL_ "GenSigTimeoutTime" BU_SG_REL_ SitzMem_BFS SG_ 954 FS_BFS_Programmwippe_hoch 1000;
BA_REL_ "GenSigTimeoutTime" BU_SG_REL_ SitzMem_BFS SG_ 954 FS_BFS_Programmwippe_tief 1000;
BA_REL_ "GenSigTimeoutTime" BU_SG_REL_ SitzMem_BFS SG_ 954 FS_BFS_SHV_Taste_hoch 1000;
BA_REL_ "GenSigTimeoutTime" BU_SG_REL_ SitzMem_BFS SG_ 954 FS_BFS_SHV_Taste_tief 1000;
BA_REL_ "GenSigTimeoutTime" BU_SG_REL_ SitzMem_BFS SG_ 954 FS_BFS_SLV_Taste_vor 1000;
BA_REL_ "GenSigTimeoutTime" BU_SG_REL_ SitzMem_BFS SG_ 954 FS_BFS_SLV_Taste_zurueck 1000;
BA_REL_ "GenSigTimeoutTime" BU_SG_REL_ SitzMem_BFS SG_ 954 FS_BFS_SNV_Taste_hoch 1000;
BA_REL_ "GenSigTimeoutTime" BU_SG_REL_ SitzMem_BFS SG_ 954 FS_BFS_SNV_Taste_tief 1000;
BA_REL_ "GenSigTimeoutTime" BU_SG_REL_ SitzMem_BFS SG_ 954 FS_BFS_KSV_Taste_hoch 1000;
BA_REL_ "GenSigTimeoutTime" BU_SG_REL_ SitzMem_BFS SG_ 954 FS_BFS_KSV_Taste_tief 1000;
BA_REL_ "GenSigTimeoutTime" BU_SG_REL_ SitzMem_BFS SG_ 954 FS_BFS_LNV_Taste_vor 1000;
BA_REL_ "GenSigTimeoutTime" BU_SG_REL_ SitzMem_BFS SG_ 954 FS_BFS_LNV_Taste_zurueck 1000;
BA_REL_ "GenSigTimeoutTime" BU_SG_REL_ SitzMem_BFS SG_ 954 FS_BFS_Massage_Taste 1000;
BA_REL_ "GenSigTimeoutTime" BU_SG_REL_ SitzMem_FS SG_ 956 Mem_FSFo_Massage_Geschw 1000;
BA_REL_ "GenSigTimeoutTime" BU_SG_REL_ SitzMem_FS SG_ 956 Mem_FSFo_Massage_Intens 1000;
BA_REL_ "GenSigTimeoutTime" BU_SG_REL_ SitzMem_FS SG_ 956 Mem_FSFo_Massage_Prg 1000;
BA_REL_ "GenSigTimeoutTime" BU_SG_REL_ TSG_BFS SG_ 956 Mem_FSFo_MMB_store_LED_on 1000;
BA_REL_ "GenSigTimeoutTime" BU_SG_REL_ TSG_FS SG_ 956 Mem_FSFo_MMB_store_LED_on 1000;
BA_REL_ "GenSigTimeoutTime" BU_SG_REL_ SitzMem_FS SG_ 956 Mem_FSFo_Sitzfahrt_aktiv 1000;
BA_REL_ "GenSigTimeoutTime" BU_SG_REL_ SitzMem_BFS SG_ 1180 Mem_Taster_BT_01_CRC 1000;
BA_REL_ "GenSigTimeoutTime" BU_SG_REL_ SitzMem_FS SG_ 1180 Mem_Taster_BT_01_CRC 1000;
BA_REL_ "GenSigTimeoutTime" BU_SG_REL_ SitzMem_BFS SG_ 1180 Mem_Taster_BT_01_BZ 1000;
BA_REL_ "GenSigTimeoutTime" BU_SG_REL_ SitzMem_FS SG_ 1180 Mem_Taster_BT_01_BZ 1000;
BA_REL_ "GenSigTimeoutTime" BU_SG_REL_ SitzMem_BFS SG_ 1180 MTBT_Pos1 1000;
BA_REL_ "GenSigTimeoutTime" BU_SG_REL_ SitzMem_FS SG_ 1180 MTBT_Pos1 1000;
BA_REL_ "GenSigTimeoutTime" BU_SG_REL_ SitzMem_HBFS SG_ 1180 MTBT_Pos1 1000;
BA_REL_ "GenSigTimeoutTime" BU_SG_REL_ SitzMem_BFS SG_ 1180 MTBT_Pos2 1000;
BA_REL_ "GenSigTimeoutTime" BU_SG_REL_ SitzMem_FS SG_ 1180 MTBT_Pos2 1000;
BA_REL_ "GenSigTimeoutTime" BU_SG_REL_ SitzMem_HBFS SG_ 1180 MTBT_Pos2 1000;
BA_REL_ "GenSigTimeoutTime" BU_SG_REL_ SitzMem_BFS SG_ 1180 MTBT_Pos3 1000;
BA_REL_ "GenSigTimeoutTime" BU_SG_REL_ SitzMem_FS SG_ 1180 MTBT_Pos3 1000;
BA_REL_ "GenSigTimeoutTime" BU_SG_REL_ SitzMem_HBFS SG_ 1180 MTBT_Pos3 1000;
BA_REL_ "GenSigTimeoutTime" BU_SG_REL_ SitzMem_BFS SG_ 1180 MTBT_Pos4 1000;
BA_REL_ "GenSigTimeoutTime" BU_SG_REL_ SitzMem_FS SG_ 1180 MTBT_Pos4 1000;
BA_REL_ "GenSigTimeoutTime" BU_SG_REL_ SitzMem_BFS SG_ 1180 MTBT_On_Off 1000;
BA_REL_ "GenSigTimeoutTime" BU_SG_REL_ SitzMem_FS SG_ 1180 MTBT_On_Off 1000;
BA_REL_ "GenSigTimeoutTime" BU_SG_REL_ SitzMem_BFS SG_ 1180 MTBT_M_Taste 1000;
BA_REL_ "GenSigTimeoutTime" BU_SG_REL_ SitzMem_FS SG_ 1180 MTBT_M_Taste 1000;
BA_REL_ "GenSigTimeoutTime" BU_SG_REL_ SitzMem_HBFS SG_ 1180 MTBT_M_Taste 1000;
BA_REL_ "GenSigTimeoutTime" BU_SG_REL_ SitzMem_FS SG_ 1170 Mem_Taster_FT_01_CRC 1000;
BA_REL_ "GenSigTimeoutTime" BU_SG_REL_ SitzMem_FS SG_ 1170 Mem_Taster_FT_01_BZ 1000;
BA_REL_ "GenSigTimeoutTime" BU_SG_REL_ SitzMem_FS SG_ 1170 MTFT_Pos1_EE 1000;
BA_REL_ "GenSigTimeoutTime" BU_SG_REL_ SitzMem_FS SG_ 1170 MTFT_Pos2 1000;
BA_REL_ "GenSigTimeoutTime" BU_SG_REL_ SitzMem_FS SG_ 1170 MTFT_Pos3 1000;
BA_REL_ "GenSigTimeoutTime" BU_SG_REL_ SitzMem_FS SG_ 1170 MTFT_Pos4 1000;
BA_REL_ "GenSigTimeoutTime" BU_SG_REL_ SitzMem_FS SG_ 1170 MTFT_On_Off 1000;
BA_REL_ "GenSigTimeoutTime" BU_SG_REL_ SitzMem_FS SG_ 1170 MTFT_Verst_akt 1000;
BA_REL_ "GenSigTimeoutTime" BU_SG_REL_ SitzMem_FS SG_ 1170 MTFT_M_Taste 1000;
BA_REL_ "GenSigTimeoutTime" BU_SG_REL_ SitzMem_BFS SG_ 1173 MTHBF_CRC 1000;
BA_REL_ "GenSigTimeoutTime" BU_SG_REL_ SitzMem_BFS SG_ 1173 MTHBF_BZ 1000;
BA_REL_ "GenSigTimeoutTime" BU_SG_REL_ SitzMem_BFS SG_ 1173 BFS_Sitzhoehe_hoch 1000;
BA_REL_ "GenSigTimeoutTime" BU_SG_REL_ SitzMem_BFS SG_ 1173 BFS_Sitzhoehe_runter 1000;
BA_REL_ "GenSigTimeoutTime" BU_SG_REL_ SitzMem_BFS SG_ 1173 MTHBF_ein 1000;
BA_REL_ "GenSigTimeoutTime" BU_SG_REL_ SitzMem_BFS SG_ 1173 BFS_Laengsverst_vor 1000;
BA_REL_ "GenSigTimeoutTime" BU_SG_REL_ SitzMem_BFS SG_ 1173 BFS_Laengsverst_zurueck 1000;
BA_REL_ "GenSigTimeoutTime" BU_SG_REL_ SitzMem_BFS SG_ 1173 BFS_Lehnenneigung_vor 1000;
BA_REL_ "GenSigTimeoutTime" BU_SG_REL_ SitzMem_BFS SG_ 1173 BFS_Lehnenneigung_zurueck 1000;
BA_REL_ "GenSigTimeoutTime" BU_SG_REL_ SitzMem_BFS SG_ 1173 BFS_Lehnenkopf_vor 1000;
BA_REL_ "GenSigTimeoutTime" BU_SG_REL_ SitzMem_BFS SG_ 1173 BFS_Lehnenkopf_zurueck 1000;
BA_REL_ "GenSigTimeoutTime" BU_SG_REL_ SitzMem_BFS SG_ 1173 BFS_Kopfstuetzen_hoch 1000;
BA_REL_ "GenSigTimeoutTime" BU_SG_REL_ SitzMem_BFS SG_ 1173 BFS_Kopfstuetzen_runter 1000;
BA_REL_ "GenSigTimeoutTime" BU_SG_REL_ BCM1 SG_ 1171 MFG_01_CRC 2000;
BA_REL_ "GenSigTimeoutTime" BU_SG_REL_ BCM2 SG_ 1171 MFG_01_CRC 2000;
BA_REL_ "GenSigTimeoutTime" BU_SG_REL_ TSG_FS SG_ 1171 MFG_01_CRC 2000;
BA_REL_ "GenSigTimeoutTime" BU_SG_REL_ BCM1 SG_ 1171 MFG_01_BZ 2000;
BA_REL_ "GenSigTimeoutTime" BU_SG_REL_ BCM2 SG_ 1171 MFG_01_BZ 2000;
BA_REL_ "GenSigTimeoutTime" BU_SG_REL_ TSG_FS SG_ 1171 MFG_01_BZ 2000;
BA_REL_ "GenSigTimeoutTime" BU_SG_REL_ BCM2 SG_ 1171 MF_ZV_Lock 2000;
BA_REL_ "GenSigTimeoutTime" BU_SG_REL_ BCM2 SG_ 1171 MF_Motorweiterlauf 2000;
BA_REL_ "GenSigTimeoutTime" BU_SG_REL_ BCM2 SG_ 1171 MF_Abzugssperre 2000;
BA_REL_ "GenSigTimeoutTime" BU_SG_REL_ BCM2 SG_ 1171 MF_Anlassersperre 2000;
BA_REL_ "GenSigTimeoutTime" BU_SG_REL_ BCM1 SG_ 1171 MF_Variante 2000;
BA_REL_ "GenSigTimeoutTime" BU_SG_REL_ BCM2 SG_ 1171 MF_Variante 2000;
BA_REL_ "GenSigTimeoutTime" BU_SG_REL_ Gateway SG_ 1171 MF_Variante 2000;
BA_REL_ "GenSigTimeoutTime" BU_SG_REL_ TSG_BFS SG_ 1171 MF_Variante 2000;
BA_REL_ "GenSigTimeoutTime" BU_SG_REL_ TSG_FS SG_ 1171 MF_Variante 2000;
BA_REL_ "GenSigTimeoutTime" BU_SG_REL_ Gateway SG_ 1171 MF_Laderelais 2000;
BA_REL_ "GenSigTimeoutTime" BU_SG_REL_ Gateway SG_ 1171 MF_StartStopp_Info 2000;
BA_REL_ "GenSigTimeoutTime" BU_SG_REL_ BCM1 SG_ 1171 MF_Fernbed_ein 2000;
BA_REL_ "GenSigTimeoutTime" BU_SG_REL_ BCM2 SG_ 1171 MF_Fernbed_ein 2000;
BA_REL_ "GenSigTimeoutTime" BU_SG_REL_ TSG_BFS SG_ 1171 MF_Fernbed_ein 2000;
BA_REL_ "GenSigTimeoutTime" BU_SG_REL_ TSG_FS SG_ 1171 MF_Fernbed_ein 2000;
BA_REL_ "GenSigTimeoutTime" BU_SG_REL_ BCM1 SG_ 1171 MF_Standlicht 2000;
BA_REL_ "GenSigTimeoutTime" BU_SG_REL_ BCM1 SG_ 1171 MF_Fahrlicht 2000;
BA_REL_ "GenSigTimeoutTime" BU_SG_REL_ BCM1 SG_ 1171 MF_interm_Fernlicht 2000;
BA_REL_ "GenSigTimeoutTime" BU_SG_REL_ BCM1 SG_ 1171 MF_Warnblinker 2000;
BA_REL_ "GenSigTimeoutTime" BU_SG_REL_ BCM2 SG_ 1171 MF_Warnblinker 2000;
BA_REL_ "GenSigTimeoutTime" BU_SG_REL_ BCM1 SG_ 1171 MF_Fussraumbel 2000;
BA_REL_ "GenSigTimeoutTime" BU_SG_REL_ TSG_FS SG_ 1171 MF_Fussraumbel 2000;
BA_REL_ "GenSigTimeoutTime" BU_SG_REL_ BCM1 SG_ 1171 MF_Innenraumbel 2000;
BA_REL_ "GenSigTimeoutTime" BU_SG_REL_ TSG_BFS SG_ 1171 MF_Innenraumbel 2000;
BA_REL_ "GenSigTimeoutTime" BU_SG_REL_ TSG_FS SG_ 1171 MF_Innenraumbel 2000;
BA_REL_ "GenSigTimeoutTime" BU_SG_REL_ BCM1 SG_ 1171 MF_Innenraumbel_Unterdrueck 2000;
BA_REL_ "GenSigTimeoutTime" BU_SG_REL_ TSG_BFS SG_ 1171 MF_Innenraumbel_Unterdrueck 2000;
BA_REL_ "GenSigTimeoutTime" BU_SG_REL_ TSG_FS SG_ 1171 MF_Innenraumbel_Unterdrueck 2000;
BA_REL_ "GenSigTimeoutTime" BU_SG_REL_ Gateway SG_ 1171 MF_Notstart 2000;
BA_REL_ "GenSigTimeoutTime" BU_SG_REL_ BCM2 SG_ 1171 MF_Blk_li 2000;
BA_REL_ "GenSigTimeoutTime" BU_SG_REL_ BCM2 SG_ 1171 MF_Blk_re 2000;
BA_REL_ "GenSigTimeoutTime" BU_SG_REL_ BCM1 SG_ 1171 MF_Lichthupe 2000;
BA_REL_ "GenSigTimeoutTime" BU_SG_REL_ BCM1 SG_ 1171 MF_Fernlicht 2000;
BA_REL_ "GenSigTimeoutTime" BU_SG_REL_ TSG_FS SG_ 1171 MF_HFS_verriegeln 2000;
BA_REL_ "GenSigTimeoutTime" BU_SG_REL_ TSG_FS SG_ 1171 MF_HFS_entriegeln 2000;
BA_REL_ "GenSigTimeoutTime" BU_SG_REL_ TSG_BFS SG_ 1171 MF_HBFS_verriegeln 2000;
BA_REL_ "GenSigTimeoutTime" BU_SG_REL_ TSG_BFS SG_ 1171 MF_HBFS_entriegeln 2000;
BA_REL_ "GenSigTimeoutTime" BU_SG_REL_ BCM1 SG_ 1171 MF_Tippwischen 2000;
BA_REL_ "GenSigTimeoutTime" BU_SG_REL_ BCM1 SG_ 1171 MF_Frontintervall 2000;
BA_REL_ "GenSigTimeoutTime" BU_SG_REL_ BCM1 SG_ 1171 MF_Wischerstufe_1 2000;
BA_REL_ "GenSigTimeoutTime" BU_SG_REL_ BCM1 SG_ 1171 MF_Wischerstufe_2 2000;
BA_REL_ "GenSigTimeoutTime" BU_SG_REL_ BCM1 SG_ 1171 MF_Frontwaschen 2000;
BA_REL_ "GenSigTimeoutTime" BU_SG_REL_ BCM1 SG_ 1171 MF_Heckintervall 2000;
BA_REL_ "GenSigTimeoutTime" BU_SG_REL_ BCM1 SG_ 1171 MF_Heckwaschen 2000;
BA_REL_ "GenSigTimeoutTime" BU_SG_REL_ BCM2 SG_ 1171 MF_Alarm_Blinker 2000;
BA_REL_ "GenSigTimeoutTime" BU_SG_REL_ VTS SG_ 1171 MF_Alarm_Blinker 2000;
BA_REL_ "GenSigTimeoutTime" BU_SG_REL_ BCM1 SG_ 1171 MF_TFL_Abschaltung 2000;
BA_REL_ "GenSigTimeoutTime" BU_SG_REL_ BCM1 SG_ 1171 MF_Signalhorn 2000;
BA_REL_ "GenSigTimeoutTime" BU_SG_REL_ TSG_FS SG_ 1171 MF_FH_FT_hoch 2000;
BA_REL_ "GenSigTimeoutTime" BU_SG_REL_ TSG_FS SG_ 1171 MF_FH_FT_tief 2000;
BA_REL_ "GenSigTimeoutTime" BU_SG_REL_ TSG_BFS SG_ 1171 MF_FH_BT_hoch 2000;
BA_REL_ "GenSigTimeoutTime" BU_SG_REL_ TSG_BFS SG_ 1171 MF_FH_BT_tief 2000;
BA_REL_ "GenSigTimeoutTime" BU_SG_REL_ TSG_FS SG_ 1171 MF_FT_verriegeln 2000;
BA_REL_ "GenSigTimeoutTime" BU_SG_REL_ TSG_FS SG_ 1171 MF_FT_entriegeln 2000;
BA_REL_ "GenSigTimeoutTime" BU_SG_REL_ TSG_BFS SG_ 1171 MF_BT_verriegeln 2000;
BA_REL_ "GenSigTimeoutTime" BU_SG_REL_ TSG_BFS SG_ 1171 MF_BT_entriegeln 2000;
BA_REL_ "GenSigTimeoutTime" BU_SG_REL_ BCM1 SG_ 817 MFL_Signalhorn 5000;
BA_REL_ "GenSigTimeoutTime" BU_SG_REL_ MFG SG_ 817 MFL_Signalhorn 5000;
BA_REL_ "GenSigTimeoutTime" BU_SG_REL_ BCM2 SG_ 349 MO2_Freigabe_Info_WFS 5000;
BA_REL_ "GenSigTimeoutTime" BU_SG_REL_ BCM2 SG_ 349 MO2_Sperr_Info_WFS 5000;
BA_REL_ "GenSigTimeoutTime" BU_SG_REL_ BCM2 SG_ 349 MO2_Freigabe_Verfallsinfo_WFS 5000;
BA_REL_ "GenSigTimeoutTime" BU_SG_REL_ BCM2 SG_ 1600 MO_KL15_Abschaltempfehlung 3200;
BA_REL_ "GenSigTimeoutTime" BU_SG_REL_ BCM1 SG_ 1600 MO_Absperrventil_oeffnen 3200;
BA_REL_ "GenSigTimeoutTime" BU_SG_REL_ VTS SG_ 1600 MO_Oel_Temp 3200;
BA_REL_ "GenSigTimeoutTime" BU_SG_REL_ BCM2 SG_ 1600 MO_Kuehlmittel_Temp 3200;
BA_REL_ "GenSigTimeoutTime" BU_SG_REL_ VTS SG_ 1600 MO_Kuehlmittel_Temp 3200;
BA_REL_ "GenSigTimeoutTime" BU_SG_REL_ BCM1 SG_ 1600 MO_Heizungspumpenansteuerung 3200;
BA_REL_ "GenSigTimeoutTime" BU_SG_REL_ BCM1 SG_ 1600 MO_Nachlaufzeit_Heizungspumpe 3200;
BA_REL_ "GenSigTimeoutTime" BU_SG_REL_ BCM2 SG_ 1607 SCR_Anz_Motorstarts 3200;
BA_REL_ "GenSigTimeoutTime" BU_SG_REL_ BCM2 SG_ 1607 SCR_verbaut 3200;
BA_REL_ "GenSigTimeoutTime" BU_SG_REL_ BCM1 SG_ 168 MO_QBit_Drehzahl_01 1000;
BA_REL_ "GenSigTimeoutTime" BU_SG_REL_ BCM2 SG_ 168 MO_QBit_Drehzahl_01 1000;
BA_REL_ "GenSigTimeoutTime" BU_SG_REL_ ELV SG_ 168 MO_QBit_Drehzahl_01 1000;
BA_REL_ "GenSigTimeoutTime" BU_SG_REL_ BCM1 SG_ 168 MO_Drehzahl_01 1000;
BA_REL_ "GenSigTimeoutTime" BU_SG_REL_ BCM2 SG_ 168 MO_Drehzahl_01 1000;
BA_REL_ "GenSigTimeoutTime" BU_SG_REL_ ELV SG_ 168 MO_Drehzahl_01 1000;
BA_REL_ "GenSigTimeoutTime" BU_SG_REL_ TSG_BFS SG_ 168 MO_Drehzahl_01 1000;
BA_REL_ "GenSigTimeoutTime" BU_SG_REL_ TSG_FS SG_ 168 MO_Drehzahl_01 1000;
BA_REL_ "GenSigTimeoutTime" BU_SG_REL_ VSG SG_ 168 MO_Drehzahl_01 1000;
BA_REL_ "GenSigTimeoutTime" BU_SG_REL_ VTS SG_ 168 MO_Drehzahl_01 1000;
BA_REL_ "GenSigTimeoutTime" BU_SG_REL_ BCM2 SG_ 958 Motor_14_CRC 1000;
BA_REL_ "GenSigTimeoutTime" BU_SG_REL_ BCM2 SG_ 958 Motor_14_BZ 1000;
BA_REL_ "GenSigTimeoutTime" BU_SG_REL_ BCM1 SG_ 958 MO_StartStopp_Status 1000;
BA_REL_ "GenSigTimeoutTime" BU_SG_REL_ BCM2 SG_ 958 MO_StartStopp_Status 1000;
BA_REL_ "GenSigTimeoutTime" BU_SG_REL_ BCM1 SG_ 958 MO_StartStopp_Wiederstart 1000;
BA_REL_ "GenSigTimeoutTime" BU_SG_REL_ BCM2 SG_ 958 MO_StartStopp_Wiederstart 1000;
BA_REL_ "GenSigTimeoutTime" BU_SG_REL_ HDSG SG_ 958 MO_StartStopp_Wiederstart 1000;
BA_REL_ "GenSigTimeoutTime" BU_SG_REL_ MFG SG_ 958 MO_StartStopp_Wiederstart 1000;
BA_REL_ "GenSigTimeoutTime" BU_SG_REL_ SAD SG_ 958 MO_StartStopp_Wiederstart 1000;
BA_REL_ "GenSigTimeoutTime" BU_SG_REL_ SAD2 SG_ 958 MO_StartStopp_Wiederstart 1000;
BA_REL_ "GenSigTimeoutTime" BU_SG_REL_ SitzMem_BFS SG_ 958 MO_StartStopp_Wiederstart 1000;
BA_REL_ "GenSigTimeoutTime" BU_SG_REL_ SitzMem_FS SG_ 958 MO_StartStopp_Wiederstart 1000;
BA_REL_ "GenSigTimeoutTime" BU_SG_REL_ SitzMem_HBFS SG_ 958 MO_StartStopp_Wiederstart 1000;
BA_REL_ "GenSigTimeoutTime" BU_SG_REL_ SitzMem_HFS SG_ 958 MO_StartStopp_Wiederstart 1000;
BA_REL_ "GenSigTimeoutTime" BU_SG_REL_ SitzMem_SR3 SG_ 958 MO_StartStopp_Wiederstart 1000;
BA_REL_ "GenSigTimeoutTime" BU_SG_REL_ SpoilerSG SG_ 958 MO_StartStopp_Wiederstart 1000;
BA_REL_ "GenSigTimeoutTime" BU_SG_REL_ TSG_BFS SG_ 958 MO_StartStopp_Wiederstart 1000;
BA_REL_ "GenSigTimeoutTime" BU_SG_REL_ TSG_FS SG_ 958 MO_StartStopp_Wiederstart 1000;
BA_REL_ "GenSigTimeoutTime" BU_SG_REL_ VSG SG_ 958 MO_StartStopp_Wiederstart 1000;
BA_REL_ "GenSigTimeoutTime" BU_SG_REL_ VTS SG_ 958 MO_StartStopp_Wiederstart 1000;
BA_REL_ "GenSigTimeoutTime" BU_SG_REL_ BCM1 SG_ 958 MO_StartStopp_Motorstopp 1000;
BA_REL_ "GenSigTimeoutTime" BU_SG_REL_ BCM2 SG_ 958 MO_StartStopp_Motorstopp 1000;
BA_REL_ "GenSigTimeoutTime" BU_SG_REL_ HDSG SG_ 958 MO_StartStopp_Motorstopp 1000;
BA_REL_ "GenSigTimeoutTime" BU_SG_REL_ MFG SG_ 958 MO_StartStopp_Motorstopp 1000;
BA_REL_ "GenSigTimeoutTime" BU_SG_REL_ SAD SG_ 958 MO_StartStopp_Motorstopp 1000;
BA_REL_ "GenSigTimeoutTime" BU_SG_REL_ SAD2 SG_ 958 MO_StartStopp_Motorstopp 1000;
BA_REL_ "GenSigTimeoutTime" BU_SG_REL_ SitzMem_BFS SG_ 958 MO_StartStopp_Motorstopp 1000;
BA_REL_ "GenSigTimeoutTime" BU_SG_REL_ SitzMem_FS SG_ 958 MO_StartStopp_Motorstopp 1000;
BA_REL_ "GenSigTimeoutTime" BU_SG_REL_ SitzMem_HBFS SG_ 958 MO_StartStopp_Motorstopp 1000;
BA_REL_ "GenSigTimeoutTime" BU_SG_REL_ SitzMem_HFS SG_ 958 MO_StartStopp_Motorstopp 1000;
BA_REL_ "GenSigTimeoutTime" BU_SG_REL_ SitzMem_SR3 SG_ 958 MO_StartStopp_Motorstopp 1000;
BA_REL_ "GenSigTimeoutTime" BU_SG_REL_ TSG_BFS SG_ 958 MO_StartStopp_Motorstopp 1000;
BA_REL_ "GenSigTimeoutTime" BU_SG_REL_ TSG_FS SG_ 958 MO_StartStopp_Motorstopp 1000;
BA_REL_ "GenSigTimeoutTime" BU_SG_REL_ VSG SG_ 958 MO_StartStopp_Motorstopp 1000;
BA_REL_ "GenSigTimeoutTime" BU_SG_REL_ VTS SG_ 958 MO_StartStopp_Motorstopp 1000;
BA_REL_ "GenSigTimeoutTime" BU_SG_REL_ AAG SG_ 958 MO_Kl_75 1000;
BA_REL_ "GenSigTimeoutTime" BU_SG_REL_ BCM1 SG_ 958 MO_Kl_75 1000;
BA_REL_ "GenSigTimeoutTime" BU_SG_REL_ BCM2 SG_ 958 MO_Kl_75 1000;
BA_REL_ "GenSigTimeoutTime" BU_SG_REL_ HDSG SG_ 958 MO_Kl_75 1000;
BA_REL_ "GenSigTimeoutTime" BU_SG_REL_ IEZS SG_ 958 MO_Kl_75 1000;
BA_REL_ "GenSigTimeoutTime" BU_SG_REL_ MSBBR SG_ 958 MO_Kl_75 1000;
BA_REL_ "GenSigTimeoutTime" BU_SG_REL_ SAD SG_ 958 MO_Kl_75 1000;
BA_REL_ "GenSigTimeoutTime" BU_SG_REL_ SitzMem_BFS SG_ 958 MO_Kl_75 1000;
BA_REL_ "GenSigTimeoutTime" BU_SG_REL_ SitzMem_FS SG_ 958 MO_Kl_75 1000;
BA_REL_ "GenSigTimeoutTime" BU_SG_REL_ SitzMem_HBFS SG_ 958 MO_Kl_75 1000;
BA_REL_ "GenSigTimeoutTime" BU_SG_REL_ SitzMem_HFS SG_ 958 MO_Kl_75 1000;
BA_REL_ "GenSigTimeoutTime" BU_SG_REL_ SitzMem_SR3 SG_ 958 MO_Kl_75 1000;
BA_REL_ "GenSigTimeoutTime" BU_SG_REL_ TSG_BFS SG_ 958 MO_Kl_75 1000;
BA_REL_ "GenSigTimeoutTime" BU_SG_REL_ TSG_FS SG_ 958 MO_Kl_75 1000;
BA_REL_ "GenSigTimeoutTime" BU_SG_REL_ VTS SG_ 958 MO_Kl_75 1000;
BA_REL_ "GenSigTimeoutTime" BU_SG_REL_ BCM2 SG_ 958 MO_Kl_50 1000;
BA_REL_ "GenSigTimeoutTime" BU_SG_REL_ TSG_BFS SG_ 958 MO_Kl_50 1000;
BA_REL_ "GenSigTimeoutTime" BU_SG_REL_ TSG_FS SG_ 958 MO_Kl_50 1000;
BA_REL_ "GenSigTimeoutTime" BU_SG_REL_ BCM1 SG_ 958 MO_Gangposition 1000;
BA_REL_ "GenSigTimeoutTime" BU_SG_REL_ BCM2 SG_ 958 MO_Gangposition 1000;
BA_REL_ "GenSigTimeoutTime" BU_SG_REL_ ELV SG_ 958 MO_Gangposition 1000;
BA_REL_ "GenSigTimeoutTime" BU_SG_REL_ MFG SG_ 958 MO_Gangposition 1000;
BA_REL_ "GenSigTimeoutTime" BU_SG_REL_ TSG_BFS SG_ 958 MO_Gangposition 1000;
BA_REL_ "GenSigTimeoutTime" BU_SG_REL_ TSG_FS SG_ 958 MO_Gangposition 1000;
BA_REL_ "GenSigTimeoutTime" BU_SG_REL_ BCM1 SG_ 958 MO_StartStopp_Fahrerwunsch 1000;
BA_REL_ "GenSigTimeoutTime" BU_SG_REL_ BCM2 SG_ 958 MO_StartStopp_Fahrerwunsch 1000;
BA_REL_ "GenSigTimeoutTime" BU_SG_REL_ BCM1 SG_ 958 MO_HYB_Fahrbereitschaft 1000;
BA_REL_ "GenSigTimeoutTime" BU_SG_REL_ BCM2 SG_ 958 MO_HYB_Fahrbereitschaft 1000;
BA_REL_ "GenSigTimeoutTime" BU_SG_REL_ ELV SG_ 958 MO_HYB_Fahrbereitschaft 1000;
BA_REL_ "GenSigTimeoutTime" BU_SG_REL_ IEZS SG_ 958 MO_HYB_Fahrbereitschaft 1000;
BA_REL_ "GenSigTimeoutTime" BU_SG_REL_ BCM1 SG_ 958 MO_Ext_E_Fahrt_aktiv 1000;
BA_REL_ "GenSigTimeoutTime" BU_SG_REL_ AAG SG_ 958 MO_Fahrer_bremst 1000;
BA_REL_ "GenSigTimeoutTime" BU_SG_REL_ BCM1 SG_ 958 MO_Fahrer_bremst 1000;
BA_REL_ "GenSigTimeoutTime" BU_SG_REL_ BCM2 SG_ 958 MO_Fahrer_bremst 1000;
BA_REL_ "GenSigTimeoutTime" BU_SG_REL_ MSBBR SG_ 958 MO_Fahrer_bremst 1000;
BA_REL_ "GenSigTimeoutTime" BU_SG_REL_ SAD SG_ 958 MO_Fahrer_bremst 1000;
BA_REL_ "GenSigTimeoutTime" BU_SG_REL_ SAD2 SG_ 958 MO_Fahrer_bremst 1000;
BA_REL_ "GenSigTimeoutTime" BU_SG_REL_ BCM1 SG_ 958 MO_QBit_Fahrer_bremst 1000;
BA_REL_ "GenSigTimeoutTime" BU_SG_REL_ BCM2 SG_ 958 MO_QBit_Fahrer_bremst 1000;
BA_REL_ "GenSigTimeoutTime" BU_SG_REL_ AAG SG_ 958 MO_BLS 1000;
BA_REL_ "GenSigTimeoutTime" BU_SG_REL_ BCM1 SG_ 958 MO_BLS 1000;
BA_REL_ "GenSigTimeoutTime" BU_SG_REL_ BCM2 SG_ 958 MO_BLS 1000;
BA_REL_ "GenSigTimeoutTime" BU_SG_REL_ MSBBR SG_ 958 MO_BLS 1000;
BA_REL_ "GenSigTimeoutTime" BU_SG_REL_ BCM2 SG_ 958 MO_Aussp_Anlass 1000;
BA_REL_ "GenSigTimeoutTime" BU_SG_REL_ BCM1 SG_ 958 MO_Kuppl_schalter 1000;
BA_REL_ "GenSigTimeoutTime" BU_SG_REL_ BCM2 SG_ 958 MO_Kuppl_schalter 1000;
BA_REL_ "GenSigTimeoutTime" BU_SG_REL_ BCM1 SG_ 958 MO_Interlock 1000;
BA_REL_ "GenSigTimeoutTime" BU_SG_REL_ BCM2 SG_ 958 MO_Interlock 1000;
BA_REL_ "GenSigTimeoutTime" BU_SG_REL_ BCM1 SG_ 958 MO_Motor_laeuft 1000;
BA_REL_ "GenSigTimeoutTime" BU_SG_REL_ BCM2 SG_ 958 MO_Motor_laeuft 1000;
BA_REL_ "GenSigTimeoutTime" BU_SG_REL_ IEZS SG_ 958 MO_Motor_laeuft 1000;
BA_REL_ "GenSigTimeoutTime" BU_SG_REL_ SAD SG_ 958 MO_Motor_laeuft 1000;
BA_REL_ "GenSigTimeoutTime" BU_SG_REL_ SAD2 SG_ 958 MO_Motor_laeuft 1000;
BA_REL_ "GenSigTimeoutTime" BU_SG_REL_ TSG_BFS SG_ 958 MO_Motor_laeuft 1000;
BA_REL_ "GenSigTimeoutTime" BU_SG_REL_ TSG_FS SG_ 958 MO_Motor_laeuft 1000;
BA_REL_ "GenSigTimeoutTime" BU_SG_REL_ AAG SG_ 958 MO_QBit_KL_75 1000;
BA_REL_ "GenSigTimeoutTime" BU_SG_REL_ BCM1 SG_ 958 MO_QBit_KL_75 1000;
BA_REL_ "GenSigTimeoutTime" BU_SG_REL_ BCM2 SG_ 958 MO_QBit_KL_75 1000;
BA_REL_ "GenSigTimeoutTime" BU_SG_REL_ HDSG SG_ 958 MO_QBit_KL_75 1000;
BA_REL_ "GenSigTimeoutTime" BU_SG_REL_ MSBBR SG_ 958 MO_QBit_KL_75 1000;
BA_REL_ "GenSigTimeoutTime" BU_SG_REL_ SAD SG_ 958 MO_QBit_KL_75 1000;
BA_REL_ "GenSigTimeoutTime" BU_SG_REL_ SAD2 SG_ 958 MO_QBit_KL_75 1000;
BA_REL_ "GenSigTimeoutTime" BU_SG_REL_ SitzMem_BFS SG_ 958 MO_QBit_KL_75 1000;
BA_REL_ "GenSigTimeoutTime" BU_SG_REL_ SitzMem_FS SG_ 958 MO_QBit_KL_75 1000;
BA_REL_ "GenSigTimeoutTime" BU_SG_REL_ SitzMem_HBFS SG_ 958 MO_QBit_KL_75 1000;
BA_REL_ "GenSigTimeoutTime" BU_SG_REL_ SitzMem_HFS SG_ 958 MO_QBit_KL_75 1000;
BA_REL_ "GenSigTimeoutTime" BU_SG_REL_ SitzMem_SR3 SG_ 958 MO_QBit_KL_75 1000;
BA_REL_ "GenSigTimeoutTime" BU_SG_REL_ BCM2 SG_ 958 MO_Remotestart_Betrieb 1000;
BA_REL_ "GenSigTimeoutTime" BU_SG_REL_ BCM2 SG_ 958 MO_StartVorauss_erfuellt 1000;
BA_REL_ "GenSigTimeoutTime" BU_SG_REL_ BCM2 SG_ 1648 MO1_Sperr_Info_WFS 5000;
BA_REL_ "GenSigTimeoutTime" BU_SG_REL_ BCM2 SG_ 1648 MO1_Freigabe_Info_WFS 5000;
BA_REL_ "GenSigTimeoutTime" BU_SG_REL_ BCM2 SG_ 1648 MO1_Freigabe_Verfallsinfo_WFS 5000;
BA_REL_ "GenSigTimeoutTime" BU_SG_REL_ BCM1 SG_ 1648 MO_Hybrid_StartStopp_LED 5000;
BA_REL_ "GenSigTimeoutTime" BU_SG_REL_ BCM1 SG_ 289 MO_Fahrpedalrohwert_01 500;
BA_REL_ "GenSigTimeoutTime" BU_SG_REL_ BCM2 SG_ 289 MO_temporaere_Fahrerabwesenheit 500;
BA_REL_ "GenSigTimeoutTime" BU_SG_REL_ VTS SG_ 967 WIV_Oelmin_Warn 5000;
BA_REL_ "GenSigTimeoutTime" BU_SG_REL_ VTS SG_ 967 WIV_Oelstand 5000;
BA_REL_ "GenSigTimeoutTime" BU_SG_REL_ VTS SG_ 967 WIV_Ueberfuell_Warn 5000;
BA_REL_ "GenSigTimeoutTime" BU_SG_REL_ VTS SG_ 967 MO_Systemlampe 5000;
BA_REL_ "GenSigTimeoutTime" BU_SG_REL_ VTS SG_ 967 WIV_Unterfuell_Warn 5000;
VAL_ 1639 BFS_Fond_Bed_Ack 0 "nicht aktiviert" 1 "aktiviert" ;
VAL_ 1639 BFS_Lehne_nicht_verriegelt 0 "keine Anzeige" 1 "Lehne_nicht_verriegelt" ;
VAL_ 1639 BFS_Klapptisch_offen 0 "inaktiv" 1 "aktiv" ;
VAL_ 1639 BFS_Sitzsym_Fahrt_aktiv 0 "inaktiv" 1 "aktiv" ;
VAL_ 1639 BFS_Sitzfahrt_aktiv 1 "Sitz in Bewegung" ;
VAL_ 1639 BFS_SLV_aktiv 0 "nicht_aktiv" 1 "Sitzlaengsverstellung aktiv" ;
VAL_ 1639 BFS_SHV_aktiv 0 "nicht_aktiv" 1 "Sitzhoehenverstellung aktiv" ;
VAL_ 1639 BFS_LNV_aktiv 0 "inaktiv" 1 "aktiv" ;
VAL_ 1639 BFS_SNV_aktiv 0 "nicht_aktiv" 1 "Sitzneigungsverstellung aktiv" ;
VAL_ 1639 BFS_KSV_aktiv 0 "nicht_aktiv" 1 "Kopfstuetzenverstellung aktiv" ;
VAL_ 1639 BFS_LKV_aktiv 0 "nicht_aktiv" 1 "aktiv" ;
VAL_ 1639 BFS_STV_aktiv 0 "inaktiv" 1 "Sitztiefeverstellung aktiv" ;
VAL_ 1639 BFS_LHV_aktiv 0 "inaktiv" 1 "aktiv" ;
VAL_ 1639 BFS_LWV_aktiv 0 "nicht_aktiv" 1 "aktiv" ;
VAL_ 1639 BFS_GHV_aktiv 0 "nicht_aktiv" 1 "Gurthoehe Verstellung aktiv" ;
VAL_ 1639 BFS_KSS_Fahrt_aktiv 0 "nicht_aktiv" 1 "Komfortseitensichtfahrt aktiv" ;
VAL_ 1639 BFS_MMB_lokal_Stop 0 "kein_Abbruch" 1 "lokaler_Abbruch" ;
VAL_ 1639 BFS_Ruhestellung_Status 0 "inakiv" 1 "Ruhestellung_aktiv" ;
VAL_ 1639 BFS_Seat_Locked 0 "nicht_gesperrt" 1 "gesperrt" ;
VAL_ 1639 BFS_MMB_storage 0 "keine Zuweisung" 1 "P1/FP1 Pos Zuweisung" 2 "P2/FP2 Pos Zuweisung" 3 "P3/FP3 Pos Zuweisung" 4 "P4/FP4 Pos Zuweisung an den im System aktiven Funkschlüssel/FPI ID über MMI" 5 "FS1" 6 "FS2" 7 "FS3" 8 "FS4" ;
VAL_ 1639 BFS_MMB_tipp 0 "kein_Tippbetrieb" 1 "Tippbetrieb" ;
VAL_ 1639 BFS_MMB_tast 0 "kein_Tastbetrieb" 1 "Tastbetrieb" ;
VAL_ 1639 BFS_MMB_store_LED_on 0 "LED_aus" 1 "LED_ein" ;
VAL_ 1639 BFS_MMB_storage_beep 0 "beep_aus" 1 "beep ein" ;
VAL_ 1639 BFS_MMB_store 0 "nicht speichern" 1 "speichern" ;
VAL_ 1639 BFS_MMB_glob_stop 0 "kein globaler Abbruch " 1 "globaler Abbruch" ;
VAL_ 957 Mem_BFSFo_Lordose_hoch 0 "Aus" 1 "Ein" ;
VAL_ 957 Mem_BFSFo_Lordose_runter 0 "Aus" 1 "Ein" ;
VAL_ 957 Mem_BFSFo_Lordose_vor 0 "Aus" 1 "Ein" ;
VAL_ 957 Mem_BFSFo_Lordose_zurueck 0 "Aus" 1 "Ein" ;
VAL_ 957 Mem_BFSFo_Massage_Geschw 0 "Aus" 1 "Stufe1" 2 "Stufe2" 3 "Stufe3" 4 "Stufe4" 5 "Stufe5" ;
VAL_ 957 Mem_BFSFo_Massage_Intens 0 "Aus" 1 "Stufe1" 2 "Stufe2" 3 "Stufe3" 4 "Stufe4" 5 "Stufe5" ;
VAL_ 957 Mem_BFSFo_MMB_storage 0 "keine_Zuweisung" 1 "P1/FP1_MemoryPos" 2 "P2/FP2_MemoryPos" 3 "P3/FP3_MemoryPos" ;
VAL_ 957 Mem_BFSFo_Massage_Prg 0 "Aus" 1 "Programm1" 2 "Programm2" 3 "Programm3" 4 "Programm4" 5 "Programm5" ;
VAL_ 957 Mem_BFSFo_MMB_tast 0 "kein_Tastbetrieb" 1 "Tastbetrieb" ;
VAL_ 957 Mem_BFSFo_MMB_tipp 0 "kein_Tippbetrieb" 1 "Tippbetrieb" ;
VAL_ 957 Mem_BFSFo_MMB_glob_Stop 0 "kein_Abbruch" 1 "Abbruch" ;
VAL_ 957 Mem_BFSFo_Sitztiefe_vor 0 "Aus" 1 "Ein" ;
VAL_ 957 Mem_BFSFo_Sitztiefe_zur 0 "Aus" 1 "Ein" ;
VAL_ 957 Mem_BFSFo_MMB_store 0 "nicht_speichern" 1 "speichern" ;
VAL_ 957 Mem_BFSFo_MMB_storage_beep 0 "Beep_aus" 1 "Beep_ein" ;
VAL_ 957 Mem_BFSFo_MMB_store_LED_on 0 "LED_aus" 1 "LED_ein" ;
VAL_ 957 Mem_BFSFo_BeifaSitzverstellung 0 "nicht_aktiv" 1 "aktiv" ;
VAL_ 957 Mem_BFSFo_MMB_lokal_Stop 0 "kein_Abbruch" 1 "lokaler_Abbruch" ;
VAL_ 957 Mem_BFSFo_Sitzfahrt_aktiv 0 "nicht_aktiv" 1 "Sitzfahrt_Aktiv" ;
VAL_ 957 Mem_BFSFo_BFS_Freigabe 0 "keine_Freigabe" 1 "Freigabe" ;
VAL_ 957 Mem_BFSFo_RSE_zurueck 0 "inaktiv" 1 "aktiv" ;
VAL_ 957 Mem_BFSFo_RSE_vor 0 "inaktiv" 1 "aktiv" ;
VAL_ 957 Mem_BFSFo_Business_anfahren 0 "inaktiv" 1 "Business_anfahren" ;
VAL_ 957 Mem_BFSFo_Relax_anfahren 0 "inaktiv" 1 "Relax_aktivieren" ;
VAL_ 957 BFS_Kopfstuetze_vor 0 "inaktiv" 1 "aktiv" ;
VAL_ 957 BFS_Kopfstuetze_zurueck 0 "inaktiv" 1 "aktiv" ;
VAL_ 957 Mem_BFSFo_BFS_RSE_Freigabe 0 "keine_Freigabe" 1 "Freigabe" ;
VAL_ 957 Mem_BFSFo_Fusstuetze_runter 0 "inaktiv" 1 "aktiv" ;
VAL_ 957 Mem_BFSFo_Fusstuetze_hoch 0 "inaktiv" 1 "aktiv" ;
VAL_ 1178 FS_Fond_Bed_enable 0 "disable" 1 "enable" ;
VAL_ 1178 FS_Lehne_nicht_verriegelt 0 "keine Anzeige" 1 "Lehne_nicht_verriegelt" ;
VAL_ 1178 FS_Spezialposition_anfahren 0 "Fkt_inaktiv" 1 "Fkt_aktiv" ;
VAL_ 1178 FS_BFS_Sitzsym_Anfahrt 0 "keine Sitzsymetrie Anfahrt BFS" 1 "Sitzsymetrie Anfahrt BFS" ;
VAL_ 1178 FS_Sitzfahrt_aktiv 0 "Sitz_nicht_in_Bewegung" 1 "Sitz_in_Bewegung" ;
VAL_ 1178 FS_SLV_aktiv 0 "nicht_aktiv" 1 "Sitzlaengsverstellung aktiv" ;
VAL_ 1178 FS_SHV_aktiv 0 "nicht_aktiv" 1 "Sitzhoehenverstellung aktiv" ;
VAL_ 1178 FS_LNV_aktiv 0 "nicht_aktiv" 1 "Lehnenneigungverstellung aktiv" ;
VAL_ 1178 FS_SNV_aktiv 0 "nicht_aktiv" 1 "Sitzneigungsverstellung_aktiv" ;
VAL_ 1178 FS_KSV_aktiv 0 "nicht_aktiv" 1 "Kopfstuetzenverstellung aktiv" ;
VAL_ 1178 FS_LKV_aktiv 0 "nicht_aktiv" 1 "Lehnenkopfverstellung aktiv" ;
VAL_ 1178 FS_STV_aktiv 0 "nicht_aktiv" 1 "Sitztiefeverstellung aktiv" ;
VAL_ 1178 FS_LHV_aktiv 0 "nicht_aktiv" 1 "Lordose Höhe Verstellung aktiv" ;
VAL_ 1178 FS_LWV_aktiv 0 "nicht_aktiv" 1 "Lordose W Verstellung aktiv" ;
VAL_ 1178 FS_GHV_aktiv 0 "nicht_aktiv" 1 "Gurthoehenverstellung aktiv" ;
VAL_ 1178 FS_BFS_KSS_Anfahrt 0 "keine Anfahrt KSS BFS" 1 "Anfahrt KSS BFS" ;
VAL_ 1178 FS_MMB_lokal_Stop 0 "kein_Abbruch" 1 "lokaler_Abbruch" ;
VAL_ 1178 FS_MMB_storage 0 "keine Zuweisung" 1 "P1/FP1 Pos Zuweisung" 2 "P2/FP2 Pos Zuweisung" 3 "P3/FP3 Pos Zuweisung" 4 "P4/FP4 Pos Zuweisung; an den im System aktiven Funkschlüssel/FPI ID über MMI" 5 "FS1" 6 "FS2" 7 "FS3" 8 "FS4" ;
VAL_ 1178 FS_MMB_tipp 0 "kein_Tippbetrieb" 1 "Tippbetrieb__automatisches Funkschlüsselmemory aktivieren;" ;
VAL_ 1178 FS_MMB_tast 0 "kein_Tastbetrieb" 1 "Tastbetrieb__Fingerprintautomatismus aktivieren über MMI" ;
VAL_ 1178 FS_MMB_store_LED_on 0 "LED_aus" 1 "LED_ein" ;
VAL_ 1178 FS_MMB_storage_beep 0 "beep aus" 1 "beep ein" ;
VAL_ 1178 FS_MMB_store 0 "nicht speichern__kein keyless verbaut" 1 "abspeichern__keyless verbaut" ;
VAL_ 1178 FS_MMB_glob_stop 0 "kein globaler Abbrucht" 1 "globaler Abbruch" ;
VAL_ 1178 FS_EE_Fond_FS_enable 0 "EE Fond links deaktiv" 1 "EE Fond links aktiv (default) vom MMI" ;
VAL_ 1178 FS_EE_Fond_BFS_enable 0 "EE Fond rechts deaktiv" 1 "EE Fond rechts aktiv (default) vom MMI" ;
VAL_ 1178 FS_EE_BFS_enable 0 "keine_EE_Freigabe" 1 "EE_Freigabe" ;
VAL_ 954 Mem_FS_Lordose_hoch 0 "Aus" 1 "Ein" ;
VAL_ 954 Mem_FS_Lordose_runter 0 "Aus" 1 "Ein" ;
VAL_ 954 Mem_FS_Lordose_vor 0 "Aus" 1 "Ein" ;
VAL_ 954 Mem_FS_Lordose_zurueck 0 "Aus" 1 "Ein" ;
VAL_ 954 Mem_FS_Massage_Geschw 0 "Aus" 1 "Stufe1" 2 "Stufe2" 3 "Stufe3" 4 "Stufe4" 5 "Stufe5" ;
VAL_ 954 Mem_FS_Massage_Intensitaet 0 "Aus" 1 "Stufe1" 2 "Stufe2" 3 "Stufe3" 4 "Stufe4" 5 "Stufe5" ;
VAL_ 954 Mem_FS_SWangenLehne_beluef 0 "Aus" 1 "Ein" ;
VAL_ 954 Mem_FS_SWangenLehne_entlue 0 "Aus" 1 "Ein" ;
VAL_ 954 Mem_FS_Massage_Programm 0 "Aus" 1 "Programm1" 2 "Programm2" 3 "Programm3" 4 "Programm4" 5 "Programm5" ;
VAL_ 954 Mem_FS_SWangenSitz_beluef 0 "Aus" 1 "Ein" ;
VAL_ 954 Mem_FS_SWangenSitz_entlue 0 "Aus" 1 "Ein" ;
VAL_ 954 FS_BFS_aufraeumen 0 "unbetaetigt" 1 "betaetigt" ;
VAL_ 954 FS_BFSFo_aufraeumen 0 "unbetaetigt" 1 "betaetigt" ;
VAL_ 954 FS_FSFo_aufraeumen 0 "unbetaetigt" 1 "betaetigt" ;
VAL_ 954 FS_BFS_Multifunktionstaster_hoch 0 "unbetaetigt" 1 "betaetigt" ;
VAL_ 954 FS_BFS_Multifunktionstaster_tief 0 "unbetaetigt" 1 "betaetigt" ;
VAL_ 954 FS_BFS_Multifunktionstaster_vor 0 "unbetaetigt" 1 "betaetigt" ;
VAL_ 954 FS_BFS_Multifunktionstaster_zur 0 "unbetaetigt" 1 "betaetigt" ;
VAL_ 954 FS_BFS_Programmwippe_hoch 0 "unbetaetigt" 1 "betaetigt" ;
VAL_ 954 FS_BFS_Programmwippe_tief 0 "unbetaetigt" 1 "betaetigt" ;
VAL_ 954 FS_BFS_SHV_Taste_hoch 0 "unbetaetigt" 1 "betaetigt" ;
VAL_ 954 FS_BFS_SHV_Taste_tief 0 "unbetaetigt" 1 "betaetigt" ;
VAL_ 954 FS_BFS_SLV_Taste_vor 0 "unbetaetigt" 1 "betaetigt" ;
VAL_ 954 FS_BFS_SLV_Taste_zurueck 0 "unbetaetigt" 1 "betaetigt" ;
VAL_ 954 FS_BFS_SNV_Taste_hoch 0 "unbetaetigt" 1 "betaetigt" ;
VAL_ 954 FS_BFS_SNV_Taste_tief 0 "unbetaetigt" 1 "betaetigt" ;
VAL_ 954 FS_BFS_KSV_Taste_hoch 0 "unbetaetigt" 1 "betaetigt" ;
VAL_ 954 FS_BFS_KSV_Taste_tief 0 "unbetaetigt" 1 "betaetigt" ;
VAL_ 954 FS_BFS_LNV_Taste_vor 0 "unbetaetigt" 1 "betaetigt" ;
VAL_ 954 FS_BFS_LNV_Taste_zurueck 0 "unbetaetigt" 1 "betaetigt" ;
VAL_ 954 FS_BFS_Massage_Taste 0 "unbetaetigt" 1 "betaetigt" ;
VAL_ 956 Mem_FSFo_Lordose_hoch 0 "Aus" 1 "Ein" ;
VAL_ 956 Mem_FSFo_Lordose_runter 0 "Aus" 1 "Ein" ;
VAL_ 956 Mem_FSFo_Lordose_vor 0 "Aus" 1 "Ein" ;
VAL_ 956 Mem_FSFo_Lordose_zurueck 0 "Aus" 1 "Ein" ;
VAL_ 956 Mem_FSFo_Massage_Geschw 0 "Aus" 1 "Stufe1" 2 "Stufe2" 3 "Stufe3" 4 "Stufe4" 5 "Stufe5" ;
VAL_ 956 Mem_FSFo_Massage_Intens 0 "Aus" 1 "Stufe1" 2 "Stufe2" 3 "Stufe3" 4 "Stufe4" 5 "Stufe5" ;
VAL_ 956 Mem_FSFo_MMB_storage 0 "keine_Zuweisung" 1 "P1/FP1_MemoryPos" 2 "P2/FP2_MemoryPos" 3 "P3/FP3_MemoryPos" ;
VAL_ 956 Mem_FSFo_Massage_Prg 0 "Aus" 1 "Programm1" 2 "Programm2" 3 "Programm3" 4 "Programm4" 5 "Programm5" ;
VAL_ 956 Mem_FSFo_MMB_tast 0 "kein_Tastbetrieb" 1 "Tastbetrieb" ;
VAL_ 956 Mem_FSFo_MMB_tipp 0 "kein_Tippbetrieb" 1 "Tippbetrieb" ;
VAL_ 956 Mem_FSFo_MMB_glob_Stop 0 "kein_Abbruch" 1 "Abbruch" ;
VAL_ 956 Mem_FSFo_Sitztiefe_vor 0 "Aus" 1 "Ein" ;
VAL_ 956 Mem_FSFo_Sitztiefe_zur 0 "Aus" 1 "Ein" ;
VAL_ 956 Mem_FSFo_MMB_store 0 "nicht_speichern" 1 "speichern" ;
VAL_ 956 Mem_FSFo_MMB_storage_beep 0 "Beep_aus" 1 "Beep_ein" ;
VAL_ 956 Mem_FSFo_MMB_store_LED_on 0 "LED_aus" 1 "LED_ein" ;
VAL_ 956 Mem_FSFo_MMB_lokal_Stop 0 "kein_Abbruch" 1 "lokaler_Abbruch" ;
VAL_ 956 Mem_FSFo_Sitzfahrt_aktiv 0 "nicht_aktiv" 1 "Sitzfahrt_Aktiv" ;
VAL_ 956 Mem_FSFo_Business_anfahren 0 "inaktiv" 1 "Business_anfahren" ;
VAL_ 956 Mem_FSFo_Relax_anfahren 0 "inaktiv" 1 "Relax_aktivieren" ;
VAL_ 1180 MTBT_Pos1 0 "Taste_nicht_gedrueckt" 1 "Postionstaste 1 BT gedrückt" ;
VAL_ 1180 MTBT_Pos2 0 "Taste_nicht_gedrueckt" 1 "Postionstaste 2 BT gedrückt" ;
VAL_ 1180 MTBT_Pos3 0 "Taste_nicht_gedrueckt" 1 "Postionstaste 3 BT gedrückt" ;
VAL_ 1180 MTBT_Pos4 0 "Taste_nicht_gedrueckt" 1 "Postionstaste 4 BT gedrückt" ;
VAL_ 1180 MTBT_On_Off 0 "Taste_nicht_gedrueckt" 1 "On-Off Taste BT gedrückt" ;
VAL_ 1180 MTBT_M_Taste 0 "Taste_nicht_gedrueckt" 1 " M-Taste BT gedrückt" ;
VAL_ 1170 MTFT_Pos1_EE 0 "Taste_nicht_gedrueckt" 1 "Postionstaste 1 FT gedrückt" ;
VAL_ 1170 MTFT_Pos2 0 "Taste_nicht_gedrueckt" 1 "Postionstaste 2 FT gedrückt" ;
VAL_ 1170 MTFT_Pos3 0 "Taste_nicht_gedrueckt" 1 "Postionstaste 3 FT gedrückt" ;
VAL_ 1170 MTFT_Pos4 0 "Taste_nicht_gedrueckt" 1 "Postionstaste 4 FT gedrückt" ;
VAL_ 1170 MTFT_On_Off 0 "Taste_nicht_gedrueckt" 1 "On-Off Taste FT gedrückt" ;
VAL_ 1170 MTFT_Verst_akt 0 "Verstellung nicht aktiv" 1 "Verstellung aktiv" ;
VAL_ 1170 MTFT_M_Taste 0 "Taste_nicht_gedrueckt" 1 "M-Taste FT gedrückt" ;
VAL_ 1173 BFS_Sitzhoehe_hoch 0 "aus" 1 "hoch" ;
VAL_ 1173 BFS_Sitzhoehe_runter 0 "aus" 1 "runter" ;
VAL_ 1173 MTHBF_ein 0 "aus" 1 "ein" ;
VAL_ 1173 BFS_Laengsverst_vor 0 "Taste_nicht_gedrueckt" 1 "Längsverstellung vor" ;
VAL_ 1173 BFS_Laengsverst_zurueck 0 "Taste_nicht_gedrueckt" 1 "Längsverstellung zurück (Wird bei Rechtslenker vom TSG HL gesendet)" ;
VAL_ 1173 BFS_Lehnenneigung_vor 0 "Taste_nicht_gedrueckt" 1 "Lehnenneigung vor (Wird bei Rechtslenker vom TSG HL gesendet)" ;
VAL_ 1173 BFS_Lehnenneigung_zurueck 0 "Taste_nicht_gedrueckt" 1 "Lehnenneigung zurück" ;
VAL_ 1173 BFS_Lehnenkopf_vor 0 "Taste_nicht_gedrueckt" 1 "Lehnenkopf vor " ;
VAL_ 1173 BFS_Lehnenkopf_zurueck 0 "Taste_nicht_gedrueckt" 1 "Lehnenkopf zurück" ;
VAL_ 1173 BFS_Kopfstuetzen_hoch 0 "Taste_nicht_gedrueckt" 1 "Kopfstützen hoch" ;
VAL_ 1173 BFS_Kopfstuetzen_runter 0 "Taste_nicht_gedrueckt" 1 "Kopfstützen runter" ;
VAL_ 1171 MF_ZV_Lock 0 "Locktaster_nicht_betaetigt" 1 "Locktaster_betaetigt" ;
VAL_ 1171 MF_Motorweiterlauf 0 "inaktiv" 1 "aktiv" ;
VAL_ 1171 MF_Abzugssperre 0 "inaktiv" 1 "aktiv" ;
VAL_ 1171 MF_Anlassersperre 0 "inaktiv" 1 "aktiv" ;
VAL_ 1171 MF_Variante 0 "keine_Sonderfunktion" 1 "Sondersignalfahrzeug" 2 "Taxi" 3 "Fahrhilfe" 4 "Fahrschule_Extra" 5 "SSF" 6 "DBMC" ;
VAL_ 1171 MF_Schluessel_scan 0 "inaktiv" 1 "aktiv" ;
VAL_ 1171 MF_Laderelais 0 "Relais_offen" 1 "Relais_geschlossen" ;
VAL_ 1171 MF_StartStopp_Info 0 "Motorlauf_nicht_notwendig_(Stoppfreigabe)" 1 "Motoranlauf_nicht_zwingend_notwendig_(Stoppverbot,keine_Startanforderung)" 2 "Motoranlauf_zwingend_notwendig_(Startanforderung)" 3 "Systemfehler" ;
VAL_ 1171 MF_Fernbed_ein 0 "inaktiv" 1 "aktiv" ;
VAL_ 1171 MF_Standlicht 0 "inaktiv" 1 "aktiv" ;
VAL_ 1171 MF_Fahrlicht 0 "inaktiv" 1 "aktiv" ;
VAL_ 1171 MF_interm_Fernlicht 0 "inaktiv" 1 "aktiv" ;
VAL_ 1171 MF_Warnblinker 0 "inaktiv" 1 "aktiv" ;
VAL_ 1171 MF_Fussraumbel 0 "inaktiv" 1 "aktiv" ;
VAL_ 1171 MF_Innenraumbel 0 "inaktiv" 1 "aktiv" ;
VAL_ 1171 MF_Innenraumbel_Unterdrueck 0 "inaktiv" 1 "aktiv" ;
VAL_ 1171 MF_Notstart 0 "kein_Notstart" 1 "Notstart" ;
VAL_ 1171 MF_Blk_li 0 "inaktiv" 1 "aktiv" ;
VAL_ 1171 MF_Blk_re 0 "inaktiv" 1 "aktiv" ;
VAL_ 1171 MF_Lichthupe 0 "inaktiv" 1 "aktiv" ;
VAL_ 1171 MF_Fernlicht 0 "inaktiv" 1 "aktiv" ;
VAL_ 1171 MF_HFS_verriegeln 0 "nicht_verriegeln" 1 "verriegeln" ;
VAL_ 1171 MF_HFS_entriegeln 0 "nicht_entriegeln" 1 "entriegeln" ;
VAL_ 1171 MF_HBFS_verriegeln 0 "nicht_verriegeln" 1 "verriegeln" ;
VAL_ 1171 MF_HBFS_entriegeln 0 "nicht entriegeln" 1 "entriegeln" ;
VAL_ 1171 MF_Tippwischen 0 "inaktiv" 1 "aktiv" ;
VAL_ 1171 MF_Frontintervall 0 "inaktiv" 1 "aktiv" ;
VAL_ 1171 MF_Wischerstufe_1 0 "inaktiv" 1 "aktiv" ;
VAL_ 1171 MF_Wischerstufe_2 0 "inaktiv" 1 "aktiv" ;
VAL_ 1171 MF_Frontwaschen 0 "inaktiv" 1 "aktiv" ;
VAL_ 1171 MF_Heckintervall 0 "inaktiv" 1 "aktiv" ;
VAL_ 1171 MF_Heckwaschen 0 "inaktiv" 1 "aktiv" ;
VAL_ 1171 MF_Summer 0 "inaktiv" 1 "aktiv" ;
VAL_ 1171 MF_Alarm_Blinkertakt 0 "inaktiv" 1 "aktiv" ;
VAL_ 1171 MF_Alarm_Blinker 0 "inaktiv" 1 "aktiv" ;
VAL_ 1171 MF_TFL_Abschaltung 0 "inaktiv" 1 "aktiv" ;
VAL_ 1171 MF_interm_Takt 0 "inaktiv" 1 "aktiv" ;
VAL_ 1171 MF_Tuerentriegelung_hinten 0 "inaktiv" 1 "aktiv" ;
VAL_ 1171 MF_interm_Fahrlicht 0 "inaktiv" 1 "aktiv" ;
VAL_ 1171 MF_Signalhorn 0 "inaktiv" 1 "aktiv" ;
VAL_ 1171 MF_FH_FT_hoch 0 "inaktiv" 1 "aktiv" ;
VAL_ 1171 MF_FH_FT_tief 0 "inaktiv" 1 "aktiv" ;
VAL_ 1171 MF_FH_BT_hoch 0 "inaktiv" 1 "aktiv" ;
VAL_ 1171 MF_FH_BT_tief 0 "inaktiv" 1 "aktiv" ;
VAL_ 1171 MF_FT_verriegeln 0 "nicht_verriegeln" 1 "verriegeln" ;
VAL_ 1171 MF_FT_entriegeln 0 "nicht_entriegeln" 1 "entriegeln" ;
VAL_ 1171 MF_BT_verriegeln 0 "nicht_verriegeln" 1 "verriegeln" ;
VAL_ 1171 MF_BT_entriegeln 0 "nicht_entriegeln" 1 "entriegeln" ;
VAL_ 817 MFL_Lokalaktiv 0 "war_nicht_lokal_aktiv" 1 "war_lokal_aktiv" ;
VAL_ 817 MFL_M_Taste 0 "nicht_betaetigt" 1 "betaetigt" ;
VAL_ 817 MFL_Tastencode_1 0 "Key_Released__No_Key" 1 "Context_Menu" 2 "Menu_Up__Next_Screen" 3 "Menu_Down__Previous_Screen" 4 "Up" 5 "Down" 6 "Up__Down_ThumbWheel" 7 "OK__ThumbWheel_Button" 8 "Cancel__Escape" 9 "Main_Menu" 10 "Side_Menu_left" 11 "Side_Menu_right" 12 "FAS_Menu" 16 "Volume_Up" 17 "Volume_Down" 18 "Volume_Up__Down_ThumbWheel" 19 "Volume_ThumbWheel_Button" 20 "Audio_Source" 21 "Arrow_A_Up__Right" 22 "Arrow_A_Down__Left" 23 "Arrow_B_Up__Right" 24 "Arrow_B_Down__Left" 25 "PTT__PushToTalk" 26 "PTT_Cancel" 27 "Route_Info" 28 "Hook" 29 "Hang_Up" 30 "Off_Hook" 31 "Light_On__Off" 32 "Mute" 33 "Joker1" 34 "Joker2" 35 "View" 100 "MAP" 101 "MAP_Boost" 102 "Turn_signal_left" 103 "Turn_signal_right" 104 "Turn_signal_off" 105 "Flashlight" 106 "Highbeam" 107 "Washer_button" 108 "Wiper_button_left" 109 "Wiper_button_right" 110 "Wiper_button_cancel" 111 "Exhaust_Sound" 112 "Drive_Select_button" 113 "Sport_button" 114 "ESP_Drift_Selection_ThumbWheel" 240 "Startup_Reset" 241 "Initialization" ;
VAL_ 817 MFL_Tastencode_2 0 "Key_Released__No_Key" 1 "Context_Menu" 2 "Menu_Up__Next_Screen" 3 "Menu_Down__Previous_Screen" 4 "Up" 5 "Down" 6 "Up__Down_ThumbWheel" 7 "OK__ThumbWheel_Button" 8 "Cancel__Escape" 9 "Main_Menu" 10 "Side_Menu_left" 11 "Side_Menu_right" 12 "FAS_Menu" 16 "Volume_Up" 17 "Volume_Down" 18 "Volume_Up__Down_ThumbWheel" 19 "Volume_ThumbWheel_Button" 20 "Audio_Source" 21 "Arrow_A_Up__Right" 22 "Arrow_A_Down__Left" 23 "Arrow_B_Up__Right" 24 "Arrow_B_Down__Left" 25 "PTT__PushToTalk" 26 "PTT_Cancel" 27 "Route_Info" 28 "Hook" 29 "Hang_Up" 30 "Off_Hook" 31 "Light_On__Off" 32 "Mute" 33 "Joker1" 34 "Joker2" 35 "View" 100 "MAP" 101 "MAP_Boost" 102 "Turn_signal_left" 103 "Turn_signal_right" 104 "Turn_signal_off" 105 "Flashlight" 106 "Highbeam" 107 "Washer_button" 108 "Wiper_button_left" 109 "Wiper_button_right" 110 "Wiper_button_cancel" 111 "Exhaust_Sound" 112 "Drive_Select_button" 113 "Sport_button" 114 "ESP_Drift_Selection_ThumbWheel" 240 "Startup_Reset" 241 "Initialization" ;
VAL_ 817 MFL_Eventcode_1 0 "Walze: no Event     | Taste: no Event" 1 "Walze: 1 Tick  up   | Taste: pressed" 2 "Walze: 2 Ticks up   | " 3 "Walze: 3 Ticks up   | Taste: double-click" 4 "Walze: 4 Ticks up   | Taste: long-press 1 [800ms]" 5 "Walze: 5 Ticks up   | Taste: long-press 2 [2s]" 6 "Walze: 6 Ticks up   | Taste: long-press 3 [3s]" 7 "Walze: 7 Ticks up   |" 9 "Walze: 7 Ticks down |" 10 "Walze: 6 Ticks down |" 11 "Walze: 5 Ticks down |" 12 "Walze: 4 Ticks down |" 13 "Walze: 3 Ticks down |" 14 "Walze: 2 Ticks down |" 15 "Walze: 1 Tick  down |" ;
VAL_ 817 MFL_Eventcode_2 0 "Walze: no Event     | Taste: no Event" 1 "Walze: 1 Tick  up   | Taste: pressed" 2 "Walze: 2 Ticks up   |  " 3 "Walze: 3 Ticks up   | Taste: double-click" 4 "Walze: 4 Ticks up   | Taste: long-press 1 [800ms]" 5 "Walze: 5 Ticks up   | Taste: long-press 2 [2s]" 6 "Walze: 6 Ticks up   | Taste: long-press 3 [3s]" 7 "Walze: 7 Ticks up   |" 9 "Walze: 7 Ticks down |" 10 "Walze: 6 Ticks down |" 11 "Walze: 5 Ticks down |" 12 "Walze: 4 Ticks down |" 13 "Walze: 3 Ticks down |" 14 "Walze: 2 Ticks down |" 15 "Walze: 1 Tick  down |" ;
VAL_ 817 MFL_Marke 0 "VW" 1 "Audi" 2 "Seat" 3 "Skoda" 4 "VW_Nutzf" 5 "Bugatti" 6 "Lamborghini" 7 "Bentley" 8 "Rolls Royce" 9 "Quattro" 10 "kein_Hersteller_1" 11 "kein_Hersteller_2" 12 "kein_Hersteller_3" 13 "kein_Hersteller_4" 14 "Ford" 15 "Porsche" ;
VAL_ 817 MFL_Tip_Down 0 "nicht_betaetigt" 1 "betaetigt" ;
VAL_ 817 MFL_Tip_Up 0 "nicht_betaetigt" 1 "betaetigt" ;
VAL_ 817 MFL_SatModul_links_Err 0 "kein_Fehler" 1 "Fehler" ;
VAL_ 817 MFL_SatModul_rechts_Err 0 "kein_Fehler" 1 "Fehler" ;
VAL_ 817 MFL_LR_HZG_Status 0 "inaktiv" 1 "aktiv" ;
VAL_ 817 MFL_LR_HZG_Err 0 "normal" 1 "Fehler" ;
VAL_ 817 MFL_Signalhorn 0 "nicht_betaetigt" 1 "betaetigt" ;
VAL_ 817 MFL_Signalhorn_Err 0 "normal" 1 "Fehler" ;
VAL_ 817 MFL_Tip_links_Err 0 "normal" 1 "Fehler" ;
VAL_ 817 MFL_Tip_rechts_Err 0 "normal" 1 "Fehler" ;
VAL_ 817 MFL_Taste_links_Err 0 "normal" 1 "Fehler" ;
VAL_ 817 MFL_Taste_rechts_Err 0 "normal" 1 "Fehler" ;
VAL_ 817 MFL_ECU_Err 0 "normal" 1 "Fehler" ;
VAL_ 817 MFL_Response_Err 0 "normal" 1 "Fehler" ;
VAL_ 349 MO2_Freigabe_Info_WFS 0 "ungueltig" 1 "gueltig" ;
VAL_ 349 MO2_Sperr_Info_WFS 0 "nicht_gesperrt" 1 "gesperrt" ;
VAL_ 349 MO2_Freigabe_Verfallsinfo_WFS 0 "verfaellt_nicht" 1 "verfaellt" ;
VAL_ 1600 MO_QBit_Ansaugluft_Temp 0 "gueltiger_Wert" 1 "Ersatz_Init_oder_Fehlerwert" ;
VAL_ 1600 MO_QBit_Oel_Temp 0 "gueltiger_Wert" 1 "Ersatz_Init_oder_Fehlerwert" ;
VAL_ 1600 MO_QBit_Kuehlmittel_Temp 0 "gueltiger_Wert" 1 "Ersatz_Init_oder_Fehlerwert" ;
VAL_ 1600 MO_KL15_Abschaltempfehlung 0 "Keine Empfehlung" 1 "Abschaltempfehlung" ;
VAL_ 1600 MO_HYB_Fehler_HV_Netz 0 "i_O" 1 "kein_generatorischer_Betrieb_moeglich" ;
VAL_ 1600 MO_aktives_Getriebeheizen 0 "kein_Ventil_ansteuern" 1 "Ventil_muss_angesteuert_werden" ;
VAL_ 1600 MO_Absperrventil_oeffnen 0 "nicht_verfuegbar" 1 "Ansteuerung_Ventil_zulaessig" 2 "Ventil_oeffnen_oder_geoeffnet" 3 "Ventil_schliessen_oder_geschlossen" ;
VAL_ 1600 MO_Ansaugluft_Temp 254 "Init" 255 "Fehler" ;
VAL_ 1600 MO_Oel_Temp 253 "nicht_verbaut" 254 "Init" 255 "Fehler" ;
VAL_ 1600 MO_Kuehlmittel_Temp 254 "Init" 255 "Fehler" ;
VAL_ 1600 MO_Hoeheninfo 255 "Fehler" ;
VAL_ 1600 MO_Kennfeldk 0 "keine Kennfeldkühlung vorhanden" 1 "Kennfeldkühlung vorhanden" ;
VAL_ 1600 MO_Versionsinfo_02 0 "zum_Projektbeginn_aufgeraeumter_CAN" 1 "Motor_03_mit_10ms" 16 "MQB_mit_neuer_Momentenschnittstelle" ;
VAL_ 1600 MO_QBit_Hoeheninfo 0 "gueltiger_Wert" 1 "Ersatz_Init_oder_Fehlerwert" ;
VAL_ 1600 MO_Getriebe_kuehlen 0 "nicht_kuehlen" 1 "kuehlen" ;
VAL_ 1600 MO_Heizungspumpenansteuerung 13 "Fehler" 14 "Init" 15 "nicht_verbaut" ;
VAL_ 1600 MO_SpannungsAnf 0 "keine_Anforderung" 1 "Anforderung" ;
VAL_ 1607 MO_ITM_Kuehlmittel_Temp 0 "nicht_verbaut" 1 "Init" 2 "Fehler" ;
VAL_ 1607 MO_E85_Sensor 13 "nicht_verbaut" 14 "Init" 15 "Fehler" ;
VAL_ 1607 SCR_Anz_Motorstarts 0 "Anzahl_moeglicher_Restarts" 1 "Anzahl_moeglicher_Restarts" 2 "Anzahl_moeglicher_Restarts" 3 "Anzahl_moeglicher_Restarts" 4 "Anzahl_moeglicher_Restarts" 5 "Anzahl_moeglicher_Restarts" 6 "Anzahl_moeglicher_Restarts" 7 "Anzahl_moeglicher_Restarts" 8 "Anzahl_moeglicher_Restarts" 9 "Anzahl_moeglicher_Restarts" 10 "Anzahl_moeglicher_Restarts" 11 "Anzahl_moeglicher_Restarts" 12 "Anzahl_moeglicher_Restarts" 13 "Anzahl_moeglicher_Restarts" 14 "Fahrbarkeitseinschraenkung" 15 "keine_Einschraenkung" ;
VAL_ 1607 SCR_Reichweite 32767 "keine_Anzeige" ;
VAL_ 1607 MO_Ethanol_Spuelhinweis 0 "Kein_Hinweis" 1 "Spuelhinweis_aktiv" ;
VAL_ 1607 SCR_Warnstufe_1 0 "nicht_aktiv" 1 "Warnstufe_1_aktiv" ;
VAL_ 1607 SCR_Warnstufe_2 0 "nicht_aktiv" 1 "Warnstufe_2_aktiv" ;
VAL_ 1607 SCR_Text 0 "kein_Text" 1 "Warntext_1" 2 "Warntext_2" 3 "Hinweis_Fuellstand" 4 "Reserve" 5 "SysFehler_1" 6 "SysFehler_2" 7 "Hinweis_Systemfehler" ;
VAL_ 1607 SCR_Akustik 0 "keine_Akustik" 1 "Akustik_1" 2 "Akustik_2" 3 "Akustik_bei_Hinweis" ;
VAL_ 1607 SCR_verbaut 0 "kein_SCR" 1 "SCR_verbaut" ;
VAL_ 1607 MO_Kraftstofffilter_Wasser 0 "keine_Anzeige" 1 "Abscheidevolumen_erschoepft" ;
VAL_ 1607 SCR_Systemfehler 0 "Warnung_nicht_aktiv" 1 "Warnung_aktiv" ;
VAL_ 1607 SCR_Inducement_Strategie 0 "Restart_Strategie" 1 "Reduced_Drivability_Strategie" ;
VAL_ 1607 MO_CO2_Faktor 0 "nicht_verbaut" 4095 "Fehler" ;
VAL_ 1607 MO_MKB_MUX 0 "MKB_01" 1 "MKB_02" 2 "MKB_03" 3 "MKB_04" ;
VAL_ 1607 MO_MKB_01 0 "Minus" 1 "A" 2 "B" 3 "C" 4 "D" 5 "E" 6 "F" 7 "G" 8 "H" 9 "I" 10 "J" 11 "K" 12 "L" 13 "M" 14 "N" 15 "O" 16 "P" 17 "Q" 18 "R" 19 "S" 20 "T" 21 "U" 22 "V" 23 "W" 24 "X" 25 "Y" 26 "Z" 27 "Leerzeichen" 28 "Leerzeichen" 29 "Leerzeichen" 30 "Leerzeichen" 31 "Unterstrich" ;
VAL_ 1607 MO_MKB_02 0 "Minus" 1 "A" 2 "B" 3 "C" 4 "D" 5 "E" 6 "F" 7 "G" 8 "H" 9 "I" 10 "J" 11 "K" 12 "L" 13 "M" 14 "N" 15 "O" 16 "P" 17 "Q" 18 "R" 19 "S" 20 "T" 21 "U" 22 "V" 23 "W" 24 "X" 25 "Y" 26 "Z" 27 "Leerzeichen" 28 "Leerzeichen" 29 "Leerzeichen" 30 "Leerzeichen" 31 "Unterstrich" ;
VAL_ 1607 MO_MKB_03 0 "Minus" 1 "A" 2 "B" 3 "C" 4 "D" 5 "E" 6 "F" 7 "G" 8 "H" 9 "I" 10 "J" 11 "K" 12 "L" 13 "M" 14 "N" 15 "O" 16 "P" 17 "Q" 18 "R" 19 "S" 20 "T" 21 "U" 22 "V" 23 "W" 24 "X" 25 "Y" 26 "Z" 27 "Leerzeichen" 28 "Leerzeichen" 29 "Leerzeichen" 30 "Leerzeichen" 31 "Unterstrich" ;
VAL_ 1607 MO_MKB_04 0 "Minus" 1 "A" 2 "B" 3 "C" 4 "D" 5 "E" 6 "F" 7 "G" 8 "H" 9 "I" 10 "J" 11 "K" 12 "L" 13 "M" 14 "N" 15 "O" 16 "P" 17 "Q" 18 "R" 19 "S" 20 "T" 21 "U" 22 "V" 23 "W" 24 "X" 25 "Y" 26 "Z" 27 "Leerzeichen" 28 "Leerzeichen" 29 "Leerzeichen" 30 "Leerzeichen" 31 "Unterstrich" ;
VAL_ 168 MO_Mom_neg_verfuegbar 510 "Init" 511 "Fehler" ;
VAL_ 168 MO_Mom_Begr_stat 510 "Init" ;
VAL_ 168 MO_Mom_Begr_dyn 1022 "Init" ;
VAL_ 168 MO_QBit_Drehzahl_01 0 "gueltiger_Wert" 1 "Ersatz_Init_oder_Fehlerwert" ;
VAL_ 958 MO_StartStopp_Status 0 "System_in_diesem_KL15_Zyklus_nicht_verfuegbar" 1 "System_aktiv_keine_Freigabe_durch_StartStop_Koordinator" 2 "System_aktiv_alle_Freigaben_liegen_vor" 3 "System_aktiv_mindestens_eine_Freigabe_fehlt" ;
VAL_ 958 MO_StartStopp_Wiederstart 0 "Wiederstart_inaktiv" 1 "Wiederstart_aktiv" ;
VAL_ 958 MO_StartStopp_Motorstopp 0 "Motor_Stop_inaktiv" 1 "Motor_Stop_aktiv" ;
VAL_ 958 MO_Freig_Reku 0 "Rekuperations-Modus aus" 1 "Empfehlung Spannungsanhebung" 2 "Empfehlung Spannungsabsenkung" 3 "Rekuperationsmodus aktiv, Spannungsvariation nicht notwendig" ;
VAL_ 958 MO_Kl_75 0 "Aus" 1 "Ein" ;
VAL_ 958 MO_Kl_50 0 "aus" 1 "KL50_ein_Startausfuehrung_Fahrer" ;
VAL_ 958 MO_Gangposition 0 "Gang_N" 1 "Gang_1" 2 "Gang_2" 3 "Gang_3" 4 "Gang_4" 5 "Gang_5" 6 "Gang_6" 7 "Gang_7" 8 "Gang_8" 9 "Automat_P" 10 "Automat_Vorwaerts_S" 11 "Automat_Vorwaerts_D/E" 12 "Zwischenstellung" 13 "Gang_R" 14 "Istgang_nicht_definiert" 15 "Fehler" ;
VAL_ 958 MO_StartStopp_Fahrerwunsch 0 "Init" 1 "Stoppverbot_durch_Fahrer" 2 "Stoppfreigabe_durch_Fahrer" 3 "Stoppanforderung_durch_Fahrer" ;
VAL_ 958 MO_HYB_Fahrbereitschaft 0 "keine_Fahrbereitschaft" 1 "Fahrbereitschaft" ;
VAL_ 958 MO_Ext_E_Fahrt_aktiv 0 "Rueckmeldung_E_Taster_aus" 1 "Rueckmeldung_E_Taster_ein" ;
VAL_ 958 MO_Fahrer_bremst 0 "kein_Bremsen" 1 "Bremse_betaetigt" ;
VAL_ 958 MO_QBit_Fahrer_bremst 0 "gueltiger_Wert" 1 "Ersatz_Init_oder_Fehlerwert" ;
VAL_ 958 MO_BLS 0 "kein_Bremsen" 1 "Bremse_betaetigt" ;
VAL_ 958 MO_Konsistenz_Bremsped 0 "Bremspedalinformation_plausibel" 1 "Bremspedalinformation_unplausibel" ;
VAL_ 958 MO_KomFehler_ESP 0 "kein_Fehler" 1 "Fehler" ;
VAL_ 958 MO_Klima_Eingr 0 "kein Eingriff" 1 "Klimakompressor ausschalten" 2 "Klimakompressor Leistungsreduzierung" 3 "Klimakompressor aufgrund der Heissleuchtenvorwarnung ausschalten" ;
VAL_ 958 MO_Aussp_Anlass 0 "Anlasser_darf_angesteuert_werden" 1 "Anlasser_ausspuren__Ansteuerung_nicht_moeglich" ;
VAL_ 958 MO_Freig_Anlass 0 "Start_nicht_zulaessig" 1 "Startfreigabe" ;
VAL_ 958 MO_Kuppl_schalter 0 "Schalter_sagt_ausgekuppelt" 1 "Schalter_sagt_eingekuppelt" ;
VAL_ 958 MO_Interlock 0 "Interlockschalter_nicht_betaetigt" 1 "Interlockschalter_betaetigt" ;
VAL_ 958 MO_Motor_laeuft 0 "Motor_laeuft_nicht" 1 "Motor_laeuft_autark_und_stabil_und_darf_mechanisch_belastet_werden" ;
VAL_ 958 MO_Kickdown 0 "kein_Kickdown" 1 "Kickdown" ;
VAL_ 958 MO_QBit_KL_75 0 "gueltiger_Wert" 1 "Ersatz_Init_oder_Fehlerwert" ;
VAL_ 958 MO_EKlKomLeiRed 0 "keine_Leistungsbegr" 1 "Leistungsbegr_75" 2 "Leistungsbegr_50" 3 "Leistungsbegr_25" ;
VAL_ 958 MO_Handshake_STH 0 "keine EKP-Ansteuerung durch STH-Anforderung" 1 "EKP-Ansteuerung durch STH-Anforderung" ;
VAL_ 958 MO_BKV_Unterdruckwarnung 0 "Unterdruckhaushalt_iO" 1 "Unterdruckhaushalt_niO" ;
VAL_ 958 MO_Freigabe_Segeln 0 "Segelbetrieb_nicht_freigegeben" 1 "Segelbetrieb_freigegeben" ;
VAL_ 958 MO_PTC_Status 0 "nicht_unterstuetzt" 1 "Stufe_0" 2 "Stufe_1" 3 "Stufe_2" 4 "Stufe_3" ;
VAL_ 958 MO_QBit_Gangposition 0 "gueltiger_Wert" 1 "Ersatz_Init_oder_Fehlerwert" ;
VAL_ 958 MO_Signalquelle_Gangposition 0 "Sensorsignal" 1 "Modellsignal" ;
VAL_ 958 MO_Remotestart_Betrieb 0 "MSG_nicht_bereit_fuer_RS_Betrieb" 1 "MSG_bereit_fuer_oder_im_RS_Betrieb" ;
VAL_ 958 MO_Zylinderabschaltung 0 "Vollmotorbetrieb_VMB" 1 "Uebergang_HMB_in_VMB" 2 "Uebergang_VMB_in_HMB" 3 "Halbmotorbetrieb_HMB" ;
VAL_ 958 MO_HYB_VM_aktiv 0 "VM_nicht_aktiv" 1 "VM_aktiv" ;
VAL_ 958 MO_StartVorauss_erfuellt 0 "Signal_nicht_bedient" 1 "StartVorauss_nicht_ueberpruefbar" 2 "StartVorauss_nicht_erfuellt" 3 "StartVorauss_erfuellt" ;
VAL_ 1648 MO_ANC_Kennfeld_Anf 0 "Kennfeld_1" 1 "Uebergang_Kennfeld_2_nach_1" 2 "Uebergang_Kennfeld_1_nach_2" 3 "Kennfeld_2" ;
VAL_ 1648 MO_Bremslicht_Reku 0 "Aus" 1 "Ein" ;
VAL_ 1648 MO_StartStopp_PopUp 0 "Statuswechsel_ohne_Taster (Init)" 1 "StSt_per_Taster_deaktiviert" 2 "StSt_per_Taster_aktiviert" 3 "nicht verwendet" ;
VAL_ 1648 MO1_Sperr_Info_WFS 0 "nicht_gesperrt" 1 "gesperrt" ;
VAL_ 1648 MO1_Freigabe_Info_WFS 0 "ungueltig" 1 "gueltig" ;
VAL_ 1648 MO_EPCL 0 "EPCL_aus_kein_Text" 1 "EPCL_gelb_Stoerung" 2 "EPCL_gelb_Leistungsbeschraenkung" 3 "EPCL_rot_Fzg_sicher_abstellen" ;
VAL_ 1648 MO_Zylabsch_Texte_02 0 "ein_ZAS_generell_keine_ZAS_Anzeigen" 1 "ZAS_im_VMB" 2 "ZAS_im_ASB_1_Zyl_aktiv" 3 "ZAS_im_ASB_2_Zyl_aktiv" 4 "ZAS_im_ASB_3_Zyl_aktiv" 5 "ZAS_im_ASB_4_Zyl_aktiv" 6 "ZAS_im_ASB_5_Zyl_aktiv" 7 "ZAS_im_ASB_6_Zyl_aktiv" 8 "ZAS_im_ASB_8_Zyl_aktiv" 9 "ZAS_im_ASB_12_Zyl_aktiv" 13 "Uebergangsbetrieb" 14 "keine_ZAS_Anzeige_ggf_Stopp_Schub_Betrieb" 15 "ZAS_Stoerungs_Anzeige" ;
VAL_ 1648 MO_Fahrzeugtyp 0 "Verbrenner_Fahrzeug" 1 "Hybrid" 2 "E_Fahrzeug" 3 "E_Fahrzeug_mit_Range_Extender" 4 "tbd" 5 "tbd" 6 "tbd" 7 "tbd" ;
VAL_ 1648 MO_Abstellzeit 254 "reserviert" 255 "reserviert" ;
VAL_ 1648 MO_Abstellzeit_Status 0 "Abstellzeit_nicht_berechnet" 1 "Abstellzeit_berechnet" 2 "Abstellzeit_Minimalwert" 3 "Abstellzeit_ungueltig" ;
VAL_ 1648 MO1_Freigabe_Verfallsinfo_WFS 0 "verfaellt_nicht" 1 "verfaellt" ;
VAL_ 1648 MO_Hybrid_StartStopp_LED 0 "LED_aus_und_Blinken_aus" 1 "LED_ein_und_Blinken_aus" 2 "LED_ein_und_Blinken_ein_50_percent" 3 "reserviert" ;
VAL_ 1648 MO_Fehler_Zylabsch 0 "kein_Fehler" 1 "Notlauf_Vollmotorbetrieb" 2 "Notlauf_mindestens_einem_abgesch_Zylinder" ;
VAL_ 1648 MO_Anzahl_Abgesch_Zyl 0 "Vollmotorbetrieb" 1 "1_Zylinder_abgeschaltet" 2 "2_Zylinder_abgeschaltet" 3 "3_Zylinder_abgeschaltet" 4 "4_Zylinder_abgeschaltet" 5 "5_Zylinder_abgeschaltet" 6 "6_Zylinder_abgeschaltet" 7 "8_Zylinder_abgeschaltet" ;
VAL_ 1648 MO_Zylabsch_Texte 0 "keine_Texte" 1 "Zylinderabschaltung_deaktivieren" 2 "Zylinderabschaltung_aktivieren" 3 "Zylinderabschaltung_unruhig" ;
VAL_ 1648 MO_Ethanol_BS_Texte 0 "kein_Text" 1 "E85_Warm_Up" 2 "FlexFuel_Warnung_Stufe_3" 3 "Warmfahrempfehlung_MQB__FlexFuel_Warnung_Stufe_1" 4 "FlexFuel_Warnung_Stufe_2" 5 "FlexFuel_Warnung_Stufe_4" 6 "E25_Warm_Up" ;
VAL_ 1648 MO_Drehzahl_Warnung 0 "keinen_Warnhinweis_anzeigen" 1 "Warnhinweis_anzeigen" ;
VAL_ 1648 MO_obere_Drehzahlgrenze 0 "Init" ;
VAL_ 289 MO_Fahrpedalrohwert_01 255 "Fehler" ;
VAL_ 289 MO_QBit_Fahrpedalwerte_01 0 "gueltiger_Wert" 1 "Ersatz_Init_oder_Fehlerwert" ;
VAL_ 289 MO_Fahrpedalgradient 255 "Fehler" ;
VAL_ 289 MO_Sig_Fahrpedalgradient 0 "Fahrpedalgradient positiv" 1 "Fahrpedalgradient negativ" ;
VAL_ 289 MO_rel_Saugrohrdruck 0 "Init_Ueberdruck" 63 "Fehler" ;
VAL_ 289 MO_rel_Saugrohrdruck_gem_err 0 "errechnet" 1 "gemessen" ;
VAL_ 289 MO_Moment_im_Leerlauf 0 "kein_Leergas" 1 "Leergas" ;
VAL_ 289 MO_Schubabschaltung 0 "keine_Schubabschaltung" 1 "Schubabschaltung_aktiv" ;
VAL_ 289 MO_StartStopp_StoppVorbereitung 0 "Motorstopp_nicht_in_Vorbereitung" 1 "Motorstopp_in_Vorbereitung" ;
VAL_ 289 MO_Entkopplung_Sollschlupf 126 "Init" ;
VAL_ 289 MO_temporaere_Fahrerabwesenheit 0 "nicht_erkannt" 1 "erkannt" ;
VAL_ 289 TSK_a_Soll_gradientenbegrenzt 127 "Init_oder_nicht_aktiv" ;
VAL_ 967 MO_Kuehlerluefter_MUX 0 "Kuehlerluefter_1" 1 "Kuehlerluefter_2" ;
VAL_ 967 MO_Kuehlerluefter_1 126 "Init" 127 "Fehler" ;
VAL_ 967 MO_Kuehlerluefter_2 126 "Init" 127 "Fehler" ;
VAL_ 967 MO_EFLEX_Lampe 0 "Lampe_aus" 1 "Lampe_ein" 2 "Lampe_blinkend" 3 "Lampe_blinkend_mit_Akustik" ;
VAL_ 967 MO_KJS_nicht_bereit 0 "kein_Fehler" 1 "Fehler" ;
VAL_ 967 MO_ITM_Warnung_Pumpe 0 "keine_Warnung" 1 "ITM_Warnung" ;
VAL_ 967 WIV_Anzeige_aktiv 0 "Anzeige aus" 1 "WIV Anzeige aktiv" ;
VAL_ 967 WIV_Oelmin_Warn 0 "in_Ordnung" 1 "Warnung" ;
VAL_ 967 WIV_Sensorfehler 0 "in_Ordnung" 1 "Sensor_defekt" ;
VAL_ 967 WIV_Schieflage 0 "Fahrzeug_gerade" 1 "Fahrzeug_in_Schieflage" ;
VAL_ 967 MO_Zustand_HWP 0 "HWP_nicht_schaltbar" 1 "HWP_foerdert_nicht" 2 "HWP_foerdert" 3 "reserviert" ;
VAL_ 967 OLEV_Systemstoerung 0 "Ölsystem i.O." 1 "Systemstörung Ölsystem" ;
VAL_ 967 MO_Oelwarnung_max 0 "keine_Warnung" 1 "Warnfall_aktiv" ;
VAL_ 967 WIV_Oelsystem_aktiv 0 "Anzeige_aus" 1 "Anzeige_aktiv" ;
VAL_ 967 WIV_nicht_betriebswarm 0 "Motor_warm" 1 "Motor_nicht_betriebswarm" ;
VAL_ 967 WIV_Ueberfuell_Warn 0 "in_Ordnung" 1 "Ueberfuellwarnung" ;
VAL_ 967 WIV_laufender_Motor 0 "Messung_moeglich" 1 "Messung_nicht_moeglich" ;
VAL_ 967 MO_E_Warnungen 0 "keine_Anzeige" 1 "Fehler_Elektrosystem_Anhalten" 2 "Fehler_Elektrosystem_Werkstatt" 3 "Elektrosystem_ueberhitzt_Stopp" 4 "Fehler_Hybridsystem_Anhalten" 5 "Fehler_Hybridsystem_Werkstatt" 6 "reserviert_keine_Anzeige" 7 "reserviert_keine_Anzeige" 8 "reserviert_keine_Anzeige" 9 "reserviert_keine_Anzeige" 10 "reserviert_keine_Anzeige" 11 "reserviert_keine_Anzeige" 12 "reserviert_keine_Anzeige" 13 "reserviert_keine_Anzeige" 14 "reserviert_keine_Anzeige" 15 "reserviert_keine_Anzeige" ;
VAL_ 967 MO_Text_Motorstart 0 "keine_Anzeige" 1 "Motor_im_Stoppbetrieb" 2 "StartStopp_sicherheitsbedingt_deaktiviert" 3 "System_fordert_Wiederstart" 5 "Motorlauf_noetig" 6 "Motorlaufwarnung" 9 "Unerwuenschter_Motorstillstand" 12 "Motor_startet" 13 "Kupplung_betaetigen" 14 "Waehlhebel_in_PN_Position" 15 "Bremse_treten" ;
VAL_ 967 MO_E_Texte 0 "keine_Anzeige" 1 "Batterie_fast_leer" 2 "Ladestecker_nicht_fahrbereit" 3 "VM_Betrieb_erforderlich" 4 "Batterie_laedt_Nicht_ausschalten" 5 "Bitte_Bremse_treten" 6 "manueller_Neustart_erforderlich" 7 "Stopp_Fahrzeug_nicht_abschleppen" 8 "kein_Neustart_Haube_nicht_oeffnen" 9 "Motorstart_im_naechsten_Zyklus" 10 "VM_erforderlich_EVMode_abwaehlen" 11 "laengerer_VMBetrieb_Bordbuch" 12 "Tank_leer_VM_nicht_verfuegbar" 13 "Bitte_warten_Motor_startet" 14 "reserviert_keine_Anzeige" 15 "reserviert_keine_Anzeige" ;
VAL_ 967 WIV_Oeldyn_avl 0 "Oeldyn_nicht_vorhanden" 1 "Oeldyn_vorhanden" ;
VAL_ 967 OLEV_Oelstand_nicht_vorhanden 0 "Ölstand vorhanden" 1 "Ölstand nicht vorhanden" ;
VAL_ 967 MO_Systemlampe 0 "Lampe aus" 1 "Lampe ein" ;
VAL_ 967 MO_OBD2_Lampe 0 "Lampe aus" 1 "Lampe ein" ;
VAL_ 967 MO_Heissleuchte 0 "Lampe aus" 1 "Lampe ein" ;
VAL_ 967 MO_Partikel_Lampe 0 "Lampe aus" 1 "Lampe ein" ;
VAL_ 967 MO_RedFahrleistung_Lampe 0 "Lampe_aus" 1 "Lampe_ein" ;
VAL_ 967 WIV_Oelstand_nicht_vorhanden 0 "Ölstand vorhanden" 1 "Ölstand nicht vorhanden" ;
VAL_ 967 WIV_nachfuellanzeige_ein 0 "keine_Nachfuellanzeige" 1 "Nachfuellanzeige" ;
VAL_ 967 WIV_Ueberfuell_deaktiv 0 "Ueberfuellwarnung_am_Kombi_aktiv" 1 "Ueberfuellwarnung_am_Kombi_deaktiv" ;
VAL_ 967 WIV_Unterfuell_Warn 0 "in_Ordnung" 1 "Unterfuellwarnung" ;
VAL_ 967 MO_Tankdeckel_Lampe 0 "Lampe aus" 1 "Lampe ein" ;
VAL_ 967 MO_Text_Tankdeckelwarn 0 "kein_Text" 1 "Anzeige_Text_Tankdeckelwarnung_im_Kombi" ;
VAL_ 967 MO_Vorglueh_Lampe 0 "Lampe_aus" 1 "Lampe_ein" ;
VAL_ 967 WIV_Oeldr_Warn_Motor 0 "keine_Warnung" 1 "niedrige_Oeldruckstufe_nicht_erreicht " ;
VAL_ 967 MO_E_Mode 0 "keine_Anzeige" 1 "E_Mode_passiv" 2 "E_Mode_aktiv" 3 "E_Mode_inaktiv_nicht_verfuegbar" 4 "E_Mode_aktiv_nicht_verfuegbar" 5 "reserviert_keine_Anzeige" 6 "reserviert_keine_Anzeige" 7 "reserviert_keine_Anzeige" ;
